VERSION ""

NS_ :

BS_:

BU_:

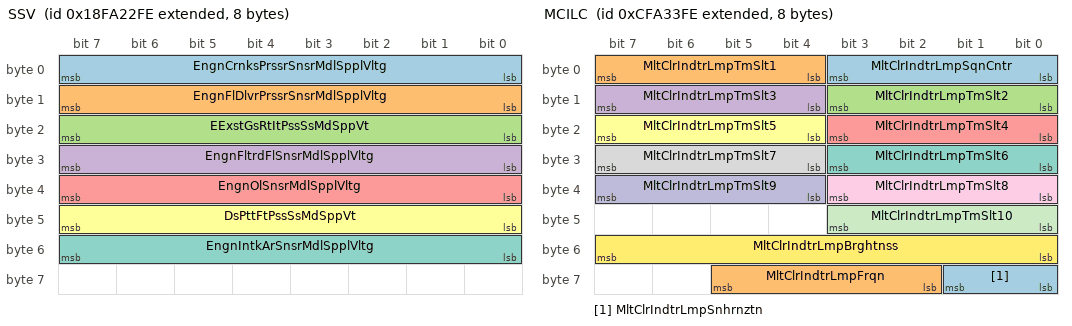
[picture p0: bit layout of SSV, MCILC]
BO_ 2566529790 SSV: 8 Vector__XXX
 SG_ EngnCrnksPrssrSnsrMdlSpplVltg : 0|8@1+ (0.05,0) [0|12.5] "V" Vector__XXX
 SG_ EngnFlDlvrPrssrSnsrMdlSpplVltg : 8|8@1+ (0.05,0) [0|12.5] "V" Vector__XXX
 SG_ EExstGsRtItPssSsMdSppVt : 16|8@1+ (0.05,0) [0|12.5] "V" Vector__XXX
 SG_ EngnFltrdFlSnsrMdlSpplVltg : 24|8@1+ (0.05,0) [0|12.5] "V" Vector__XXX
 SG_ EngnOlSnsrMdlSpplVltg : 32|8@1+ (0.05,0) [0|12.5] "V" Vector__XXX
 SG_ DsPttFtPssSsMdSppVt : 40|8@1+ (0.05,0) [0|12.5] "V" Vector__XXX
 SG_ EngnIntkArSnsrMdlSpplVltg : 48|8@1+ (0.05,0) [0|12.5] "V" Vector__XXX

BO_ 2365207550 MCILC: 8 Vector__XXX
 SG_ MltClrIndtrLmpSqnCntr : 0|4@1+ (1,0) [0|13] "count" Vector__XXX
 SG_ MltClrIndtrLmpTmSlt1 : 4|4@1+ (1,0) [0|15] "" Vector__XXX
 SG_ MltClrIndtrLmpTmSlt2 : 8|4@1+ (1,0) [0|15] "" Vector__XXX
 SG_ MltClrIndtrLmpTmSlt3 : 12|4@1+ (1,0) [0|15] "" Vector__XXX
 SG_ MltClrIndtrLmpTmSlt4 : 16|4@1+ (1,0) [0|15] "" Vector__XXX
 SG_ MltClrIndtrLmpTmSlt5 : 20|4@1+ (1,0) [0|15] "" Vector__XXX
 SG_ MltClrIndtrLmpTmSlt6 : 24|4@1+ (1,0) [0|15] "" Vector__XXX
 SG_ MltClrIndtrLmpTmSlt7 : 28|4@1+ (1,0) [0|15] "" Vector__XXX
 SG_ MltClrIndtrLmpTmSlt8 : 32|4@1+ (1,0) [0|15] "" Vector__XXX
 SG_ MltClrIndtrLmpTmSlt9 : 36|4@1+ (1,0) [0|15] "" Vector__XXX
 SG_ MltClrIndtrLmpTmSlt10 : 40|4@1+ (1,0) [0|15] "" Vector__XXX
 SG_ MltClrIndtrLmpBrghtnss : 48|8@1+ (1,0) [0|100] "%" Vector__XXX
 SG_ MltClrIndtrLmpSnhrnztn : 56|2@1+ (1,0) [0|3] "" Vector__XXX
 SG_ MltClrIndtrLmpFrqn : 58|4@1+ (1,0) [0|15] "" Vector__XXX

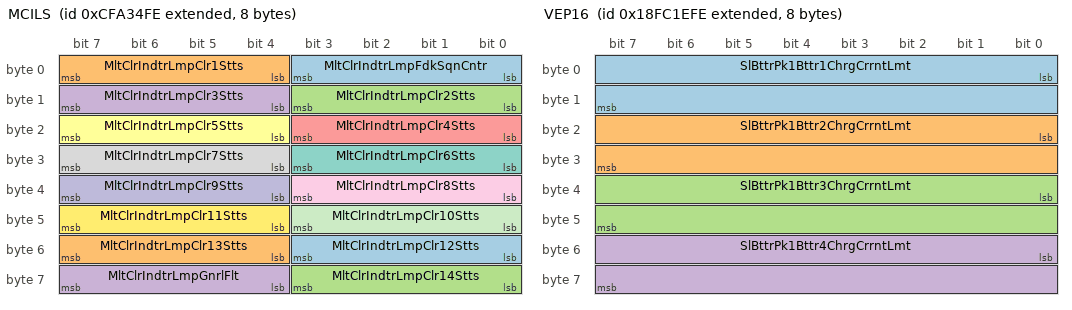
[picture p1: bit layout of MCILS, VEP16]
BO_ 2365207806 MCILS: 8 Vector__XXX
 SG_ MltClrIndtrLmpFdkSqnCntr : 0|4@1+ (1,0) [0|13] "count" Vector__XXX
 SG_ MltClrIndtrLmpClr1Stts : 4|4@1+ (1,0) [0|15] "" Vector__XXX
 SG_ MltClrIndtrLmpClr2Stts : 8|4@1+ (1,0) [0|15] "" Vector__XXX
 SG_ MltClrIndtrLmpClr3Stts : 12|4@1+ (1,0) [0|15] "" Vector__XXX
 SG_ MltClrIndtrLmpClr4Stts : 16|4@1+ (1,0) [0|15] "" Vector__XXX
 SG_ MltClrIndtrLmpClr5Stts : 20|4@1+ (1,0) [0|15] "" Vector__XXX
 SG_ MltClrIndtrLmpClr6Stts : 24|4@1+ (1,0) [0|15] "" Vector__XXX
 SG_ MltClrIndtrLmpClr7Stts : 28|4@1+ (1,0) [0|15] "" Vector__XXX
 SG_ MltClrIndtrLmpClr8Stts : 32|4@1+ (1,0) [0|15] "" Vector__XXX
 SG_ MltClrIndtrLmpClr9Stts : 36|4@1+ (1,0) [0|15] "" Vector__XXX
 SG_ MltClrIndtrLmpClr10Stts : 40|4@1+ (1,0) [0|15] "" Vector__XXX
 SG_ MltClrIndtrLmpClr11Stts : 44|4@1+ (1,0) [0|15] "" Vector__XXX
 SG_ MltClrIndtrLmpClr12Stts : 48|4@1+ (1,0) [0|15] "" Vector__XXX
 SG_ MltClrIndtrLmpClr13Stts : 52|4@1+ (1,0) [0|15] "" Vector__XXX
 SG_ MltClrIndtrLmpClr14Stts : 56|4@1+ (1,0) [0|15] "" Vector__XXX
 SG_ MltClrIndtrLmpGnrlFlt : 60|4@1+ (1,0) [0|15] "" Vector__XXX

BO_ 2566648574 EFS3: 8 Vector__XXX
 SG_ EngnFlFltrDffrntlPrssrHghRsltn : 0|16@1+ (0.01,0) [0|642.55] "kPa" Vector__XXX
 SG_ EFFtStSdDtPssHRst : 16|16@1+ (0.03125,-273) [-273|1734.96875] "degC" Vector__XXX

BO_ 2633761022 TWBW: 16 Vector__XXX
 SG_ BrkWrLfRmnngTrlrAxl1LftWhl : 0|8@1+ (0.4,0) [0|100] "%" Vector__XXX
 SG_ BrkWrLfRmnngTrlrAxl1RghtWhl : 8|8@1+ (0.4,0) [0|100] "%" Vector__XXX
 SG_ BrkWrLfRmnngTrlrAxl2LftWhl : 16|8@1+ (0.4,0) [0|100] "%" Vector__XXX
 SG_ BrkWrLfRmnngTrlrAxl2RghtWhl : 24|8@1+ (0.4,0) [0|100] "%" Vector__XXX
 SG_ BrkWrLfRmnngTrlrAxl3LftWhl : 32|8@1+ (0.4,0) [0|100] "%" Vector__XXX
 SG_ BrkWrLfRmnngTrlrAxl3RghtWhl : 40|8@1+ (0.4,0) [0|100] "%" Vector__XXX
 SG_ BrkWrLfRmnngTrlrAxl4LftWhl : 48|8@1+ (0.4,0) [0|100] "%" Vector__XXX
 SG_ BrkWrLfRmnngTrlrAxl4RghtWhl : 56|8@1+ (0.4,0) [0|100] "%" Vector__XXX
 SG_ BrkWrLfRmnngTrlrAxl5LftWhl : 64|8@1+ (0.4,0) [0|100] "%" Vector__XXX
 SG_ BrkWrLfRmnngTrlrAxl5RghtWhl : 72|8@1+ (0.4,0) [0|100] "%" Vector__XXX
 SG_ BrkWrLfRmnngTrlrAxl6LftWhl : 80|8@1+ (0.4,0) [0|100] "%" Vector__XXX
 SG_ BrkWrLfRmnngTrlrAxl6RghtWhl : 88|8@1+ (0.4,0) [0|100] "%" Vector__XXX
 SG_ BrkWrLfRmnngTrlrAxl7LftWhl : 96|8@1+ (0.4,0) [0|100] "%" Vector__XXX
 SG_ BrkWrLfRmnngTrlrAxl7RghtWhl : 104|8@1+ (0.4,0) [0|100] "%" Vector__XXX
 SG_ BrkWrLfRmnngTrlrAxl8LftWhl : 112|8@1+ (0.4,0) [0|100] "%" Vector__XXX
 SG_ BrkWrLfRmnngTrlrAxl8RghtWhl : 120|8@1+ (0.4,0) [0|100] "%" Vector__XXX

BO_ 2566659838 VEP16: 8 Vector__XXX
 SG_ SlBttrPk1Bttr1ChrgCrrntLmt : 0|16@1+ (0.05,-1600) [0|1600] "A" Vector__XXX
 SG_ SlBttrPk1Bttr2ChrgCrrntLmt : 16|16@1+ (0.05,-1600) [0|1600] "A" Vector__XXX
 SG_ SlBttrPk1Bttr3ChrgCrrntLmt : 32|16@1+ (0.05,-1600) [0|1600] "A" Vector__XXX
 SG_ SlBttrPk1Bttr4ChrgCrrntLmt : 48|16@1+ (0.05,-1600) [0|1600] "A" Vector__XXX

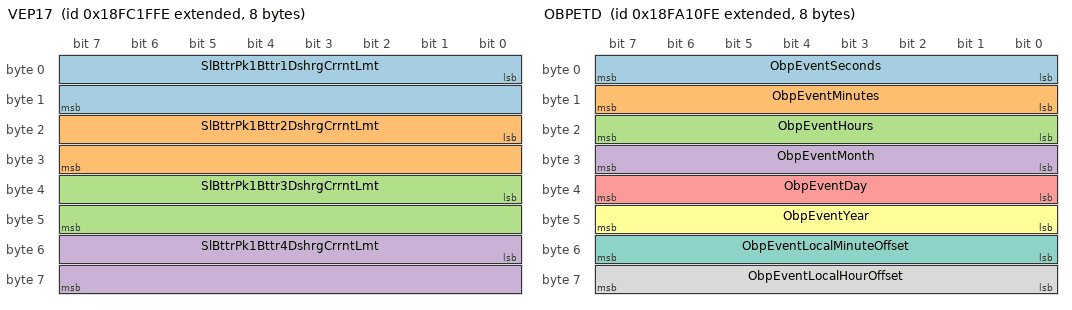
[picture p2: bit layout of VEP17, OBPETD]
BO_ 2566660094 VEP17: 8 Vector__XXX
 SG_ SlBttrPk1Bttr1DshrgCrrntLmt : 0|16@1+ (0.05,-1600) [-1600|0] "A" Vector__XXX
 SG_ SlBttrPk1Bttr2DshrgCrrntLmt : 16|16@1+ (0.05,-1600) [-1600|0] "A" Vector__XXX
 SG_ SlBttrPk1Bttr3DshrgCrrntLmt : 32|16@1+ (0.05,-1600) [-1600|0] "A" Vector__XXX
 SG_ SlBttrPk1Bttr4DshrgCrrntLmt : 48|16@1+ (0.05,-1600) [-1600|0] "A" Vector__XXX

BO_ 2565904382 MG1ITPS: 8 Vector__XXX
 SG_ MtrGnrtr1InvrtrThrmlCpltUsd : 0|8@1+ (0.4,0) [0|100] "%" Vector__XXX
 SG_ MtrGnrtr1InvrtrThrmlCpltLmt : 8|8@1+ (0.4,0) [0|100] "%" Vector__XXX

BO_ 2565904638 MG2ITPS: 8 Vector__XXX
 SG_ MtrGnrtr2InvrtrThrmlCpltUsd : 0|8@1+ (0.4,0) [0|100] "%" Vector__XXX
 SG_ MtrGnrtr2InvrtrThrmlCpltLmt : 8|8@1+ (0.4,0) [0|100] "%" Vector__XXX

BO_ 2565904894 MG3ITPS: 8 Vector__XXX
 SG_ MtrGnrtr3InvrtrThrmlCpltUsd : 0|8@1+ (0.4,0) [0|100] "%" Vector__XXX
 SG_ MtrGnrtr3InvrtrThrmlCpltLmt : 8|8@1+ (0.4,0) [0|100] "%" Vector__XXX

BO_ 2565905150 MG4ITPS: 8 Vector__XXX
 SG_ MtrGnrtr4InvrtrThrmlCpltUsd : 0|8@1+ (0.4,0) [0|100] "%" Vector__XXX
 SG_ MtrGnrtr4InvrtrThrmlCpltLmt : 8|8@1+ (0.4,0) [0|100] "%" Vector__XXX

BO_ 2565905406 MG5ITPS: 8 Vector__XXX
 SG_ MtrGnrtr5InvrtrThrmlCpltUsd : 0|8@1+ (0.4,0) [0|100] "%" Vector__XXX
 SG_ MtrGnrtr5InvrtrThrmlCpltLmt : 8|8@1+ (0.4,0) [0|100] "%" Vector__XXX

BO_ 2565905662 MG6ITPS: 8 Vector__XXX
 SG_ MtrGnrtr6InvrtrThrmlCpltUsd : 0|8@1+ (0.4,0) [0|100] "%" Vector__XXX
 SG_ MtrGnrtr6InvrtrThrmlCpltLmt : 8|8@1+ (0.4,0) [0|100] "%" Vector__XXX

BO_ 2565918462 ETCC4: 8 Vector__XXX
 SG_ EngnTrhrgrWstgtAttr3Cmmnd : 0|16@1+ (0.0025,0) [0|160.6375] "%" Vector__XXX
 SG_ EngnTrhrgrWstgtAttr4Cmmnd : 16|16@1+ (0.0025,0) [0|160.6375] "%" Vector__XXX

BO_ 2565918718 ETWAI2: 8 Vector__XXX
 SG_ EngnTrhrgrWstgtAttr3OprtnStts : 0|4@1+ (1,0) [0|15] "" Vector__XXX
 SG_ EngnTrhrgrWstgtAttr4OprtnStts : 4|4@1+ (1,0) [0|15] "" Vector__XXX

BO_ 2566523646 MG1TPS: 8 Vector__XXX
 SG_ MtrGnrtr1ThrmlCpltUsd : 0|8@1+ (0.4,0) [0|100] "%" Vector__XXX
 SG_ MtrGnrtr1ThrmlCpltLmt : 8|8@1+ (0.4,0) [0|100] "%" Vector__XXX

BO_ 2566523902 MG2TPS: 8 Vector__XXX
 SG_ MtrGnrtr2ThrmlCpltUsd : 0|8@1+ (0.4,0) [0|100] "%" Vector__XXX
 SG_ MtrGnrtr2ThrmlCpltLmt : 8|8@1+ (0.4,0) [0|100] "%" Vector__XXX

BO_ 2566524158 MG3TPS: 8 Vector__XXX
 SG_ MtrGnrtr3ThrmlCpltUsd : 0|8@1+ (0.4,0) [0|100] "%" Vector__XXX
 SG_ MtrGnrtr3ThrmlCpltLmt : 8|8@1+ (0.4,0) [0|100] "%" Vector__XXX

BO_ 2566524414 MG4TPS: 8 Vector__XXX
 SG_ MtrGnrtr4ThrmlCpltUsd : 0|8@1+ (0.4,0) [0|100] "%" Vector__XXX
 SG_ MtrGnrtr4ThrmlCpltLmt : 8|8@1+ (0.4,0) [0|100] "%" Vector__XXX

BO_ 2566524670 MG5TPS: 8 Vector__XXX
 SG_ MtrGnrtr5ThrmlCpltUsd : 0|8@1+ (0.4,0) [0|100] "%" Vector__XXX
 SG_ MtrGnrtr5ThrmlCpltLmt : 8|8@1+ (0.4,0) [0|100] "%" Vector__XXX

BO_ 2566524926 MG6TPS: 8 Vector__XXX
 SG_ MtrGnrtr6ThrmlCpltUsd : 0|8@1+ (0.4,0) [0|100] "%" Vector__XXX
 SG_ MtrGnrtr6ThrmlCpltLmt : 8|8@1+ (0.4,0) [0|100] "%" Vector__XXX

BO_ 2566525182 OBPETD: 8 Vector__XXX
 SG_ ObpEventSeconds : 0|8@1+ (0.25,0) [0|59.75] "s" Vector__XXX
 SG_ ObpEventMinutes : 8|8@1+ (1,0) [0|59] "min" Vector__XXX
 SG_ ObpEventHours : 16|8@1+ (1,0) [0|23] "h" Vector__XXX
 SG_ ObpEventMonth : 24|8@1+ (1,0) [1|12] "month" Vector__XXX
 SG_ ObpEventDay : 32|8@1+ (0.25,0) [0.25|31.75] "days" Vector__XXX
 SG_ ObpEventYear : 40|8@1+ (1,1985) [1985|2235] "year" Vector__XXX
 SG_ ObpEventLocalMinuteOffset : 48|8@1+ (1,-125) [-59|59] "min" Vector__XXX
 SG_ ObpEventLocalHourOffset : 56|8@1+ (1,-125) [-23|23] "h" Vector__XXX

BO_ 2566525438 A1LOSCRSI1: 8 Vector__XXX
 SG_ Atttt1TtLtOSDsExstFdUsd : 0|32@1+ (0.05,0) [0|210554060.75] "l" Vector__XXX
 SG_ Atttt1TpLtOSDsExstFd : 32|32@1+ (0.05,0) [0|210554060.75] "l" Vector__XXX

BO_ 2566525950 CSERSC: 20 Vector__XXX
 SG_ CtCCtstHtEUtFtpCdSttTT : 0|16@1+ (1,0) [0|64255] "kJ" Vector__XXX
 SG_ CtCCtstHtEUtFtpEOtptE : 16|16@1+ (1,0) [0|64255] "kJ" Vector__XXX
 SG_ CtCCtstHtEUtCtstCdSttTTptTsd : 32|16@1+ (1,0) [0|64255] "kJ" Vector__XXX
 SG_ CtCEOtptEUtFtpCdSttTT : 48|16@1+ (5,0) [0|321275] "kJ" Vector__XXX
 SG_ CtCEOtptEUtCtstCdSttTTptTsd : 64|16@1+ (5,0) [0|321275] "kJ" Vector__XXX
 SG_ CtCEMssUtFtpCdSttTT : 80|16@1+ (5,0) [0|321275] "g" Vector__XXX
 SG_ CtCEMssUtFtpEOtptE : 96|16@1+ (5,0) [0|321275] "g" Vector__XXX
 SG_ CtCEMssUtCdSttTCtstTptTsd : 112|16@1+ (5,0) [0|321275] "g" Vector__XXX
 SG_ CrrntClTmUntlFtpEngnOtptEnrg : 128|16@1+ (1,0) [0|64255] "s" Vector__XXX
 SG_ CtCTUtCtstCdSttTTptTsd : 144|16@1+ (1,0) [0|64255] "s" Vector__XXX

BO_ 2566526206 CSERSA: 20 Vector__XXX
 SG_ AvCtstHtEUtFtpCdSttTT : 0|16@1+ (1,0) [0|64255] "kJ" Vector__XXX
 SG_ AvCtstHtEUtFtpEOtptE : 16|16@1+ (1,0) [0|64255] "kJ" Vector__XXX
 SG_ AvCtstHtEUtCtstCdSttTTptTsd : 32|16@1+ (1,0) [0|64255] "kJ" Vector__XXX
 SG_ AvEOtptEUtFtpCdSttTT : 48|16@1+ (5,0) [0|321275] "kJ" Vector__XXX
 SG_ AvEOtptEUtCdSttTCtstTptTsd : 64|16@1+ (5,0) [0|321275] "kJ" Vector__XXX
 SG_ AvrgEgrMssAtFtpCldStrtTrkngTm : 80|16@1+ (5,0) [0|321275] "g" Vector__XXX
 SG_ AvrgEgrMssAtFtpEngnOtptEnrg : 96|16@1+ (5,0) [0|321275] "g" Vector__XXX
 SG_ AvEMssUtFtpCdSttTCtstTpt : 112|16@1+ (5,0) [0|321275] "g" Vector__XXX
 SG_ AvrgTmUntlFtpEngnOtptEnrg : 128|16@1+ (1,0) [0|64255] "s" Vector__XXX
 SG_ AvTUtCtstCdSttTTpt : 144|16@1+ (1,0) [0|64255] "s" Vector__XXX

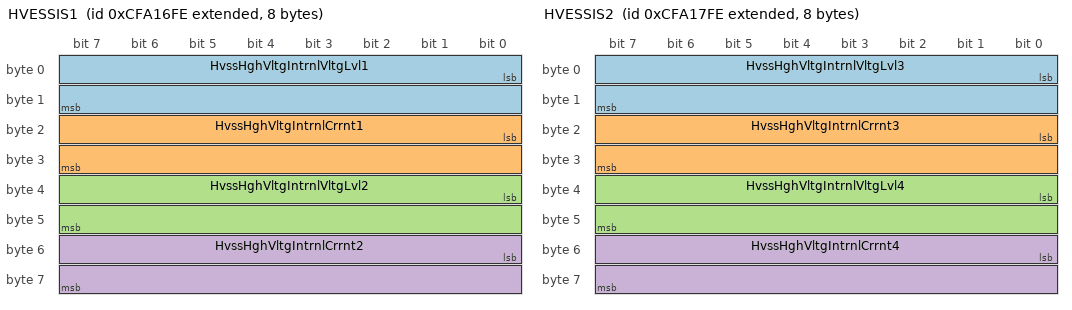
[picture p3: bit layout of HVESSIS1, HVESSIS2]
BO_ 2365200126 HVESSIS1: 8 Vector__XXX
 SG_ HvssHghVltgIntrnlVltgLvl1 : 0|16@1+ (0.125,0) [0|8031.875] "V" Vector__XXX
 SG_ HvssHghVltgIntrnlCrrnt1 : 16|16@1+ (0.125,-4000) [-4000|4031.875] "A" Vector__XXX
 SG_ HvssHghVltgIntrnlVltgLvl2 : 32|16@1+ (0.125,0) [0|8031.875] "V" Vector__XXX
 SG_ HvssHghVltgIntrnlCrrnt2 : 48|16@1+ (0.125,-4000) [-4000|4031.875] "A" Vector__XXX

BO_ 2365200382 HVESSIS2: 8 Vector__XXX
 SG_ HvssHghVltgIntrnlVltgLvl3 : 0|16@1+ (0.125,0) [0|8031.875] "V" Vector__XXX
 SG_ HvssHghVltgIntrnlCrrnt3 : 16|16@1+ (0.125,-4000) [-4000|4031.875] "A" Vector__XXX
 SG_ HvssHghVltgIntrnlVltgLvl4 : 32|16@1+ (0.125,0) [0|8031.875] "V" Vector__XXX
 SG_ HvssHghVltgIntrnlCrrnt4 : 48|16@1+ (0.125,-4000) [-4000|4031.875] "A" Vector__XXX

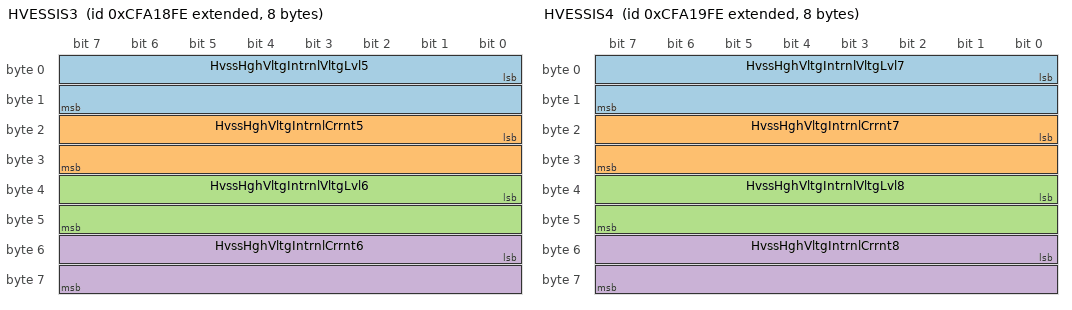
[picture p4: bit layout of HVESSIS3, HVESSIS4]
BO_ 2365200638 HVESSIS3: 8 Vector__XXX
 SG_ HvssHghVltgIntrnlVltgLvl5 : 0|16@1+ (0.125,0) [0|8031.875] "V" Vector__XXX
 SG_ HvssHghVltgIntrnlCrrnt5 : 16|16@1+ (0.125,-4000) [-4000|4031.875] "A" Vector__XXX
 SG_ HvssHghVltgIntrnlVltgLvl6 : 32|16@1+ (0.125,0) [0|8031.875] "V" Vector__XXX
 SG_ HvssHghVltgIntrnlCrrnt6 : 48|16@1+ (0.125,-4000) [-4000|4031.875] "A" Vector__XXX

BO_ 2365200894 HVESSIS4: 8 Vector__XXX
 SG_ HvssHghVltgIntrnlVltgLvl7 : 0|16@1+ (0.125,0) [0|8031.875] "V" Vector__XXX
 SG_ HvssHghVltgIntrnlCrrnt7 : 16|16@1+ (0.125,-4000) [-4000|4031.875] "A" Vector__XXX
 SG_ HvssHghVltgIntrnlVltgLvl8 : 32|16@1+ (0.125,0) [0|8031.875] "V" Vector__XXX
 SG_ HvssHghVltgIntrnlCrrnt8 : 48|16@1+ (0.125,-4000) [-4000|4031.875] "A" Vector__XXX

BO_ 2432310014 EEC23: 8 Vector__XXX
 SG_ EngnCrnksPrssrCntrlAttr1Cmmnd : 0|16@1+ (0.0025,0) [0|160.6375] "%" Vector__XXX
 SG_ EngnCrnksPrssrCntrlAttr2Cmmnd : 16|16@1+ (0.0025,0) [0|160.6375] "%" Vector__XXX

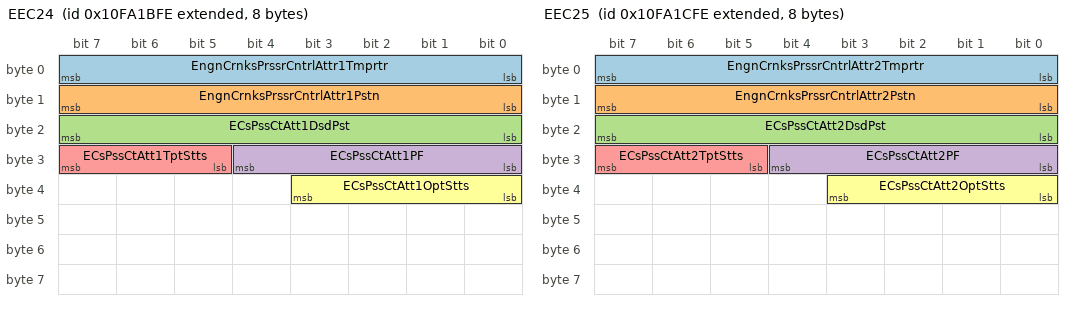
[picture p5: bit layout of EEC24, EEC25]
BO_ 2432310270 EEC24: 8 Vector__XXX
 SG_ EngnCrnksPrssrCntrlAttr1Tmprtr : 0|8@1+ (1,-40) [-40|210] "degC" Vector__XXX
 SG_ EngnCrnksPrssrCntrlAttr1Pstn : 8|8@1+ (0.4,0) [0|100] "%" Vector__XXX
 SG_ ECsPssCtAtt1DsdPst : 16|8@1+ (0.4,0) [0|100] "%" Vector__XXX
 SG_ ECsPssCtAtt1PF : 24|5@1+ (1,0) [0|31] "" Vector__XXX
 SG_ ECsPssCtAtt1TptStts : 29|3@1+ (1,0) [0|7] "" Vector__XXX
 SG_ ECsPssCtAtt1OptStts : 32|4@1+ (1,0) [0|15] "" Vector__XXX

BO_ 2432310526 EEC25: 8 Vector__XXX
 SG_ EngnCrnksPrssrCntrlAttr2Tmprtr : 0|8@1+ (1,-40) [-40|210] "degC" Vector__XXX
 SG_ EngnCrnksPrssrCntrlAttr2Pstn : 8|8@1+ (0.4,0) [0|100] "%" Vector__XXX
 SG_ ECsPssCtAtt2DsdPst : 16|8@1+ (0.4,0) [0|100] "%" Vector__XXX
 SG_ ECsPssCtAtt2PF : 24|5@1+ (1,0) [0|31] "" Vector__XXX
 SG_ ECsPssCtAtt2TptStts : 29|3@1+ (1,0) [0|7] "" Vector__XXX
 SG_ ECsPssCtAtt2OptStts : 32|4@1+ (1,0) [0|15] "" Vector__XXX

BO_ 2365201918 HVBCC1: 8 Vector__XXX
 SG_ HghVltgBsIntrf1CnntCmmnd : 0|2@1+ (1,0) [0|3] "" Vector__XXX
 SG_ HghVltgBsIntrf2CnntCmmnd : 2|2@1+ (1,0) [0|3] "" Vector__XXX
 SG_ HghVltgBsIntrf3CnntCmmnd : 4|2@1+ (1,0) [0|3] "" Vector__XXX
 SG_ HghVltgBsIntrf4CnntCmmnd : 6|2@1+ (1,0) [0|3] "" Vector__XXX
 SG_ HghVltgBsIntrf5CnntCmmnd : 8|2@1+ (1,0) [0|3] "" Vector__XXX
 SG_ HghVltgBsIntrf6CnntCmmnd : 10|2@1+ (1,0) [0|3] "" Vector__XXX
 SG_ HghVltgBsIntrf7CnntCmmnd : 12|2@1+ (1,0) [0|3] "" Vector__XXX
 SG_ HghVltgBsIntrf8CnntCmmnd : 14|2@1+ (1,0) [0|3] "" Vector__XXX
 SG_ HghVltgBsIntrf9CnntCmmnd : 16|2@1+ (1,0) [0|3] "" Vector__XXX
 SG_ HghVltgBsIntrf10CnntCmmnd : 18|2@1+ (1,0) [0|3] "" Vector__XXX
 SG_ HghVltgBsIntrf11CnntCmmnd : 20|2@1+ (1,0) [0|3] "" Vector__XXX
 SG_ HghVltgBsIntrf12CnntCmmnd : 22|2@1+ (1,0) [0|3] "" Vector__XXX
 SG_ HghVltgBsIntrf13CnntCmmnd : 24|2@1+ (1,0) [0|3] "" Vector__XXX
 SG_ HghVltgBsIntrf14CnntCmmnd : 26|2@1+ (1,0) [0|3] "" Vector__XXX
 SG_ HghVltgBsIntrf15CnntCmmnd : 28|2@1+ (1,0) [0|3] "" Vector__XXX
 SG_ HghVltgBsIntrf16CnntCmmnd : 30|2@1+ (1,0) [0|3] "" Vector__XXX
 SG_ HghVltgBsIntrf17CnntCmmnd : 32|2@1+ (1,0) [0|3] "" Vector__XXX
 SG_ HghVltgBsIntrf18CnntCmmnd : 34|2@1+ (1,0) [0|3] "" Vector__XXX
 SG_ HghVltgBsIntrf19CnntCmmnd : 36|2@1+ (1,0) [0|3] "" Vector__XXX
 SG_ HghVltgBsIntrf20CnntCmmnd : 38|2@1+ (1,0) [0|3] "" Vector__XXX
 SG_ HghVltgBsIntrf21CnntCmmnd : 40|2@1+ (1,0) [0|3] "" Vector__XXX
 SG_ HghVltgBsIntrf22CnntCmmnd : 42|2@1+ (1,0) [0|3] "" Vector__XXX
 SG_ HghVltgBsIntrf23CnntCmmnd : 44|2@1+ (1,0) [0|3] "" Vector__XXX
 SG_ HghVltgBsIntrf24CnntCmmnd : 46|2@1+ (1,0) [0|3] "" Vector__XXX
 SG_ Hvbcc1EmbeddedIntegritySupport : 50|2@1+ (1,0) [0|3] "" Vector__XXX
 SG_ Hvbcc1Counter : 52|4@1+ (1,0) [0|15] "" Vector__XXX
 SG_ Hvbcc1Crc : 56|8@1+ (1,0) [0|250] "count" Vector__XXX

BO_ 2365202174 HVBCS1: 8 Vector__XXX
 SG_ HghVltgBsIntrf1PstvCnttrStt : 0|2@1+ (1,0) [0|3] "" Vector__XXX
 SG_ HghVltgBsIntrf1NgtvCnttrStt : 2|2@1+ (1,0) [0|3] "" Vector__XXX
 SG_ HghVltgBsIntrf2PstvCnttrStt : 4|2@1+ (1,0) [0|3] "" Vector__XXX
 SG_ HghVltgBsIntrf2NgtvCnttrStt : 6|2@1+ (1,0) [0|3] "" Vector__XXX
 SG_ HghVltgBsIntrf3PstvCnttrStt : 8|2@1+ (1,0) [0|3] "" Vector__XXX
 SG_ HghVltgBsIntrf3NgtvCnttrStt : 10|2@1+ (1,0) [0|3] "" Vector__XXX
 SG_ HghVltgBsIntrf4PstvCnttrStt : 12|2@1+ (1,0) [0|3] "" Vector__XXX
 SG_ HghVltgBsIntrf4NgtvCnttrStt : 14|2@1+ (1,0) [0|3] "" Vector__XXX
 SG_ HghVltgBsIntrf5PstvCnttrStt : 16|2@1+ (1,0) [0|3] "" Vector__XXX
 SG_ HghVltgBsIntrf5NgtvCnttrStt : 18|2@1+ (1,0) [0|3] "" Vector__XXX
 SG_ HghVltgBsIntrf6PstvCnttrStt : 20|2@1+ (1,0) [0|3] "" Vector__XXX
 SG_ HghVltgBsIntrf6NgtvCnttrStt : 22|2@1+ (1,0) [0|3] "" Vector__XXX
 SG_ HghVltgBsIntrf7PstvCnttrStt : 24|2@1+ (1,0) [0|3] "" Vector__XXX
 SG_ HghVltgBsIntrf7NgtvCnttrStt : 26|2@1+ (1,0) [0|3] "" Vector__XXX
 SG_ HghVltgBsIntrf8PstvCnttrStt : 28|2@1+ (1,0) [0|3] "" Vector__XXX
 SG_ HghVltgBsIntrf8NgtvCnttrStt : 30|2@1+ (1,0) [0|3] "" Vector__XXX
 SG_ Hvbcs1EmbeddedIntegritySupport : 50|2@1+ (1,0) [0|3] "" Vector__XXX
 SG_ Hvbcs1Counter : 52|4@1+ (1,0) [0|15] "" Vector__XXX
 SG_ Hvbcs1Crc : 56|8@1+ (1,0) [0|250] "count" Vector__XXX

BO_ 2365333758 HVESSMS2: 8 Vector__XXX
 SG_ HvessModule33OperationalStatus : 0|2@1+ (1,0) [0|3] "" Vector__XXX
 SG_ HvessModule34OperationalStatus : 2|2@1+ (1,0) [0|3] "" Vector__XXX
 SG_ HvessModule35OperationalStatus : 4|2@1+ (1,0) [0|3] "" Vector__XXX
 SG_ HvessModule36OperationalStatus : 6|2@1+ (1,0) [0|3] "" Vector__XXX
 SG_ HvessModule37OperationalStatus : 8|2@1+ (1,0) [0|3] "" Vector__XXX
 SG_ HvessModule38OperationalStatus : 10|2@1+ (1,0) [0|3] "" Vector__XXX
 SG_ HvessModule39OperationalStatus : 12|2@1+ (1,0) [0|3] "" Vector__XXX
 SG_ HvessModule40OperationalStatus : 14|2@1+ (1,0) [0|3] "" Vector__XXX
 SG_ HvessModule41OperationalStatus : 16|2@1+ (1,0) [0|3] "" Vector__XXX
 SG_ HvessModule42OperationalStatus : 18|2@1+ (1,0) [0|3] "" Vector__XXX
 SG_ HvessModule43OperationalStatus : 20|2@1+ (1,0) [0|3] "" Vector__XXX
 SG_ HvessModule44OperationalStatus : 22|2@1+ (1,0) [0|3] "" Vector__XXX
 SG_ HvessModule45OperationalStatus : 24|2@1+ (1,0) [0|3] "" Vector__XXX
 SG_ HvessModule46OperationalStatus : 26|2@1+ (1,0) [0|3] "" Vector__XXX
 SG_ HvessModule47OperationalStatus : 28|2@1+ (1,0) [0|3] "" Vector__XXX
 SG_ HvessModule48OperationalStatus : 30|2@1+ (1,0) [0|3] "" Vector__XXX
 SG_ HvessModule49OperationalStatus : 32|2@1+ (1,0) [0|3] "" Vector__XXX
 SG_ HvessModule50OperationalStatus : 34|2@1+ (1,0) [0|3] "" Vector__XXX
 SG_ HvessModule51OperationalStatus : 36|2@1+ (1,0) [0|3] "" Vector__XXX
 SG_ HvessModule52OperationalStatus : 38|2@1+ (1,0) [0|3] "" Vector__XXX
 SG_ HvessModule53OperationalStatus : 40|2@1+ (1,0) [0|3] "" Vector__XXX
 SG_ HvessModule54OperationalStatus : 42|2@1+ (1,0) [0|3] "" Vector__XXX
 SG_ HvessModule55OperationalStatus : 44|2@1+ (1,0) [0|3] "" Vector__XXX
 SG_ HvessModule56OperationalStatus : 46|2@1+ (1,0) [0|3] "" Vector__XXX
 SG_ HvessModule57OperationalStatus : 48|2@1+ (1,0) [0|3] "" Vector__XXX
 SG_ HvessModule58OperationalStatus : 50|2@1+ (1,0) [0|3] "" Vector__XXX
 SG_ HvessModule59OperationalStatus : 52|2@1+ (1,0) [0|3] "" Vector__XXX
 SG_ HvessModule60OperationalStatus : 54|2@1+ (1,0) [0|3] "" Vector__XXX
 SG_ HvessModule61OperationalStatus : 56|2@1+ (1,0) [0|3] "" Vector__XXX
 SG_ HvessModule62OperationalStatus : 58|2@1+ (1,0) [0|3] "" Vector__XXX
 SG_ HvessModule63OperationalStatus : 60|2@1+ (1,0) [0|3] "" Vector__XXX
 SG_ HvessModule64OperationalStatus : 62|2@1+ (1,0) [0|3] "" Vector__XXX

BO_ 2365334014 HVESSMS3: 8 Vector__XXX
 SG_ HvessModule65OperationalStatus : 0|2@1+ (1,0) [0|3] "" Vector__XXX
 SG_ HvessModule66OperationalStatus : 2|2@1+ (1,0) [0|3] "" Vector__XXX
 SG_ HvessModule67OperationalStatus : 4|2@1+ (1,0) [0|3] "" Vector__XXX
 SG_ HvessModule68OperationalStatus : 6|2@1+ (1,0) [0|3] "" Vector__XXX
 SG_ HvessModule69OperationalStatus : 8|2@1+ (1,0) [0|3] "" Vector__XXX
 SG_ HvessModule70OperationalStatus : 10|2@1+ (1,0) [0|3] "" Vector__XXX
 SG_ HvessModule71OperationalStatus : 12|2@1+ (1,0) [0|3] "" Vector__XXX
 SG_ HvessModule72OperationalStatus : 14|2@1+ (1,0) [0|3] "" Vector__XXX
 SG_ HvessModule73OperationalStatus : 16|2@1+ (1,0) [0|3] "" Vector__XXX
 SG_ HvessModule74OperationalStatus : 18|2@1+ (1,0) [0|3] "" Vector__XXX
 SG_ HvessModule75OperationalStatus : 20|2@1+ (1,0) [0|3] "" Vector__XXX
 SG_ HvessModule76OperationalStatus : 22|2@1+ (1,0) [0|3] "" Vector__XXX
 SG_ HvessModule77OperationalStatus : 24|2@1+ (1,0) [0|3] "" Vector__XXX
 SG_ HvessModule78OperationalStatus : 26|2@1+ (1,0) [0|3] "" Vector__XXX
 SG_ HvessModule79OperationalStatus : 28|2@1+ (1,0) [0|3] "" Vector__XXX
 SG_ HvessModule80OperationalStatus : 30|2@1+ (1,0) [0|3] "" Vector__XXX
 SG_ HvessModule81OperationalStatus : 32|2@1+ (1,0) [0|3] "" Vector__XXX
 SG_ HvessModule82OperationalStatus : 34|2@1+ (1,0) [0|3] "" Vector__XXX
 SG_ HvessModule83OperationalStatus : 36|2@1+ (1,0) [0|3] "" Vector__XXX
 SG_ HvessModule84OperationalStatus : 38|2@1+ (1,0) [0|3] "" Vector__XXX
 SG_ HvessModule85OperationalStatus : 40|2@1+ (1,0) [0|3] "" Vector__XXX
 SG_ HvessModule86OperationalStatus : 42|2@1+ (1,0) [0|3] "" Vector__XXX
 SG_ HvessModule87OperationalStatus : 44|2@1+ (1,0) [0|3] "" Vector__XXX
 SG_ HvessModule88OperationalStatus : 46|2@1+ (1,0) [0|3] "" Vector__XXX
 SG_ HvessModule89OperationalStatus : 48|2@1+ (1,0) [0|3] "" Vector__XXX
 SG_ HvessModule90OperationalStatus : 50|2@1+ (1,0) [0|3] "" Vector__XXX
 SG_ HvessModule91OperationalStatus : 52|2@1+ (1,0) [0|3] "" Vector__XXX
 SG_ HvessModule92OperationalStatus : 54|2@1+ (1,0) [0|3] "" Vector__XXX
 SG_ HvessModule93OperationalStatus : 56|2@1+ (1,0) [0|3] "" Vector__XXX
 SG_ HvessModule94OperationalStatus : 58|2@1+ (1,0) [0|3] "" Vector__XXX
 SG_ HvessModule95OperationalStatus : 60|2@1+ (1,0) [0|3] "" Vector__XXX
 SG_ HvessModule96OperationalStatus : 62|2@1+ (1,0) [0|3] "" Vector__XXX

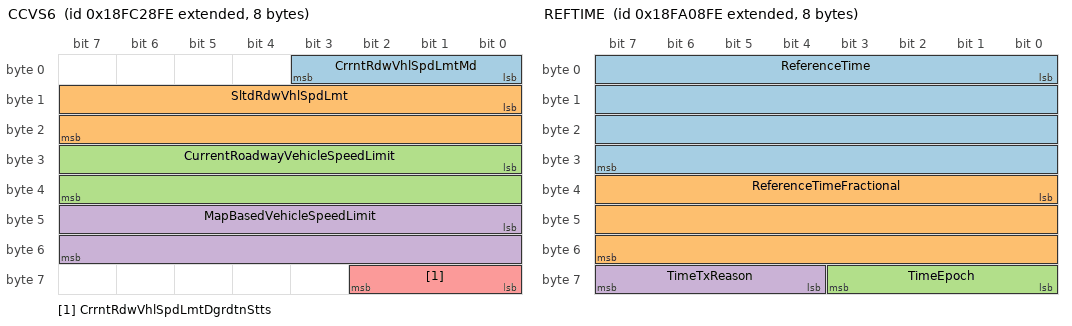
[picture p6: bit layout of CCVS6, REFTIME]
BO_ 2566662398 CCVS6: 8 Vector__XXX
 SG_ CrrntRdwVhlSpdLmtMd : 0|4@1+ (1,0) [0|15] "" Vector__XXX
 SG_ SltdRdwVhlSpdLmt : 8|16@1+ (0.00390625,0) [0|250.99609375] "km/h" Vector__XXX
 SG_ CurrentRoadwayVehicleSpeedLimit : 24|16@1+ (0.00390625,0) [0|250.99609375] "km/h" Vector__XXX
 SG_ MapBasedVehicleSpeedLimit : 40|16@1+ (0.00390625,0) [0|250.99609375] "km/h" Vector__XXX
 SG_ CrrntRdwVhlSpdLmtDgrdtnStts : 56|3@1+ (1,0) [0|7] "" Vector__XXX

BO_ 2365342974 HVESSD15: 8 Vector__XXX
 SG_ HvssNmnlDshrgCrrntLmt : 0|16@1+ (0.125,-4000) [-4000|0] "A" Vector__XXX
 SG_ HvessNominalChargeCurrentLimit : 16|16@1+ (0.125,-4000) [0|4031.875] "A" Vector__XXX

BO_ 2566522622 DD3: 8 Vector__XXX
 SG_ PrdtvVhlSpdAdjstmntIndtrStt : 0|3@1+ (1,0) [0|7] "" Vector__XXX
 SG_ PrdtvVhlSpdAdjstmntSpd : 8|16@1+ (0.00390625,0) [0|250.99609375] "km/h" Vector__XXX

BO_ 2566523134 REFTIME: 8 Vector__XXX
 SG_ ReferenceTime : 0|32@1+ (1,0) [0|4211081215] "s" Vector__XXX
 SG_ ReferenceTimeFractional : 32|24@1+ (1,0) [0|999999] "micro s" Vector__XXX
 SG_ TimeEpoch : 56|4@1+ (1,0) [0|15] "" Vector__XXX
 SG_ TimeTxReason : 60|4@1+ (1,0) [0|15] "" Vector__XXX

BO_ 2566523390 SH: 8 Vector__XXX
 SG_ TotalSoftwareDistance : 0|32@1+ (0.125,0) [0|526385151.875] "km" Vector__XXX

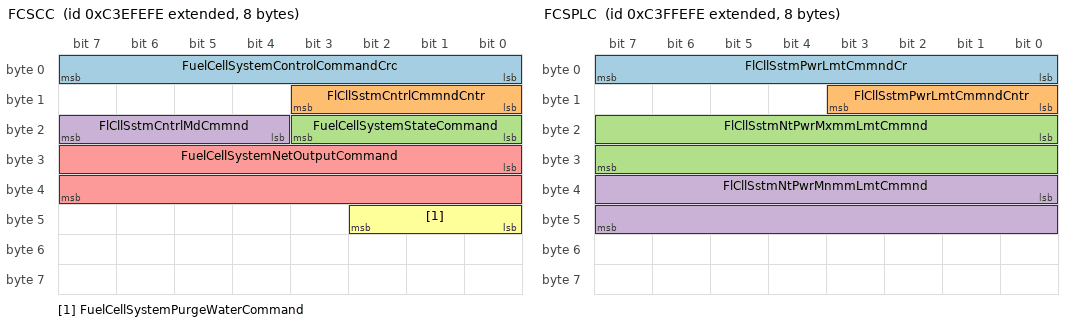
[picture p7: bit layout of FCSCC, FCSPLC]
BO_ 2352938750 FCSCC: 8 Vector__XXX
 SG_ FuelCellSystemControlCommandCrc : 0|8@1+ (1,0) [0|250] "count" Vector__XXX
 SG_ FlCllSstmCntrlCmmndCntr : 8|4@1+ (1,0) [0|15] "" Vector__XXX
 SG_ FuelCellSystemStateCommand : 16|4@1+ (1,0) [0|15] "" Vector__XXX
 SG_ FlCllSstmCntrlMdCmmnd : 20|4@1+ (1,0) [0|15] "" Vector__XXX
 SG_ FuelCellSystemNetOutputCommand : 24|16@1+ (0.00390625,-125) [0|125.99609375] "%" Vector__XXX
 SG_ FuelCellSystemPurgeWaterCommand : 40|3@1+ (1,0) [0|7] "" Vector__XXX

BO_ 2353004286 FCSPLC: 8 Vector__XXX
 SG_ FlCllSstmPwrLmtCmmndCr : 0|8@1+ (1,0) [0|250] "count" Vector__XXX
 SG_ FlCllSstmPwrLmtCmmndCntr : 8|4@1+ (1,0) [0|15] "" Vector__XXX
 SG_ FlCllSstmNtPwrMxmmLmtCmmnd : 16|16@1+ (0.00390625,-125) [0|125.99609375] "%" Vector__XXX
 SG_ FlCllSstmNtPwrMnmmLmtCmmnd : 32|16@1+ (0.00390625,-125) [0|125.99609375] "%" Vector__XXX

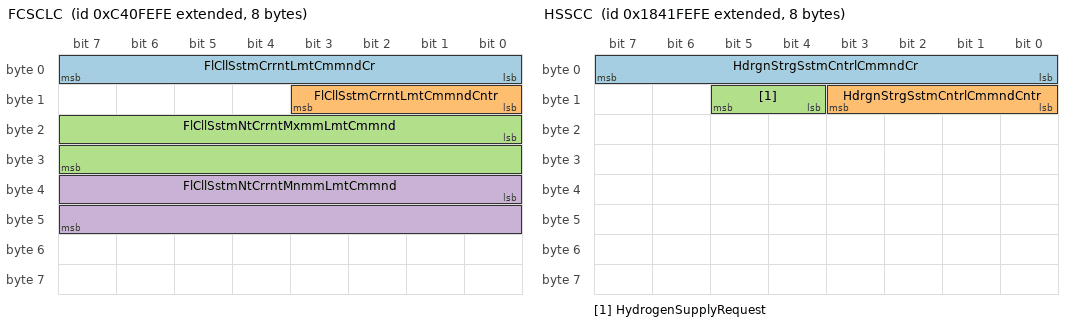
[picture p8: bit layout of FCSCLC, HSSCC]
BO_ 2353069822 FCSCLC: 8 Vector__XXX
 SG_ FlCllSstmCrrntLmtCmmndCr : 0|8@1+ (1,0) [0|250] "count" Vector__XXX
 SG_ FlCllSstmCrrntLmtCmmndCntr : 8|4@1+ (1,0) [0|15] "" Vector__XXX
 SG_ FlCllSstmNtCrrntMxmmLmtCmmnd : 16|16@1+ (0.00390625,-125) [0|125.99609375] "%" Vector__XXX
 SG_ FlCllSstmNtCrrntMnmmLmtCmmnd : 32|16@1+ (0.00390625,-125) [0|125.99609375] "%" Vector__XXX

BO_ 2554461950 HSSCC: 8 Vector__XXX
 SG_ HdrgnStrgSstmCntrlCmmndCr : 0|8@1+ (1,0) [0|250] "count" Vector__XXX
 SG_ HdrgnStrgSstmCntrlCmmndCntr : 8|4@1+ (1,0) [0|15] "" Vector__XXX
 SG_ HydrogenSupplyRequest : 12|2@1+ (1,0) [0|3] "" Vector__XXX

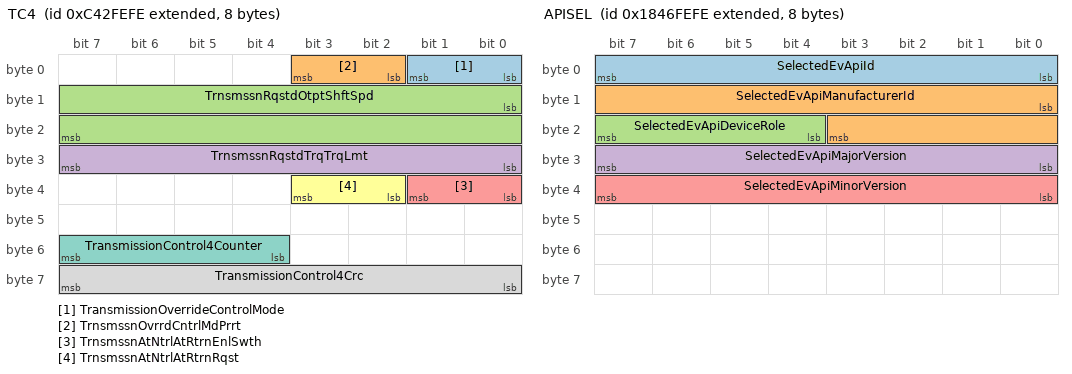
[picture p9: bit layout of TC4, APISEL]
BO_ 2353200894 TC4: 8 Vector__XXX
 SG_ TransmissionOverrideControlMode : 0|2@1+ (1,0) [0|3] "" Vector__XXX
 SG_ TrnsmssnOvrrdCntrlMdPrrt : 2|2@1+ (1,0) [0|3] "" Vector__XXX
 SG_ TrnsmssnRqstdOtptShftSpd : 8|16@1+ (0.25,-8031.75) [-8031.375|8031.75] "rpm" Vector__XXX
 SG_ TrnsmssnRqstdTrqTrqLmt : 24|8@1+ (1,-125) [-125|125] "%" Vector__XXX
 SG_ TrnsmssnAtNtrlAtRtrnEnlSwth : 32|2@1+ (1,0) [0|3] "" Vector__XXX
 SG_ TrnsmssnAtNtrlAtRtrnRqst : 34|2@1+ (1,0) [0|3] "" Vector__XXX
 SG_ TransmissionControl4Counter : 52|4@1+ (1,0) [0|15] "" Vector__XXX
 SG_ TransmissionControl4Crc : 56|8@1+ (1,0) [0|250] "count" Vector__XXX

BO_ 2554789630 APISEL: 8 Vector__XXX
 SG_ SelectedEvApiId : 0|8@1+ (1,0) [0|250] "count" Vector__XXX
 SG_ SelectedEvApiManufacturerId : 8|12@1+ (1,0) [0|4015] "count" Vector__XXX
 SG_ SelectedEvApiDeviceRole : 20|4@1+ (1,0) [0|15] "" Vector__XXX
 SG_ SelectedEvApiMajorVersion : 24|8@1+ (1,0) [0|250] "count" Vector__XXX
 SG_ SelectedEvApiMinorVersion : 32|8@1+ (1,0) [0|250] "count" Vector__XXX

BO_ 2364574206 MG1IS3: 8 Vector__XXX
 SG_ MtrGnrtr1InvrtrCntrlStts3Cr : 0|8@1+ (1,0) [0|250] "count" Vector__XXX
 SG_ MtrGnrtr1InvrtrCntrlStts3Cntr : 8|4@1+ (1,0) [0|15] "" Vector__XXX
 SG_ MotorGenerator1MotorAngle : 16|16@1+ (0.0078125,0) [0|359.9921875] "deg" Vector__XXX

BO_ 2364574462 MG2IS3: 8 Vector__XXX
 SG_ MtrGnrtr2InvrtrCntrlStts3Cr : 0|8@1+ (1,0) [0|250] "count" Vector__XXX
 SG_ MtrGnrtr2InvrtrCntrlStts3Cntr : 8|4@1+ (1,0) [0|15] "" Vector__XXX
 SG_ MotorGenerator2MotorAngle : 16|16@1+ (0.0078125,0) [0|359.9921875] "deg" Vector__XXX

BO_ 2364574718 MG3IS3: 8 Vector__XXX
 SG_ MtrGnrtr3InvrtrCntrlStts3Cr : 0|8@1+ (1,0) [0|250] "count" Vector__XXX
 SG_ MtrGnrtr3InvrtrCntrlStts3Cntr : 8|4@1+ (1,0) [0|15] "" Vector__XXX
 SG_ MotorGenerator3MotorAngle : 16|16@1+ (0.0078125,0) [0|359.9921875] "deg" Vector__XXX

BO_ 2364574974 MG4IS3: 8 Vector__XXX
 SG_ MtrGnrtr4InvrtrCntrlStts3Cr : 0|8@1+ (1,0) [0|250] "count" Vector__XXX
 SG_ MtrGnrtr4InvrtrCntrlStts3Cntr : 8|4@1+ (1,0) [0|15] "" Vector__XXX
 SG_ MotorGenerator4MotorAngle : 16|16@1+ (0.0078125,0) [0|359.9921875] "deg" Vector__XXX

BO_ 2364575230 MG5IS3: 8 Vector__XXX
 SG_ MtrGnrtr5InvrtrCntrlStts3Cr : 0|8@1+ (1,0) [0|250] "count" Vector__XXX
 SG_ MtrGnrtr5InvrtrCntrlStts3Cntr : 8|4@1+ (1,0) [0|15] "" Vector__XXX
 SG_ MotorGenerator5MotorAngle : 16|16@1+ (0.0078125,0) [0|359.9921875] "deg" Vector__XXX

BO_ 2364575486 MG6IS3: 8 Vector__XXX
 SG_ MtrGnrtr6InvrtrCntrlStts3Cr : 0|8@1+ (1,0) [0|250] "count" Vector__XXX
 SG_ MtrGnrtr6InvrtrCntrlStts3Cntr : 8|4@1+ (1,0) [0|15] "" Vector__XXX
 SG_ MotorGenerator6MotorAngle : 16|16@1+ (0.0078125,0) [0|359.9921875] "deg" Vector__XXX

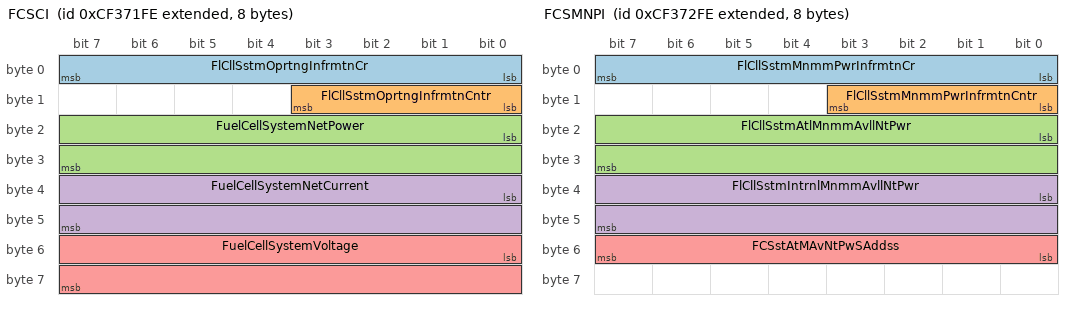
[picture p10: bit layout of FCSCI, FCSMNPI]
BO_ 2364764670 FCSCI: 8 Vector__XXX
 SG_ FlCllSstmOprtngInfrmtnCr : 0|8@1+ (1,0) [0|250] "count" Vector__XXX
 SG_ FlCllSstmOprtngInfrmtnCntr : 8|4@1+ (1,0) [0|15] "" Vector__XXX
 SG_ FuelCellSystemNetPower : 16|16@1+ (0.00390625,-125) [-125|125.99609375] "%" Vector__XXX
 SG_ FuelCellSystemNetCurrent : 32|16@1+ (0.00390625,-125) [-125|125.99609375] "%" Vector__XXX
 SG_ FuelCellSystemVoltage : 48|16@1+ (0.00390625,-125) [-125|125.99609375] "%" Vector__XXX

BO_ 2364764926 FCSMNPI: 8 Vector__XXX
 SG_ FlCllSstmMnmmPwrInfrmtnCr : 0|8@1+ (1,0) [0|250] "count" Vector__XXX
 SG_ FlCllSstmMnmmPwrInfrmtnCntr : 8|4@1+ (1,0) [0|15] "" Vector__XXX
 SG_ FlCllSstmAtlMnmmAvllNtPwr : 16|16@1+ (0.00390625,-125) [-125|125.99609375] "%" Vector__XXX
 SG_ FlCllSstmIntrnlMnmmAvllNtPwr : 32|16@1+ (0.00390625,-125) [-125|125.99609375] "%" Vector__XXX
 SG_ FCSstAtMAvNtPwSAddss : 48|8@1+ (1,0) [0|250] "sourceadr" Vector__XXX

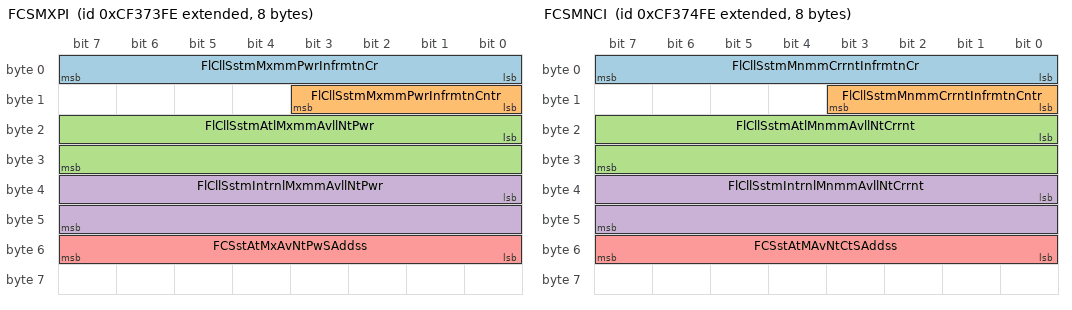
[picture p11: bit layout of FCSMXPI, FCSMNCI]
BO_ 2364765182 FCSMXPI: 8 Vector__XXX
 SG_ FlCllSstmMxmmPwrInfrmtnCr : 0|8@1+ (1,0) [0|250] "count" Vector__XXX
 SG_ FlCllSstmMxmmPwrInfrmtnCntr : 8|4@1+ (1,0) [0|15] "" Vector__XXX
 SG_ FlCllSstmAtlMxmmAvllNtPwr : 16|16@1+ (0.00390625,-125) [-125|125.99609375] "%" Vector__XXX
 SG_ FlCllSstmIntrnlMxmmAvllNtPwr : 32|16@1+ (0.00390625,-125) [-125|125.99609375] "%" Vector__XXX
 SG_ FCSstAtMxAvNtPwSAddss : 48|8@1+ (1,0) [0|250] "sourceadr" Vector__XXX

BO_ 2364765438 FCSMNCI: 8 Vector__XXX
 SG_ FlCllSstmMnmmCrrntInfrmtnCr : 0|8@1+ (1,0) [0|250] "count" Vector__XXX
 SG_ FlCllSstmMnmmCrrntInfrmtnCntr : 8|4@1+ (1,0) [0|15] "" Vector__XXX
 SG_ FlCllSstmAtlMnmmAvllNtCrrnt : 16|16@1+ (0.00390625,-125) [-125|125.99609375] "%" Vector__XXX
 SG_ FlCllSstmIntrnlMnmmAvllNtCrrnt : 32|16@1+ (0.00390625,-125) [-125|125.99609375] "%" Vector__XXX
 SG_ FCSstAtMAvNtCtSAddss : 48|8@1+ (1,0) [0|250] "sourceadr" Vector__XXX

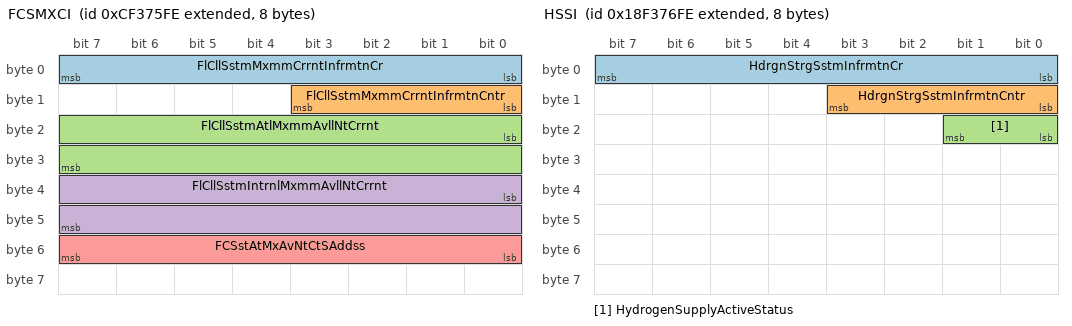
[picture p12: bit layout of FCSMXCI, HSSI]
BO_ 2364765694 FCSMXCI: 8 Vector__XXX
 SG_ FlCllSstmMxmmCrrntInfrmtnCr : 0|8@1+ (1,0) [0|250] "count" Vector__XXX
 SG_ FlCllSstmMxmmCrrntInfrmtnCntr : 8|4@1+ (1,0) [0|15] "" Vector__XXX
 SG_ FlCllSstmAtlMxmmAvllNtCrrnt : 16|16@1+ (0.00390625,-125) [-125|125.99609375] "%" Vector__XXX
 SG_ FlCllSstmIntrnlMxmmAvllNtCrrnt : 32|16@1+ (0.00390625,-125) [-125|125.99609375] "%" Vector__XXX
 SG_ FCSstAtMxAvNtCtSAddss : 48|8@1+ (1,0) [0|250] "sourceadr" Vector__XXX

BO_ 2566092542 HSSI: 8 Vector__XXX
 SG_ HdrgnStrgSstmInfrmtnCr : 0|8@1+ (1,0) [0|250] "count" Vector__XXX
 SG_ HdrgnStrgSstmInfrmtnCntr : 8|4@1+ (1,0) [0|15] "" Vector__XXX
 SG_ HydrogenSupplyActiveStatus : 16|2@1+ (1,0) [0|3] "" Vector__XXX

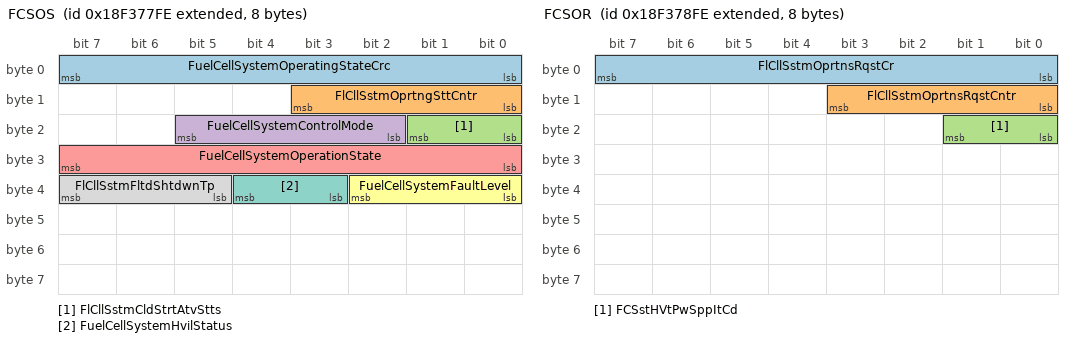
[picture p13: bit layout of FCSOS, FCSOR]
BO_ 2566092798 FCSOS: 8 Vector__XXX
 SG_ FuelCellSystemOperatingStateCrc : 0|8@1+ (1,0) [0|250] "count" Vector__XXX
 SG_ FlCllSstmOprtngSttCntr : 8|4@1+ (1,0) [0|15] "" Vector__XXX
 SG_ FlCllSstmCldStrtAtvStts : 16|2@1+ (1,0) [0|3] "" Vector__XXX
 SG_ FuelCellSystemControlMode : 18|4@1+ (1,0) [0|15] "" Vector__XXX
 SG_ FuelCellSystemOperationState : 24|8@1+ (1,0) [0|250] "" Vector__XXX
 SG_ FuelCellSystemFaultLevel : 32|3@1+ (1,0) [0|7] "" Vector__XXX
 SG_ FuelCellSystemHvilStatus : 35|2@1+ (1,0) [0|3] "" Vector__XXX
 SG_ FlCllSstmFltdShtdwnTp : 37|3@1+ (1,0) [0|7] "" Vector__XXX

BO_ 2566093054 FCSOR: 8 Vector__XXX
 SG_ FlCllSstmOprtnsRqstCr : 0|8@1+ (1,0) [0|250] "count" Vector__XXX
 SG_ FlCllSstmOprtnsRqstCntr : 8|4@1+ (1,0) [0|15] "" Vector__XXX
 SG_ FCSstHVtPwSppItCd : 16|2@1+ (1,0) [0|3] "" Vector__XXX

BO_ 2566093310 FCSI: 8 Vector__XXX
 SG_ FuelCellStackCurrent : 0|8@1+ (0.4,0) [0|100] "%" Vector__XXX
 SG_ FuelCellStackVoltage : 8|8@1+ (0.4,0) [0|100] "%" Vector__XXX

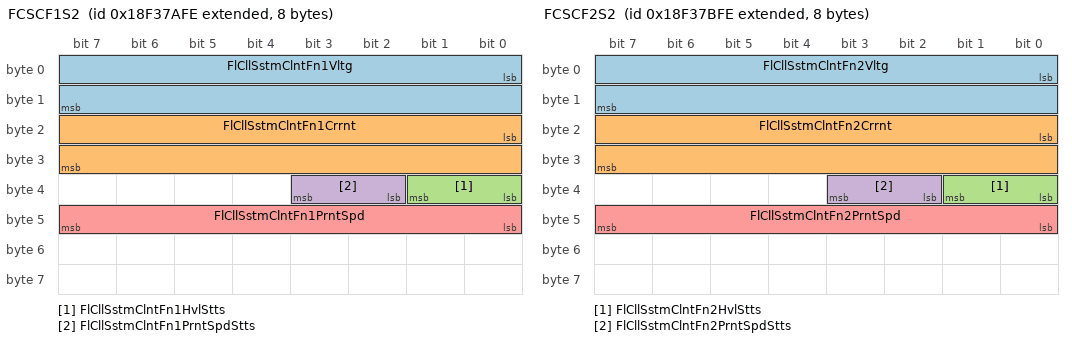
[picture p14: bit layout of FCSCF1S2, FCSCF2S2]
BO_ 2566093566 FCSCF1S2: 8 Vector__XXX
 SG_ FlCllSstmClntFn1Vltg : 0|16@1+ (0.05,0) [0|3212.75] "V" Vector__XXX
 SG_ FlCllSstmClntFn1Crrnt : 16|16@1+ (0.05,-1600) [-1600|1612.75] "A" Vector__XXX
 SG_ FlCllSstmClntFn1HvlStts : 32|2@1+ (1,0) [0|3] "" Vector__XXX
 SG_ FlCllSstmClntFn1PrntSpdStts : 34|2@1+ (1,0) [0|3] "" Vector__XXX
 SG_ FlCllSstmClntFn1PrntSpd : 40|8@1+ (0.5,0) [0|100] "%" Vector__XXX

BO_ 2566093822 FCSCF2S2: 8 Vector__XXX
 SG_ FlCllSstmClntFn2Vltg : 0|16@1+ (0.05,0) [0|3212.75] "V" Vector__XXX
 SG_ FlCllSstmClntFn2Crrnt : 16|16@1+ (0.05,-1600) [-1600|1612.75] "A" Vector__XXX
 SG_ FlCllSstmClntFn2HvlStts : 32|2@1+ (1,0) [0|3] "" Vector__XXX
 SG_ FlCllSstmClntFn2PrntSpdStts : 34|2@1+ (1,0) [0|3] "" Vector__XXX
 SG_ FlCllSstmClntFn2PrntSpd : 40|8@1+ (0.5,0) [0|100] "%" Vector__XXX

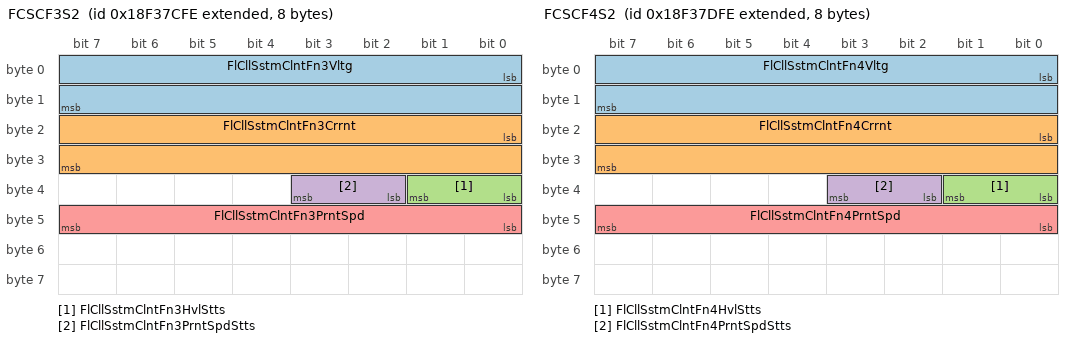
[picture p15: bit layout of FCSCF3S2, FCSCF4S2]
BO_ 2566094078 FCSCF3S2: 8 Vector__XXX
 SG_ FlCllSstmClntFn3Vltg : 0|16@1+ (0.05,0) [0|3212.75] "V" Vector__XXX
 SG_ FlCllSstmClntFn3Crrnt : 16|16@1+ (0.05,-1600) [-1600|1612.75] "A" Vector__XXX
 SG_ FlCllSstmClntFn3HvlStts : 32|2@1+ (1,0) [0|3] "" Vector__XXX
 SG_ FlCllSstmClntFn3PrntSpdStts : 34|2@1+ (1,0) [0|3] "" Vector__XXX
 SG_ FlCllSstmClntFn3PrntSpd : 40|8@1+ (0.5,0) [0|100] "%" Vector__XXX

BO_ 2566094334 FCSCF4S2: 8 Vector__XXX
 SG_ FlCllSstmClntFn4Vltg : 0|16@1+ (0.05,0) [0|3212.75] "V" Vector__XXX
 SG_ FlCllSstmClntFn4Crrnt : 16|16@1+ (0.05,-1600) [-1600|1612.75] "A" Vector__XXX
 SG_ FlCllSstmClntFn4HvlStts : 32|2@1+ (1,0) [0|3] "" Vector__XXX
 SG_ FlCllSstmClntFn4PrntSpdStts : 34|2@1+ (1,0) [0|3] "" Vector__XXX
 SG_ FlCllSstmClntFn4PrntSpd : 40|8@1+ (0.5,0) [0|100] "%" Vector__XXX

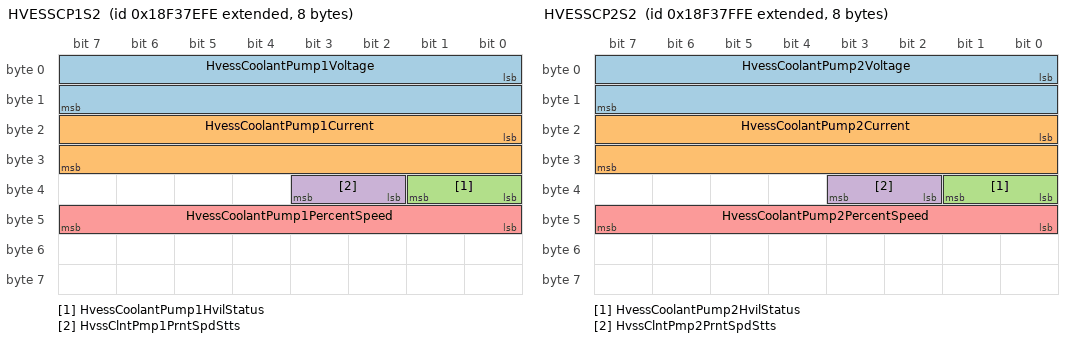
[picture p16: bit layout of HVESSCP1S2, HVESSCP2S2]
BO_ 2566094590 HVESSCP1S2: 8 Vector__XXX
 SG_ HvessCoolantPump1Voltage : 0|16@1+ (0.05,0) [0|3212.75] "V" Vector__XXX
 SG_ HvessCoolantPump1Current : 16|16@1+ (0.05,-1600) [-1600|1612.75] "A" Vector__XXX
 SG_ HvessCoolantPump1HvilStatus : 32|2@1+ (1,0) [0|3] "" Vector__XXX
 SG_ HvssClntPmp1PrntSpdStts : 34|2@1+ (1,0) [0|3] "" Vector__XXX
 SG_ HvessCoolantPump1PercentSpeed : 40|8@1+ (0.5,0) [0|100] "%" Vector__XXX

BO_ 2566094846 HVESSCP2S2: 8 Vector__XXX
 SG_ HvessCoolantPump2Voltage : 0|16@1+ (0.05,0) [0|3212.75] "V" Vector__XXX
 SG_ HvessCoolantPump2Current : 16|16@1+ (0.05,-1600) [-1600|1612.75] "A" Vector__XXX
 SG_ HvessCoolantPump2HvilStatus : 32|2@1+ (1,0) [0|3] "" Vector__XXX
 SG_ HvssClntPmp2PrntSpdStts : 34|2@1+ (1,0) [0|3] "" Vector__XXX
 SG_ HvessCoolantPump2PercentSpeed : 40|8@1+ (0.5,0) [0|100] "%" Vector__XXX

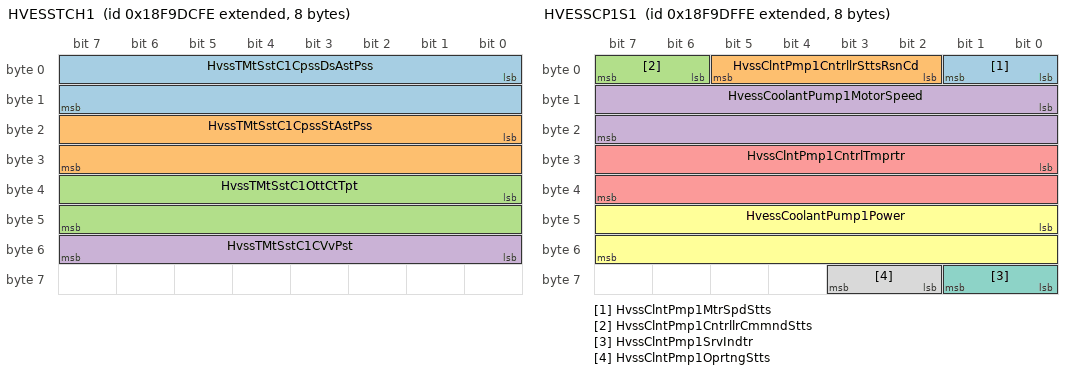
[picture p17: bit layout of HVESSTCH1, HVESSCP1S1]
BO_ 2566511870 HVESSTCH1: 8 Vector__XXX
 SG_ HvssTMtSstC1CpssDsAstPss : 0|16@1+ (1,0) [0|64255] "kPa" Vector__XXX
 SG_ HvssTMtSstC1CpssStAstPss : 16|16@1+ (1,0) [0|64255] "kPa" Vector__XXX
 SG_ HvssTMtSstC1OttCtTpt : 32|16@1+ (0.03125,-273) [-273|1734.96875] "degC" Vector__XXX
 SG_ HvssTMtSstC1CVvPst : 48|8@1+ (0.5,0) [0|125] "%" Vector__XXX

BO_ 2566512126 HVESSTCH2: 8 Vector__XXX
 SG_ HvssTMtSstC2CpssDsAstPss : 0|16@1+ (1,0) [0|64255] "kPa" Vector__XXX
 SG_ HvssTMtSstC2CpssStAstPss : 16|16@1+ (1,0) [0|64255] "kPa" Vector__XXX
 SG_ HvssTMtSstC2OttCtTpt : 32|16@1+ (0.03125,-273) [-273|1734.96875] "degC" Vector__XXX
 SG_ HvssTMtSstC2CVvPst : 48|8@1+ (0.5,0) [0|125] "%" Vector__XXX

BO_ 2566512382 HVESSTCH3: 8 Vector__XXX
 SG_ HvssTMtSstC3CpssDsAstPss : 0|16@1+ (1,0) [0|64255] "kPa" Vector__XXX
 SG_ HvssTMtSstC3CpssStAstPss : 16|16@1+ (1,0) [0|64255] "kPa" Vector__XXX
 SG_ HvssTMtSstC3OttCtTpt : 32|16@1+ (0.03125,-273) [-273|1734.96875] "degC" Vector__XXX
 SG_ HvssTMtSstC3CVvPst : 48|8@1+ (0.5,0) [0|125] "%" Vector__XXX

BO_ 2566512638 HVESSCP1S1: 8 Vector__XXX
 SG_ HvssClntPmp1MtrSpdStts : 0|2@1+ (1,0) [0|3] "" Vector__XXX
 SG_ HvssClntPmp1CntrllrSttsRsnCd : 2|4@1+ (1,0) [0|15] "" Vector__XXX
 SG_ HvssClntPmp1CntrllrCmmndStts : 6|2@1+ (1,0) [0|3] "" Vector__XXX
 SG_ HvessCoolantPump1MotorSpeed : 8|16@1+ (0.5,0) [0|32127.5] "rpm" Vector__XXX
 SG_ HvssClntPmp1CntrlTmprtr : 24|16@1+ (0.03125,-273) [-273|1734.96875] "degC" Vector__XXX
 SG_ HvessCoolantPump1Power : 40|16@1+ (0.5,0) [0|32127.5] "W" Vector__XXX
 SG_ HvssClntPmp1SrvIndtr : 56|2@1+ (1,0) [0|3] "" Vector__XXX
 SG_ HvssClntPmp1OprtngStts : 58|2@1+ (1,0) [0|3] "" Vector__XXX

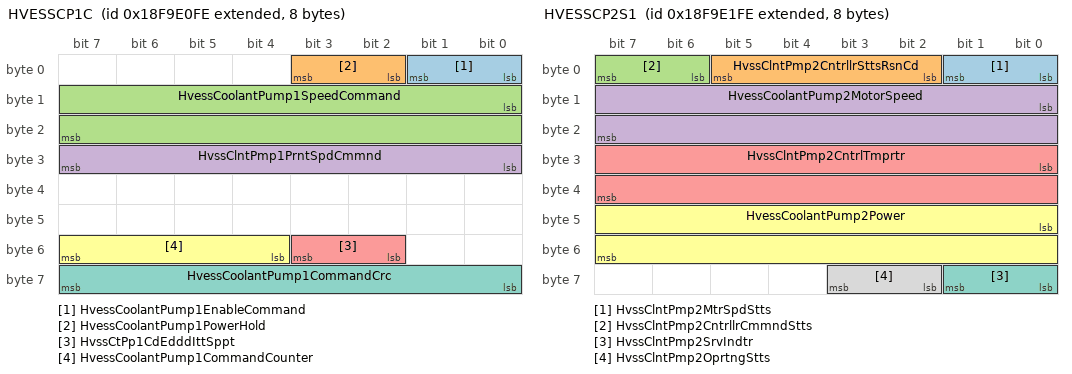
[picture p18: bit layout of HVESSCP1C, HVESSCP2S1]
BO_ 2566512894 HVESSCP1C: 8 Vector__XXX
 SG_ HvessCoolantPump1EnableCommand : 0|2@1+ (1,0) [0|3] "" Vector__XXX
 SG_ HvessCoolantPump1PowerHold : 2|2@1+ (1,0) [0|3] "" Vector__XXX
 SG_ HvessCoolantPump1SpeedCommand : 8|16@1+ (0.5,0) [0|32127.5] "rpm" Vector__XXX
 SG_ HvssClntPmp1PrntSpdCmmnd : 24|8@1+ (0.5,0) [0|100] "%" Vector__XXX
 SG_ HvssCtPp1CdEdddIttSppt : 50|2@1+ (1,0) [0|3] "" Vector__XXX
 SG_ HvessCoolantPump1CommandCounter : 52|4@1+ (1,0) [0|15] "count" Vector__XXX
 SG_ HvessCoolantPump1CommandCrc : 56|8@1+ (1,0) [0|250] "count" Vector__XXX

BO_ 2566513150 HVESSCP2S1: 8 Vector__XXX
 SG_ HvssClntPmp2MtrSpdStts : 0|2@1+ (1,0) [0|3] "" Vector__XXX
 SG_ HvssClntPmp2CntrllrSttsRsnCd : 2|4@1+ (1,0) [0|15] "" Vector__XXX
 SG_ HvssClntPmp2CntrllrCmmndStts : 6|2@1+ (1,0) [0|3] "" Vector__XXX
 SG_ HvessCoolantPump2MotorSpeed : 8|16@1+ (0.5,0) [0|32127.5] "rpm" Vector__XXX
 SG_ HvssClntPmp2CntrlTmprtr : 24|16@1+ (0.03125,-273) [-273|1734.96875] "degC" Vector__XXX
 SG_ HvessCoolantPump2Power : 40|16@1+ (0.5,0) [0|32127.5] "W" Vector__XXX
 SG_ HvssClntPmp2SrvIndtr : 56|2@1+ (1,0) [0|3] "" Vector__XXX
 SG_ HvssClntPmp2OprtngStts : 58|2@1+ (1,0) [0|3] "" Vector__XXX

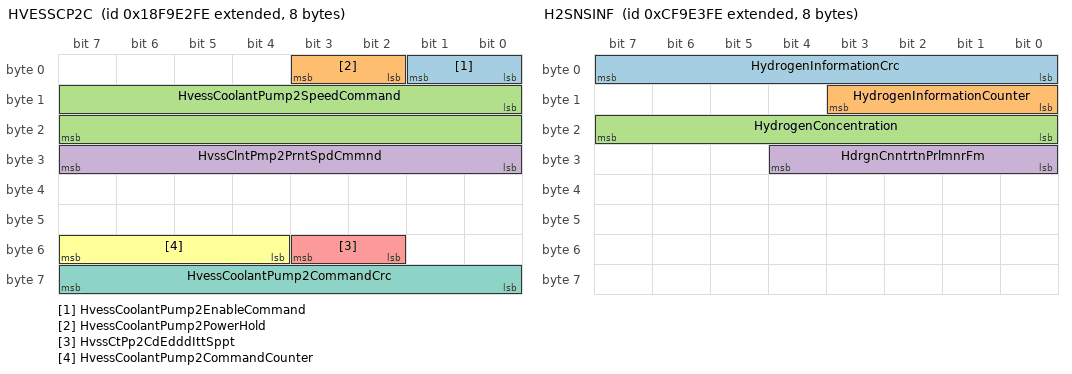
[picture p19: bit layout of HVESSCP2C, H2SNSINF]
BO_ 2566513406 HVESSCP2C: 8 Vector__XXX
 SG_ HvessCoolantPump2EnableCommand : 0|2@1+ (1,0) [0|3] "" Vector__XXX
 SG_ HvessCoolantPump2PowerHold : 2|2@1+ (1,0) [0|3] "" Vector__XXX
 SG_ HvessCoolantPump2SpeedCommand : 8|16@1+ (0.5,0) [0|32127.5] "rpm" Vector__XXX
 SG_ HvssClntPmp2PrntSpdCmmnd : 24|8@1+ (0.5,0) [0|100] "%" Vector__XXX
 SG_ HvssCtPp2CdEdddIttSppt : 50|2@1+ (1,0) [0|3] "" Vector__XXX
 SG_ HvessCoolantPump2CommandCounter : 52|4@1+ (1,0) [0|15] "count" Vector__XXX
 SG_ HvessCoolantPump2CommandCrc : 56|8@1+ (1,0) [0|250] "count" Vector__XXX

BO_ 2365187070 H2SNSINF: 8 Vector__XXX
 SG_ HydrogenInformationCrc : 0|8@1+ (1,0) [0|250] "count" Vector__XXX
 SG_ HydrogenInformationCounter : 8|4@1+ (1,0) [0|15] "" Vector__XXX
 SG_ HydrogenConcentration : 16|8@1+ (500,0) [0|125000] "ppm" Vector__XXX
 SG_ HdrgnCnntrtnPrlmnrFm : 24|5@1+ (1,0) [0|31] "" Vector__XXX

BO_ 2566514174 OIVSI1: 8 Vector__XXX
 SG_ OprtrIndmntVhlSpdDrt : 0|16@1+ (0.00390625,0) [0|250.99609375] "km/h" Vector__XXX
 SG_ OprtrIndmntNxtVhlSpdDrt : 16|16@1+ (0.00390625,0) [0|250.99609375] "km/h" Vector__XXX
 SG_ OprtrIndmntTmTNxtVhlSpdDrt : 32|16@1+ (10,0) [0|642550] "s" Vector__XXX

BO_ 2566514942 EPTDI: 8 Vector__XXX
 SG_ EngineProtectionTorqueReduction : 40|8@1+ (1,-125) [0|100] "%" Vector__XXX

BO_ 2566515198 ASI7: 8 Vector__XXX
 SG_ AttttDsExstFdCtCsptRt : 0|16@1+ (0.05,0) [0|3212.75] "l/h" Vector__XXX
 SG_ AttttDsExstFdPvsCsptRt : 16|16@1+ (0.05,0) [0|3212.75] "l/h" Vector__XXX

BO_ 2633624318 J20123B: 10 Vector__XXX
 SG_ NumberOfJ20123ByteDtcs : 0|8@1+ (1,0) [0|250] "count" Vector__XXX
 SG_ J20123ByteDtcOccurrenceCount : 72|7@1+ (1,0) [0|126] "count" Vector__XXX
 SG_ J20123ByteDtcStatus : 79|1@1+ (1,0) [0|1] "" Vector__XXX
 SG_ J20123ByteDtcBaseCode : 8|40@1+ (1,0) [0|255] "" Vector__XXX
 SG_ J20123ByteDtcDelimiter : 48|8@1+ (1,0) [0|250] "" Vector__XXX
 SG_ J20123ByteDtcFailureType : 56|16@1+ (1,0) [0|255] "" Vector__XXX

CM_ BO_ 2566529790 "Sensor Supply Voltage";
CM_ SG_ 2566529790 EngnCrnksPrssrSnsrMdlSpplVltg "Engine Crankcase Pressure Sensor Module Supply Voltage: Indicates the voltage being supplied to the crankcase pressure sensor module on the engine.";
CM_ SG_ 2566529790 EngnFlDlvrPrssrSnsrMdlSpplVltg "Engine Fuel Delivery Pressure Sensor Module Supply Voltage: Indicates the voltage being supplied to fuel delivery pressure sensor module on the engine";
CM_ SG_ 2566529790 EExstGsRtItPssSsMdSppVt "Engine Exhaust Gas Recirculation Intake Pressure Sensor Module Supply Voltage: Indicates the voltage being supplied to exhaust gas recirculation intake pressure sensor module on the engine.";
CM_ SG_ 2566529790 EngnFltrdFlSnsrMdlSpplVltg "Engine Filtered Fuel Sensor Module Supply Voltage: Indicates the voltage being supplied to fuel sensor module on the engine after the pressure side fuel filter.";
CM_ SG_ 2566529790 EngnOlSnsrMdlSpplVltg "Engine Oil Sensor Module Supply Voltage: Indicates the voltage being supplied to the oil sensor module on the engine.";
CM_ SG_ 2566529790 DsPttFtPssSsMdSppVt "Diesel Particulate Filter Pressure Sensor Module Supply Voltage: Indicates the voltage being supplied to the diesel particulate filter pressure sensor module.";
CM_ SG_ 2566529790 EngnIntkArSnsrMdlSpplVltg "Engine Intake Air Sensor Module Supply Voltage: Indicates the voltage being supplied to the intake air sensor module on the engine.";
CM_ BO_ 2365207550 "Multi-Color Indicator Lamp Command";
CM_ SG_ 2365207550 MltClrIndtrLmpSqnCntr "Multi-Color Indicator Lamp Sequence Counter: A counter value which increments per each transmission of data.Note: The counter for the first message is arbitrary.  In each following message or group of messages (if multiple instances) the value is inc...";
CM_ SG_ 2365207550 MltClrIndtrLmpTmSlt1 "Multi-Color Indicator Lamp Time Slot 1: First time slot for the multi-color indicator lamp.Command to turn selected color on or off in multi-color indicator lamp for (period/frequency) ms.0000b = Off0001b = Color 10010b = Color 20011b = Color 30100b ...";
CM_ SG_ 2365207550 MltClrIndtrLmpTmSlt2 "Multi-Color Indicator Lamp Time Slot 2: Second time slot for the multi-color indicator lamp.Command to turn selected color on or off in multi-color indicator lamp for (period/frequency) ms.0000b = Off0001b = Color 10010b = Color 20011b = Color 30100b...";
CM_ SG_ 2365207550 MltClrIndtrLmpTmSlt3 "Multi-Color Indicator Lamp Time Slot 3: Third time slot for the multi-color indicator lamp.Command to turn selected color on or off in multi-color indicator lamp for (period/frequency) ms.0000b = Off0001b = Color 10010b = Color 20011b = Color 30100b ...";
CM_ SG_ 2365207550 MltClrIndtrLmpTmSlt4 "Multi-Color Indicator Lamp Time Slot 4: Fourth time slot for the multi-color indicator lamp.Command to turn selected color on or off in multi-color indicator lamp for (period/frequency) ms.0000b = Off0001b = Color 10010b = Color 20011b = Color 30100b...";
CM_ SG_ 2365207550 MltClrIndtrLmpTmSlt5 "Multi-Color Indicator Lamp Time Slot 5: Fifth time slot for the multi-color indicator lamp.Command to turn selected color on or off in multi-color indicator lamp for (period/frequency) ms.0000b = Off0001b = Color 10010b = Color 20011b = Color 30100b ...";
CM_ SG_ 2365207550 MltClrIndtrLmpTmSlt6 "Multi-Color Indicator Lamp Time Slot 6: Sixth time slot for the multi-color indicator lamp.Command to turn selected color on or off in multi-color indicator lamp for (period/frequency) ms.0000b = Off0001b = Color 10010b = Color 20011b = Color 30100b ...";
CM_ SG_ 2365207550 MltClrIndtrLmpTmSlt7 "Multi-Color Indicator Lamp Time Slot 7: Seventh time slot for the multi-color indicator lamp.Command to turn selected color on or off in multi-color indicator lamp for (period/frequency) ms.0000b = Off0001b = Color 10010b = Color 20011b = Color 30100...";
CM_ SG_ 2365207550 MltClrIndtrLmpTmSlt8 "Multi-Color Indicator Lamp Time Slot 8: Eighth time slot for the multi-color indicator lamp.Command to turn selected color on or off in multi-color indicator lamp for (period/frequency) ms.0000b = Off0001b = Color 10010b = Color 20011b = Color 30100b...";
CM_ SG_ 2365207550 MltClrIndtrLmpTmSlt9 "Multi-Color Indicator Lamp Time Slot 9: Ninth time slot for the multi-color indicator lamp.Command to turn selected color on or off in multi-color indicator lamp for (period/frequency) ms.0000b = Off0001b = Color 10010b = Color 20011b = Color 30100b ...";
CM_ SG_ 2365207550 MltClrIndtrLmpTmSlt10 "Multi-Color Indicator Lamp Time Slot 10: Tenth time slot for the multi-color indicator lamp.Command to turn selected color on or off in multi-color indicator lamp for (period/frequency) ms.0000b = Off0001b = Color 10010b = Color 20011b = Color 30100b...";
CM_ SG_ 2365207550 MltClrIndtrLmpBrghtnss "Multi-Color Indicator Lamp Brightness: Commanded brightness level for the multi-color indicator lamp.0% means low brightness level and 100% means full brightness level.";
CM_ SG_ 2365207550 MltClrIndtrLmpSnhrnztn "Multi-Color Indicator Lamp Synchronization: Command for an indicator lamp to synchronize with other indicator lamps on the network and flash the same pattern.00b = Not Requested01b = Requested10b = Reserved11b = Not Available";
CM_ SG_ 2365207550 MltClrIndtrLmpFrqn "Multi-Color Indicator Lamp Frequency: Command from the source for the multi-color indicator lamp to target operations for 0.5 Hz, 1 Hz, or 2 Hz.0000b = 0.5 Hz0001b = 1 Hz0010b = 2 Hz0011b = Reserved0100b = Reserved0101b = Reserved0110b = Reserved0111...";
CM_ BO_ 2365207806 "Multi-Color Indicator Lamp Status";
CM_ SG_ 2365207806 MltClrIndtrLmpFdkSqnCntr "Multi-Color Indicator Lamp Feedback Sequence Counter: A feedback counter value which increments per each transmission of data of the multi-color indicator lamp.Note: The counter for the first message is arbitary. In each following message or group of...";
CM_ SG_ 2365207806 MltClrIndtrLmpClr1Stts "Multi-Color Indicator Lamp Color 1 Status: Used to indicate status of Color 1 in the multi-color indicator lamp.0000b = No Fault0001b = Color On Fault (Commanded off)0010b = Color Off fault (Commanded on)0011b = Low Brightness0100b = High Brightness0...";
CM_ SG_ 2365207806 MltClrIndtrLmpClr2Stts "Multi-Color Indicator Lamp Color 2 Status: Used to indicate status of Color 2 in the multi-color indicator lamp.0000b = No Fault0001b = Color On Fault (Commanded off)0010b = Color Off fault (Commanded on)0011b = Low Brightness0100b = High Brightness0...";
CM_ SG_ 2365207806 MltClrIndtrLmpClr3Stts "Multi-Color Indicator Lamp Color 3 Status: Used to indicate status of Color 3 in the multi-color indicator lamp.0000b = No Fault0001b = Color On Fault (Commanded off)0010b = Color Off fault (Commanded on)0011b = Low Brightness0100b = High Brightness0...";
CM_ SG_ 2365207806 MltClrIndtrLmpClr4Stts "Multi-Color Indicator Lamp Color 4 Status: Used to indicate status of Color 4 in the multi-color indicator lamp.0000b = No Fault0001b = Color On Fault (Commanded off)0010b = Color Off fault (Commanded on)0011b = Low Brightness0100b = High Brightness0...";
CM_ SG_ 2365207806 MltClrIndtrLmpClr5Stts "Multi-Color Indicator Lamp Color 5 Status: Used to indicate status of Color 5 in the multi-color indicator lamp.0000b = No Fault0001b = Color On Fault (Commanded off)0010b = Color Off fault (Commanded on)0011b = Low Brightness0100b = High Brightness0...";
CM_ SG_ 2365207806 MltClrIndtrLmpClr6Stts "Multi-Color Indicator Lamp Color 6 Status: Used to indicate status of Color 6 in the multi-color indicator lamp.0000b = No Fault0001b = Color On Fault (Commanded off)0010b = Color Off fault (Commanded on)0011b = Low Brightness0100b = High Brightness0...";
CM_ SG_ 2365207806 MltClrIndtrLmpClr7Stts "Multi-Color Indicator Lamp Color 7 Status: Used to indicate status of Color 7 in the multi-color indicator lamp.0000b = No Fault0001b = Color On Fault (Commanded off)0010b = Color Off fault (Commanded on)0011b = Low Brightness0100b = High Brightness0...";
CM_ SG_ 2365207806 MltClrIndtrLmpClr8Stts "Multi-Color Indicator Lamp Color 8 Status: Used to indicate status of Color 8 in the multi-color indicator lamp.0000b = No Fault0001b = Color On Fault (Commanded off)0010b = Color Off fault (Commanded on)0011b = Low Brightness0100b = High Brightness0...";
CM_ SG_ 2365207806 MltClrIndtrLmpClr9Stts "Multi-Color Indicator Lamp Color 9 Status: Used to indicate status of Color 9 in the multi-color indicator lamp.0000b = No Fault0001b = Color On Fault (Commanded off)0010b = Color Off fault (Commanded on)0011b = Low Brightness0100b = High Brightness0...";
CM_ SG_ 2365207806 MltClrIndtrLmpClr10Stts "Multi-Color Indicator Lamp Color 10 Status: Used to indicate status of Color 10 in the multi-color indicator lamp.0000b = No Fault0001b = Color On Fault (Commanded off)0010b = Color Off fault (Commanded on)0011b = Low Brightness0100b = High Brightnes...";
CM_ SG_ 2365207806 MltClrIndtrLmpClr11Stts "Multi-Color Indicator Lamp Color 11 Status: Used to indicate status of Color 11 in the multi-color indicator lamp.0000b = No Fault0001b = Color On Fault (Commanded off)0010b = Color Off fault (Commanded on)0011b = Low Brightness0100b = High Brightnes...";
CM_ SG_ 2365207806 MltClrIndtrLmpClr12Stts "Multi-Color Indicator Lamp Color 12 Status: Used to indicate status of Color 12 in the multi-color indicator lamp.0000b = No Fault0001b = Color On Fault (Commanded off)0010b = Color Off fault (Commanded on)0011b = Low Brightness0100b = High Brightnes...";
CM_ SG_ 2365207806 MltClrIndtrLmpClr13Stts "Multi-Color Indicator Lamp Color 13 Status: Used to indicate status of Color 13 in the multi-color indicator lamp.0000b = No Fault0001b = Color On Fault (Commanded off)0010b = Color Off fault (Commanded on)0011b = Low Brightness0100b = High Brightnes...";
CM_ SG_ 2365207806 MltClrIndtrLmpClr14Stts "Multi-Color Indicator Lamp Color 14 Status: Used to indicate status of Color 14 in the multi-color indicator lamp.0000b = No Fault0001b = Color On Fault (Commanded off)0010b = Color Off fault (Commanded on)0011b = Low Brightness0100b = High Brightnes...";
CM_ SG_ 2365207806 MltClrIndtrLmpGnrlFlt "Multi-Color Indicator Lamp General Fault: Used to communicate general faults on multi-color indicator lamp.0000b = No Fault0001b = Out of Sync with other lamps0010b = Command message not received0011b = Reserved0100b = Reserved0101b = Reserved0110b =...";
CM_ BO_ 2566648574 "Engine Fuel/Lube Systems 3";
CM_ SG_ 2566648574 EngnFlFltrDffrntlPrssrHghRsltn "Engine Fuel Filter Differential Pressure (High Resolution): Change in fuel delivery pressure, measured across the filter, due to accumulation of solid or semisolid matter on the filter element.See SPN 95 (Engine Fuel Filter Differential Pressure) for...";
CM_ SG_ 2566648574 EFFtStSdDtPssHRst "Engine Fuel Filter (Suction Side) Differential Pressure (High Resolution): Change in fuel delivery pressure, measured across the filter, due to accumulation of solid or semisolid matter on the filter element.See SPN 1382 (Engine Fuel Filter (Suction ...";
CM_ BO_ 2633761022 "Trailer Wheel Brake Wear Life Remaining Information";
CM_ SG_ 2633761022 BrkWrLfRmnngTrlrAxl1LftWhl "Brake Wear Life Remaining, Trailer Axle #1, Left Wheel: The percentage of brake wear life remaining which can still be measured for the left wheel on trailer axle 1.";
CM_ SG_ 2633761022 BrkWrLfRmnngTrlrAxl1RghtWhl "Brake Wear Life Remaining, Trailer Axle #1, Right Wheel: The percentage of brake wear life remaining which can still be measured for the right wheel on trailer axle 1.";
CM_ SG_ 2633761022 BrkWrLfRmnngTrlrAxl2LftWhl "Brake Wear Life Remaining, Trailer Axle #2, Left Wheel: The percentage of brake wear life remaining which can still be measured for the left wheel on trailer axle 2.";
CM_ SG_ 2633761022 BrkWrLfRmnngTrlrAxl2RghtWhl "Brake Wear Life Remaining, Trailer Axle #2, Right Wheel: The percentage of brake wear life remaining which can still be measured for the right wheel on trailer axle 2.";
CM_ SG_ 2633761022 BrkWrLfRmnngTrlrAxl3LftWhl "Brake Wear Life Remaining, Trailer Axle #3, Left Wheel: The percentage of brake wear life remaining which can still be measured for the left wheel on trailer axle 3.";
CM_ SG_ 2633761022 BrkWrLfRmnngTrlrAxl3RghtWhl "Brake Wear Life Remaining, Trailer Axle #3, Right Wheel: The percentage of brake wear life remaining which can still be measured for the right wheel on trailer axle 3.";
CM_ SG_ 2633761022 BrkWrLfRmnngTrlrAxl4LftWhl "Brake Wear Life Remaining, Trailer Axle #4, Left Wheel: The percentage of brake wear life remaining which can still be measured for the left wheel on trailer axle 4.";
CM_ SG_ 2633761022 BrkWrLfRmnngTrlrAxl4RghtWhl "Brake Wear Life Remaining, Trailer Axle #4, Right Wheel: The percentage of brake wear life remaining which can still be measured for the right wheel on trailer axle 4.";
CM_ SG_ 2633761022 BrkWrLfRmnngTrlrAxl5LftWhl "Brake Wear Life Remaining, Trailer Axle #5, Left Wheel: The percentage of brake wear life remaining which can still be measured for the left wheel on trailer axle 5.";
CM_ SG_ 2633761022 BrkWrLfRmnngTrlrAxl5RghtWhl "Brake Wear Life Remaining, Trailer Axle #5, Right Wheel: The percentage of brake wear life remaining which can still be measured for the right wheel on trailer axle 5.";
CM_ SG_ 2633761022 BrkWrLfRmnngTrlrAxl6LftWhl "Brake Wear Life Remaining, Trailer Axle #6, Left Wheel: The percentage of brake wear life remaining which can still be measured for the left wheel on trailer axle 6. ";
CM_ SG_ 2633761022 BrkWrLfRmnngTrlrAxl6RghtWhl "Brake Wear Life Remaining, Trailer Axle #6, Right Wheel: The percentage of brake wear life remaining which can still be measured for the right wheel on trailer axle 6.";
CM_ SG_ 2633761022 BrkWrLfRmnngTrlrAxl7LftWhl "Brake Wear Life Remaining, Trailer Axle #7, Left Wheel: The percentage of brake wear life remaining which can still be measured for the left wheel on trailer axle 7.";
CM_ SG_ 2633761022 BrkWrLfRmnngTrlrAxl7RghtWhl "Brake Wear Life Remaining, Trailer Axle #7, Right Wheel: The percentage of brake wear life remaining which can still be measured for the right wheel on trailer axle 7.";
CM_ SG_ 2633761022 BrkWrLfRmnngTrlrAxl8LftWhl "Brake Wear Life Remaining, Trailer Axle #8, Left Wheel: The percentage of brake wear life remaining which can still be measured for the left wheel on trailer axle 8.";
CM_ SG_ 2633761022 BrkWrLfRmnngTrlrAxl8RghtWhl "Brake Wear Life Remaining, Trailer Axle #8, Right Wheel: The percentage of brake wear life remaining which can still be measured for the right wheel on trailer axle 8.";
CM_ BO_ 2566659838 "Vehicle Electrical Power 16";
CM_ SG_ 2566659838 SlBttrPk1Bttr1ChrgCrrntLmt "SLI Battery Pack 1 Battery 1 charge current limit : The maximum permissible current flow into first battery in the first battery pack used for starting, lighting and ignition (SLI).";
CM_ SG_ 2566659838 SlBttrPk1Bttr2ChrgCrrntLmt "SLI Battery Pack 1 Battery 2 charge current limit : The maximum permissible current flow into second battery in the first battery pack used for starting, lighting and ignition (SLI).";
CM_ SG_ 2566659838 SlBttrPk1Bttr3ChrgCrrntLmt "SLI Battery Pack 1 Battery 3 charge current limit : The maximum permissible current flow into third battery in the first battery pack used for starting, lighting and ignition (SLI).";
CM_ SG_ 2566659838 SlBttrPk1Bttr4ChrgCrrntLmt "SLI Battery Pack 1 Battery 4 charge current limit : The maximum permissible current flow into fourth battery in the first battery pack used for starting, lighting and ignition (SLI).";
CM_ BO_ 2566660094 "Vehicle Electrical Power 17";
CM_ SG_ 2566660094 SlBttrPk1Bttr1DshrgCrrntLmt "SLI Battery Pack 1 Battery 1 discharge current limit : The maximum permissible current flow out of the first battery in the first battery pack used for starting, lighting and ignition (SLI).";
CM_ SG_ 2566660094 SlBttrPk1Bttr2DshrgCrrntLmt "SLI Battery Pack 1 Battery 2 discharge current limit : The maximum permissible current flow out of the second battery in the first battery pack used for starting, lighting and ignition (SLI).";
CM_ SG_ 2566660094 SlBttrPk1Bttr3DshrgCrrntLmt "SLI Battery Pack 1 Battery 3 discharge current limit : The maximum permissible current flow out of the third battery in the first battery pack used for starting, lighting and ignition (SLI).";
CM_ SG_ 2566660094 SlBttrPk1Bttr4DshrgCrrntLmt "SLI Battery Pack 1 Battery 4 discharge current limit : The maximum permissible current flow out of the fourth battery in the first battery pack used for starting, lighting and ignition (SLI).";
CM_ BO_ 2565904382 "Motor/Generator 1 Inverter Thermal Performance Status  ";
CM_ SG_ 2565904382 MtrGnrtr1InvrtrThrmlCpltUsd "Motor/Generator 1 Inverter Thermal Capability Used: Thermal Capability Used of this Motor/Generator Inverter instance. The calculation method must be defined by the manufacturer. Thermal Capability is an indicator of available inverter power capabili...";
CM_ SG_ 2565904382 MtrGnrtr1InvrtrThrmlCpltLmt "Motor/Generator 1 Inverter Thermal Capability Limit: A manufacturer defined thermal threshold beyond which product life may be reduced. According to SPN 22945 (Motor/Generator 1 Inverter Thermal Capability Used).";
CM_ BO_ 2565904638 "Motor/Generator 2 Inverter Thermal Performance Status  ";
CM_ SG_ 2565904638 MtrGnrtr2InvrtrThrmlCpltUsd "Motor/Generator 2 Inverter Thermal Capability Used: Thermal Capability Used of this Motor/Generator Inverter instance. The calculation method must be defined by the manufacturer. Thermal Capability is an indicator of available inverter power capabili...";
CM_ SG_ 2565904638 MtrGnrtr2InvrtrThrmlCpltLmt "Motor/Generator 2 Inverter Thermal Capability Limit: A manufacturer defined thermal threshold beyond which product life may be reduced. According to SPN 22949 (Motor/Generator 2 Inverter Thermal Capability Used).";
CM_ BO_ 2565904894 "Motor/Generator 3 Inverter Thermal Performance Status  ";
CM_ SG_ 2565904894 MtrGnrtr3InvrtrThrmlCpltUsd "Motor/Generator 3 Inverter Thermal Capability Used: Thermal Capability Used of this Motor/Generator Inverter instance. The calculation method must be defined by the manufacturer. Thermal Capability is an indicator of available inverter power capabili...";
CM_ SG_ 2565904894 MtrGnrtr3InvrtrThrmlCpltLmt "Motor/Generator 3 Inverter Thermal Capability Limit: A manufacturer defined thermal threshold beyond which product life may be reduced. According to SPN 22953 (Motor/Generator 3 Inverter Thermal Capability Used).";
CM_ BO_ 2565905150 "Motor/Generator 4 Inverter Thermal Performance Status  ";
CM_ SG_ 2565905150 MtrGnrtr4InvrtrThrmlCpltUsd "Motor/Generator 4 Inverter Thermal Capability Used: Thermal Capability Used of this Motor/Generator Inverter instance. The calculation method must be defined by the manufacturer.  Thermal Capability is an indicator of available inverter power capabil...";
CM_ SG_ 2565905150 MtrGnrtr4InvrtrThrmlCpltLmt "Motor/Generator 4 Inverter Thermal Capability Limit: A manufacturer defined thermal threshold beyond which product life may be reduced. According to SPN 22957 (Motor/Generator 4 Inverter Thermal Capability Used).";
CM_ BO_ 2565905406 "Motor/Generator 5 Inverter Thermal Performance Status  ";
CM_ SG_ 2565905406 MtrGnrtr5InvrtrThrmlCpltUsd "Motor/Generator 5 Inverter Thermal Capability Used: Thermal Capability Used of this Motor/Generator Inverter instance. The calculation method must be defined by the manufacturer.  Thermal Capability is an indicator of available inverter power capabil...";
CM_ SG_ 2565905406 MtrGnrtr5InvrtrThrmlCpltLmt "Motor/Generator 5 Inverter Thermal Capability Limit: A manufacturer defined thermal threshold beyond which product life may be reduced. According to SPN 22961 (Motor/Generator 5 Inverter Thermal Capability Used).";
CM_ BO_ 2565905662 "Motor/Generator 6 Inverter Thermal Performance Status  ";
CM_ SG_ 2565905662 MtrGnrtr6InvrtrThrmlCpltUsd "Motor/Generator 6 Inverter Thermal Capability Used: Thermal Capability Used of this Motor/Generator Inverter instance. The calculation method must be defined by the manufacturer. Thermal Capability is an indicator of available inverter power capabili...";
CM_ SG_ 2565905662 MtrGnrtr6InvrtrThrmlCpltLmt "Motor/Generator 6 Inverter Thermal Capability Limit: A manufacturer defined thermal threshold beyond which product life may be reduced. According to SPN 22965 (Motor/Generator 6 Inverter Thermal Capability Used).";
CM_ BO_ 2565918462 "Engine Turbocharger Control 4";
CM_ SG_ 2565918462 EngnTrhrgrWstgtAttr3Cmmnd "Engine Turbocharger Wastegate Actuator 3 Command: The command to a Turbocharger Wastegate actuator 3, normalized to percent, where 0% nominally represents fully closed (No Flow) and 100% represents fully open (Max Flow).";
CM_ SG_ 2565918462 EngnTrhrgrWstgtAttr4Cmmnd "Engine Turbocharger Wastegate Actuator 4 Command: The command to a Turbocharger Wastegate actuator 4, normalized to percent, where 0% nominally represents fully closed (No Flow) and 100% represents fully open (Max Flow).";
CM_ BO_ 2565918718 "Engine Turbocharger Wastegate Actuator and Exhaust Back Pressure Regulator Information 2";
CM_ SG_ 2565918718 EngnTrhrgrWstgtAttr3OprtnStts "Engine Turbocharger Wastegate Actuator 3 Operation Status: Used to identify the status of Engine Turbocharger Wastegate Actuator 3.0000b = Normal0001b = Alarm (fully operational but needs service)0010b = Alarm High Severity (functional but transient ...";
CM_ SG_ 2565918718 EngnTrhrgrWstgtAttr4OprtnStts "Engine Turbocharger Wastegate Actuator 4 Operation Status: Used to identify the status of Engine Turbocharger Wastegate Actuator 4.0000b = Normal0001b = Alarm (fully operational but needs service)0010b = Alarm High Severity (functional but transient ...";
CM_ BO_ 2566523646 "Motor/Generator 1 Thermal Performance Status  ";
CM_ SG_ 2566523646 MtrGnrtr1ThrmlCpltUsd "Motor/Generator 1 Thermal Capability Used: Thermal Capability Used of this Motor/Generator instance. The calculation method must be defined by the manufacturer. Thermal Capability is an indicator of the available motor power capability in relation to...";
CM_ SG_ 2566523646 MtrGnrtr1ThrmlCpltLmt "Motor/Generator 1 Thermal Capability Limit: A manufacturer defined thermal threshold beyond which product life may be reduced. See also SPN 22943 (Motor/Generator 1 Thermal Capability Used).";
CM_ BO_ 2566523902 "Motor/Generator 2 Thermal Performance Status  ";
CM_ SG_ 2566523902 MtrGnrtr2ThrmlCpltUsd "Motor/Generator 2 Thermal Capability Used: Thermal Capability Used of this Motor/Generator instance. The calculation method must be defined by the manufacturer.  Thermal Capability is an indicator of available motor power capability in relation to th...";
CM_ SG_ 2566523902 MtrGnrtr2ThrmlCpltLmt "Motor/Generator 2 Thermal Capability Limit: A manufacturer defined thermal threshold beyond which product life may be reduced. See also SPN 22947 (Motor/Generator 2 Thermal Capability Used).";
CM_ BO_ 2566524158 "Motor/Generator 3 Thermal Performance Status  ";
CM_ SG_ 2566524158 MtrGnrtr3ThrmlCpltUsd "Motor/Generator 3 Thermal Capability Used: Thermal Capability Used of this Motor/Generator instance. The calculation method must be defined by the manufacturer.  Thermal Capability is an indicator of available motor power capability in relation to th...";
CM_ SG_ 2566524158 MtrGnrtr3ThrmlCpltLmt "Motor/Generator 3 Thermal Capability Limit: A manufacturer defined thermal threshold beyond which product life may be reduced. See also SPN 22951 (Motor/Generator 3 Thermal Capability Used).";
CM_ BO_ 2566524414 "Motor/Generator 4 Thermal Performance Status  ";
CM_ SG_ 2566524414 MtrGnrtr4ThrmlCpltUsd "Motor/Generator 4 Thermal Capability Used: Thermal Capability Used of this Motor/Generator instance. The calculation method must be defined by the manufacturer.  Thermal Capability is an indicator of available motor power capability in relation to th...";
CM_ SG_ 2566524414 MtrGnrtr4ThrmlCpltLmt "Motor/Generator 4 Thermal Capability Limit: A manufacturer defined thermal threshold beyond which product life may be reduced. See also SPN 22955 (Motor/Generator 4 Thermal Capability Used).";
CM_ BO_ 2566524670 "Motor/Generator 5 Thermal Performance Status  ";
CM_ SG_ 2566524670 MtrGnrtr5ThrmlCpltUsd "Motor/Generator 5 Thermal Capability Used: Thermal Capability Used of this Motor/Generator instance. The calculation method must be defined by the manufacturer.Thermal Capability is an indicator of available motor power capability in relation to ther...";
CM_ SG_ 2566524670 MtrGnrtr5ThrmlCpltLmt "Motor/Generator 5 Thermal Capability Limit: A manufacturer defined thermal threshold beyond which product life may be reduced. See also SPN 22959 (Motor/Generator 5 Thermal Capability Used).";
CM_ BO_ 2566524926 "Motor/Generator 6 Thermal Performance Status  ";
CM_ SG_ 2566524926 MtrGnrtr6ThrmlCpltUsd "Motor/Generator 6 Thermal Capability Used: Thermal Capability Used of this Motor/Generator instance. The calculation method must be defined by the manufacturer.Thermal Capability is an indicator of available motor power capability in relation to ther...";
CM_ SG_ 2566524926 MtrGnrtr6ThrmlCpltLmt "Motor/Generator 6 Thermal Capability Limit: A manufacturer defined thermal threshold beyond which product life may be reduced. See also SPN 22963 (Motor/Generator 6 Thermal Capability Used).";
CM_ BO_ 2566525182 "On Board Programming Event Time/Date ";
CM_ SG_ 2566525182 ObpEventSeconds "OBP Event Seconds: The seconds component of the On Board Programming event time. This should be reported as the seconds component of the On Board Programming event time at UTC (Universal Time Coordinate), a.k.a. GMT; however, it may be reported as th...";
CM_ SG_ 2566525182 ObpEventMinutes "OBP Event Minutes: The minutes component of the On Board Programming event time. This should be reported as the minutes component of the On Board Programming event time at UTC (Universal Time Coordinate), a.k.a. GMT; however, it may be reported as th...";
CM_ SG_ 2566525182 ObpEventHours "OBP Event Hours: The hour component of the On Board Programming event time. This should be reported as the hour component of the On Board Programming event time at UTC (Universal Time Coordinate), a.k.a. GMT; however, it may be reported as the hour c...";
CM_ SG_ 2566525182 ObpEventMonth "OBP Event Month: The month component of the On Board Programming event calendar date. This should be reported as the month component of the On Board Programming event date at UTC (Universal Time Coordinate), a.k.a. GMT; however, it may be reported as...";
CM_ SG_ 2566525182 ObpEventDay "OBP Event Day: The day component of the On Board Programming event calendar date.  This should be reported as the day component of the On Board Programming event date at UTC (Universal Time Coordinate), a.k.a. GMT; however, it may be reported as the ...";
CM_ SG_ 2566525182 ObpEventYear "OBP Event Year: The year component of the On Board Programming event date.  This should be reported as the year component of the On Board Programming event date at UTC (Universal Time Coordinate), a.k.a. GMT; however, it may be reported as the year c...";
CM_ SG_ 2566525182 ObpEventLocalMinuteOffset "OBP Event Local minute offset: The minute component of the offset between the UTC time and date and a local time zone time and date.  This is the number of minutes to add to UTC (Universal Time Coordinate) time and date to convert to the time and dat...";
CM_ SG_ 2566525182 ObpEventLocalHourOffset "OBP Event Local hour offset: The hour component of the offset between the UTC (Universal Time Coordinate) time and date and a local time zone time and date.  This is the number of hours to add to UTC, a.k.a. GMT, time and date to convert to the time ...";
CM_ BO_ 2566525438 "Aftertreatment 1 Light Off SCR Service Information 1";
CM_ SG_ 2566525438 Atttt1TtLtOSDsExstFdUsd "Aftertreatment 1 Total Light Off SCR Diesel Exhaust Fluid Used: Total amount of DEF used by the light off SCR device over the lifetime of the device.See SPN 5963 (Aftertreatment 1 Total Diesel Exhaust Fluid Used) for the accumulation of all DEF used....";
CM_ SG_ 2566525438 Atttt1TpLtOSDsExstFd "Aftertreatment 1 Trip Light Off SCR Diesel Exhaust Fluid: DEF consumed by the light-off SCR device during all or part of a journey.See SPN 6563 (Aftertreatment Trip Diesel Exhaust Fluid) for the accumulation of all DEF used.";
CM_ BO_ 2566525950 "Cold Start Emissions Reduction Strategy Current Operating Cycle Data";
CM_ SG_ 2566525950 CtCCtstHtEUtFtpCdSttTT "Current Cycle Catalyst Heat Energy Until FTP Cold Start Tracking Time: Pre-SCR heat energy (in units of kJ) until the FTP catalyst cold start tracking time, as defined in 13 CCR 1971.1 (h)(5.9.1)(B), is achieved for the current operating cycle. See 1...";
CM_ SG_ 2566525950 CtCCtstHtEUtFtpEOtptE "Current Cycle Catalyst Heat Energy Until FTP Engine Output Energy: Pre-SCR heat energy until the specified FTP engine output energy, as defined in 13 CCR 1971.1 (h)(5.9.1)(D), is achieved for the current operating cycle. See 13 CCR 1971.1 (h)(5.9.2)(...";
CM_ SG_ 2566525950 CtCCtstHtEUtCtstCdSttTTptTsd "Current Cycle Catalyst Heat Energy Until Catalyst Cold Start Tracking Temperature Threshold: Pre-SCR heat energy until the catalyst cold start tracking temperature threshold, as defined in 13 CCR 1971.1 (h)(5.9.1)(A), is achieved. See 13 CCR 1971.1 (...";
CM_ SG_ 2566525950 CtCEOtptEUtFtpCdSttTT "Current Cycle Engine Output Energy Until FTP Cold Start Tracking Time: Engine output energy until the FTP catalyst cold start tracking time, as defined in 13 CCR 1971.1 (h)(5.9.1)(B), is achieved for the current operating cycle. See 13 CCR 1971.1 (h)...";
CM_ SG_ 2566525950 CtCEOtptEUtCtstCdSttTTptTsd "Current Cycle Engine Output Energy Until Catalyst Cold Start Tracking Temperature Threshold: Engine output energy until the catalyst cold start tracking light off temperature threshold, as defined in 13 CCR 1971.1 (h)(5.9.1)(A), is achieved for the c...";
CM_ SG_ 2566525950 CtCEMssUtFtpCdSttTT "Current Cycle EGR Mass Until FTP Cold Start Tracking Time: EGR mass until the FTP catalyst cold start tracking time, as defined in 13 CCR 1971.1 (h)(5.9.1)(B), is achieved for the current operating cycle. See 13 CCR 1971.1 (h)(5.9.2)(F) EGR mass flow...";
CM_ SG_ 2566525950 CtCEMssUtFtpEOtptE "Current Cycle EGR Mass Until FTP Engine Output Energy: EGR mass until the specified FTP engine output energy, as defined in 13 CCR 1971.1 (h)(5.9.1)(D), is achieved for the current operating cycle.  See 13 CCR 1971.1 (h)(5.9.2)(G) EGR mass flow track...";
CM_ SG_ 2566525950 CtCEMssUtCdSttTCtstTptTsd "Current Cycle EGR Mass Until Cold Start Tracking Catalyst Temperature Threshold: EGR mass until the catalyst cold start tracking temperature threshold, as defined in 13 CCR 1971.1 (h)(5.9.1)(A), is achieved for the current operating cycle. See 13 CCR...";
CM_ SG_ 2566525950 CrrntClTmUntlFtpEngnOtptEnrg "Current Cycle Time Until FTP Engine Output Energy: Time until the specified FTP engine output energy, as defined in 13 CCR 1971.1 (h)(5.9.1)(D), is achieved for the current operating cycle. See 13 CCR 1971.1 (h)(5.9.2)(I) Timer #1 engine energy outpu...";
CM_ SG_ 2566525950 CtCTUtCtstCdSttTTptTsd "Current Cycle Time Until Catalyst Cold Start Tracking Temperature Threshold: Time until the catalyst cold start tracking temperature threshold, as defined in 13 CCR 1971.1 (h)(5.9.1)(A), is achieved for the current operating cycle. See 13 CCR 1971.1 ...";
CM_ BO_ 2566526206 "Cold Start Emissions Reduction Strategy Average Data";
CM_ SG_ 2566526206 AvCtstHtEUtFtpCdSttTT "Average Catalyst Heat Energy Until FTP Cold Start Tracking Time: Moving weighted average of (SPN 22227) Pre-SCR heat energy (in units of kJ) until the FTP catalyst cold start tracking time, as defined in 13 CCR 1971.1 (h)(5.9.1)(B), is achieved. See ...";
CM_ SG_ 2566526206 AvCtstHtEUtFtpEOtptE "Average Catalyst Heat Energy Until FTP Engine Output Energy: Moving weighted average of (SPN 22228) Pre-SCR heat energy until the specified FTP engine output energy, as defined in 13 CCR 1971.1 (h)(5.9.1)(D) is achieved. See 13 CCR 1971.1 (h)(5.9.3)(...";
CM_ SG_ 2566526206 AvCtstHtEUtCtstCdSttTTptTsd "Average Catalyst Heat Energy Until Catalyst Cold Start Tracking Temperature Threshold: Moving weighted average of (SPN 22229) Pre-SCR heat energy until the catalyst cold start tracking temperature threshold, as defined in 13 CCR 1971.1 (h)(5.9.1)(A),...";
CM_ SG_ 2566526206 AvEOtptEUtFtpCdSttTT "Average Engine Output Energy Until FTP Cold Start Tracking Time: Moving weighted average of (SPN 22230) Engine output energy until the FTP catalyst cold start tracking time, as defined in 13 CCR 1971.1 (h)(5.9.1)(B), is achieved. See 13 CCR 1971.1 (h...";
CM_ SG_ 2566526206 AvEOtptEUtCdSttTCtstTptTsd "Average Engine Output Energy Until Cold Start Tracking Catalyst Temperature Threshold: Moving weighted average of (SPN 22231) Engine output energy until the catalyst cold start tracking temperature threshold, as defined in 13 CCR 1971.1 (h)(5.9.1)(A)...";
CM_ SG_ 2566526206 AvrgEgrMssAtFtpCldStrtTrkngTm "Average EGR Mass at FTP Cold Start Tracking Time: Moving weighted average of (SPN 22232) EGR mass until the FTP catalyst cold start tracking time, as defined in 13 CCR 1971.1 (h)(5.9.1)(B), is achieved. See 13 CCR 1971.1 (h)(5.9.3)(B) and (h)(5.9.2)(...";
CM_ SG_ 2566526206 AvrgEgrMssAtFtpEngnOtptEnrg "Average EGR Mass at FTP Engine Output Energy: Moving weighted average of (SPN 22233) EGR mass until the specified FTP engine output energy, as defined in 13 CCR 1971.1 (h)(5.9.1)(D), is achieved. See 13 CCR 1971.1 (h)(5.9.3)(B) and (h)(5.9.2)(G) EGR ...";
CM_ SG_ 2566526206 AvEMssUtFtpCdSttTCtstTpt "Average EGR Mass until FTP Cold Start Tracking Catalyst Temperature: Moving weighted average of (SPN 22234) EGR mass until the FTP catalyst cold start tracking temperature, as defined in 13 CCR 1971.1 (h)(5.9.1)(A), is achieved. See 13 CCR 1971.1 (h)...";
CM_ SG_ 2566526206 AvrgTmUntlFtpEngnOtptEnrg "Average Time Until FTP Engine Output Energy: Moving weighted average of (SPN 22235) Time until the specified FTP engine output energy, as defined in 13 CCR 1971.1 (h)(5.9.1)(D), is achieved. See 13 CCR 1971.1 (h)(5.9.3)(B) and (h)(5.9.2)(I) Timer #1 ...";
CM_ SG_ 2566526206 AvTUtCtstCdSttTTpt "Average Time Until Catalyst Cold Start Tracking Temperature: Moving weighted average of (SPN 22236) Time until the catalyst cold start tracking temperature threshold, as defined in 13 CCR 1971.1 (h)(5.9.1)(A), is achieved. See 13 CCR 1971.1 (h)(5.9.3...";
CM_ BO_ 2365200126 "High Voltage Energy Storage System Internal Status 1 ";
CM_ SG_ 2365200126 HvssHghVltgIntrnlVltgLvl1 "HVESS High-Voltage Internal Voltage Level 1: The voltage level of the High Voltage Energy Storage System Internal Circuit 1 (or Pack 1 in systems with only one pack). This parameter should be synchronized with SPN 22916 (HVESS High-Voltage Internal C...";
CM_ SG_ 2365200126 HvssHghVltgIntrnlCrrnt1 "HVESS High-Voltage Internal Current 1: The current in or out of the High Voltage Energy Storage System Internal Circuit 1 (or Pack 1 in systems with only one pack). This parameter should be synchronized with SPN 22915 (HVESS High-Voltage Internal Vol...";
CM_ SG_ 2365200126 HvssHghVltgIntrnlVltgLvl2 "HVESS High-Voltage Internal Voltage Level 2: The voltage level of the High Voltage Energy Storage System Internal circuit 2 (or Pack 1 in systems with only one pack). This parameter should be synchronized with SPN 22918 (HVESS High-Voltage Internal C...";
CM_ SG_ 2365200126 HvssHghVltgIntrnlCrrnt2 "HVESS High-Voltage Internal Current 2: The current in or out of the High Voltage Energy Storage System Internal Circuit 2 (or Pack 1 in systems with only one pack). This parameter should be synchronized with SPN 22917 (HVESS High-Voltage Internal Vol...";
CM_ BO_ 2365200382 "High Voltage Energy Storage System Internal Status 2";
CM_ SG_ 2365200382 HvssHghVltgIntrnlVltgLvl3 "HVESS High-Voltage Internal Voltage Level 3: The voltage level of the High Voltage Energy Storage System Internal circuit 3 (or Pack 1 in systems with only one pack). This parameter should be synchronized with SPN 22920 (HVESS High-Voltage Internal C...";
CM_ SG_ 2365200382 HvssHghVltgIntrnlCrrnt3 "HVESS High-Voltage Internal Current 3: The current in or out of the High Voltage Energy Storage System Internal Circuit 3 (or Pack 1 in systems with only one pack). This parameter should be synchronized with SPN 22919 (HVESS High-Voltage Internal Vol...";
CM_ SG_ 2365200382 HvssHghVltgIntrnlVltgLvl4 "HVESS High-Voltage Internal Voltage Level 4: The voltage level of the High Voltage Energy Storage System Internal circuit 4 (or Pack 1 in systems with only one pack). This parameter should be synchronized with SPN 22922 (HVESS High-Voltage Internal C...";
CM_ SG_ 2365200382 HvssHghVltgIntrnlCrrnt4 "HVESS High-Voltage Internal Current 4: The current in or out of the High Voltage Energy Storage System Internal Circuit 4 (or Pack 1 in systems with only one pack). This parameter should be synchronized with SPN 22921 (HVESS High-Voltage Internal Vol...";
CM_ BO_ 2365200638 "High Voltage Energy Storage System Internal Status 3";
CM_ SG_ 2365200638 HvssHghVltgIntrnlVltgLvl5 "HVESS High-Voltage Internal Voltage Level 5: The voltage level of the High Voltage Energy Storage System Internal circuit 5 (or Pack 1 in systems with only one pack). This parameter should be synchronized with SPN 22924 (HVESS High-Voltage Internal C...";
CM_ SG_ 2365200638 HvssHghVltgIntrnlCrrnt5 "HVESS High-Voltage Internal Current 5: The current in or out of the High Voltage Energy Storage System Internal Circuit 5 (or Pack 1 in systems with only one pack). This parameter should be synchronized with SPN 22923 (HVESS High-Voltage Internal Vol...";
CM_ SG_ 2365200638 HvssHghVltgIntrnlVltgLvl6 "HVESS High-Voltage Internal Voltage Level 6: The voltage level of the High Voltage Energy Storage System Internal circuit 6 (or Pack 1 in systems with only one pack). This parameter should be synchronized with SPN 22926 (HVESS High-Voltage Internal C...";
CM_ SG_ 2365200638 HvssHghVltgIntrnlCrrnt6 "HVESS High-Voltage Internal Current 6: The current in or out of the High Voltage Energy Storage System Internal Circuit 6 (or Pack 1 in systems with only one pack). This parameter should be synchronized with SPN 22925 (HVESS High-Voltage Internal Vol...";
CM_ BO_ 2365200894 "High Voltage Energy Storage System Internal Status 4";
CM_ SG_ 2365200894 HvssHghVltgIntrnlVltgLvl7 "HVESS High-Voltage Internal Voltage Level 7: The voltage level of the High Voltage Energy Storage System Internal circuit 7 (or Pack 1 in systems with only one pack). This parameter should be synchronized with SPN 22928 (HVESS High-Voltage Internal C...";
CM_ SG_ 2365200894 HvssHghVltgIntrnlCrrnt7 "HVESS High-Voltage Internal Current 7: The current in or out of the High Voltage Energy Storage System Internal Circuit 7 (or Pack 1 in systems with only one pack). This parameter should be synchronized with SPN 22927 (HVESS High-Voltage Internal Vol...";
CM_ SG_ 2365200894 HvssHghVltgIntrnlVltgLvl8 "HVESS High-Voltage Internal Voltage Level 8: The voltage level of the High Voltage Energy Storage System Internal circuit 8 (or Pack 1 in systems with only one pack). This parameter should be synchronized with SPN 22930 (HVESS High-Voltage Internal C...";
CM_ SG_ 2365200894 HvssHghVltgIntrnlCrrnt8 "HVESS High-Voltage Internal Current 8: The current in or out of the High Voltage Energy Storage System Internal Circuit 8 (or Pack 1 in systems with only one pack). This parameter should be synchronized with SPN 22929 (HVESS High-Voltage Internal Vol...";
CM_ BO_ 2432310014 "Electronic Engine Controller 23";
CM_ SG_ 2432310014 EngnCrnksPrssrCntrlAttr1Cmmnd "Engine Crankcase Pressure Control Actuator 1 Command: The command to a crankcase pressure control actuator 1 on an engine, normalized to percent, where 0% nominally represents fully closed and 100% represents fully open.";
CM_ SG_ 2432310014 EngnCrnksPrssrCntrlAttr2Cmmnd "Engine Crankcase Pressure Control Actuator 2 Command: The command to a crankcase pressure control actuator 2 on an engine, normalized to percent, where 0% nominally represents fully closed and 100% represents fully open.";
CM_ BO_ 2432310270 "Electronic Engine Controller 24";
CM_ SG_ 2432310270 EngnCrnksPrssrCntrlAttr1Tmprtr "Engine Crankcase Pressure Control Actuator 1 Temperature: Temperature of the engine crankcase pressure control actuator 1 drive circuitry.";
CM_ SG_ 2432310270 EngnCrnksPrssrCntrlAttr1Pstn "Engine Crankcase Pressure Control Actuator 1 Position: Measures the position of the engine crankcase pressure control actuator 1, where 0% represents actuator is fully closed and 100% represents actuator is fully open.";
CM_ SG_ 2432310270 ECsPssCtAtt1DsdPst "Engine Crankcase Pressure Control Actuator 1 Desired Position: The requested position of the Engine Crankcase Pressure Control Actuator 1 by the engine ECU, where 0% represents bypass fully closed and 100% represents bypass fully open. This is the po...";
CM_ SG_ 2432310270 ECsPssCtAtt1PF "Engine Crankcase Pressure Control Actuator 1 Preliminary FMI: Used to identify the applicable J1939-73 FMI detected in the crankcase pressure control actuator 1 by the manufacturers software. When there is multiple failures, the most severe is transm...";
CM_ SG_ 2432310270 ECsPssCtAtt1TptStts "Engine Crankcase Pressure Control Actuator 1 Temperature Status: Used to identify the status of the crankcase pressure control actuator 1 drive circuitry temperature.  Temperature excursions may affect the torque output.000b = High Most severe001b = ...";
CM_ SG_ 2432310270 ECsPssCtAtt1OptStts "Engine Crankcase Pressure Control Actuator 1 Operation Status: Used to identify the status of engine crankcase pressure control Actuator 1.0000b = Normal0001b = Alarm (fully operational but needs service)0010b = Alarm High Severity (functional but tr...";
CM_ BO_ 2432310526 "Electronic Engine Controller 25";
CM_ SG_ 2432310526 EngnCrnksPrssrCntrlAttr2Tmprtr "Engine Crankcase Pressure Control Actuator 2 Temperature: Temperature of the engine crankcase pressure control actuator 2 drive circuitry.";
CM_ SG_ 2432310526 EngnCrnksPrssrCntrlAttr2Pstn "Engine Crankcase Pressure Control Actuator 2 Position: Measures the position of the engine crankcase pressure control actuator 2, where 0% represents actuator is fully closed and 100% represents actuator is fully open.";
CM_ SG_ 2432310526 ECsPssCtAtt2DsdPst "Engine Crankcase Pressure Control Actuator 2 Desired Position: The requested position of the Engine Crankcase Pressure Control Actuator 2 by the engine ECU, where 0% represents bypass fully closed and 100% represents bypass fully open. This is the po...";
CM_ SG_ 2432310526 ECsPssCtAtt2PF "Engine Crankcase Pressure Control Actuator 2 Preliminary FMI: Used to identify the applicable J1939-73 FMI detected in the crankcase pressure control actuator 2 by the manufacturers software. When there is multiple failures, the most severe is transm...";
CM_ SG_ 2432310526 ECsPssCtAtt2TptStts "Engine Crankcase Pressure Control Actuator 2 Temperature Status: Used to identify the status of the crankcase pressure control actuator 2 drive circuitry temperature.  Temperature excursions may affect the torque output.000b = High Most severe001b = ...";
CM_ SG_ 2432310526 ECsPssCtAtt2OptStts "Engine Crankcase Pressure Control Actuator 2 Operation Status: Used to identify the status of engine crankcase pressure control Actuator 2.0000b = Normal0001b = Alarm (fully operational but needs service)0010b = Alarm High Severity (functional but tr...";
CM_ BO_ 2365201918 "High Voltage Bus Connection Command 1";
CM_ SG_ 2365201918 HghVltgBsIntrf1CnntCmmnd "High-Voltage Bus Interface 1 Connect Command: Command to connect the main high-voltage bus to this high-voltage bus interface instance.  00b = Open Contactor; Disconnect from high-voltage bus01b = Close Contactor; Connect to high-voltage bus10b = Res...";
CM_ SG_ 2365201918 HghVltgBsIntrf2CnntCmmnd "High-Voltage Bus Interface 2 Connect Command: Command to connect the main high-voltage bus to this high-voltage bus interface instance.  00b = Open Contactor; Disconnect from high-voltage bus01b = Close Contactor; Connect to high-voltage bus10b = Res...";
CM_ SG_ 2365201918 HghVltgBsIntrf3CnntCmmnd "High-Voltage Bus Interface 3 Connect Command: Command to connect the main high-voltage bus to this high-voltage bus interface instance.  00b = Open Contactor; Disconnect from high-voltage bus01b = Close Contactor; Connect to high-voltage bus10b = Res...";
CM_ SG_ 2365201918 HghVltgBsIntrf4CnntCmmnd "High-Voltage Bus Interface 4 Connect Command: Command to connect the main high-voltage bus to this high-voltage bus interface instance.  00b = Open Contactor; Disconnect from high-voltage bus01b = Close Contactor; Connect to high-voltage bus10b = Res...";
CM_ SG_ 2365201918 HghVltgBsIntrf5CnntCmmnd "High-Voltage Bus Interface 5 Connect Command: Command to connect the main high-voltage bus to this high-voltage bus interface instance.  00b = Open Contactor; Disconnect from high-voltage bus01b = Close Contactor; Connect to high-voltage bus10b = Res...";
CM_ SG_ 2365201918 HghVltgBsIntrf6CnntCmmnd "High-Voltage Bus Interface 6 Connect Command: Command to connect the main high-voltage bus to this high-voltage bus interface instance.  00b = Open Contactor; Disconnect from high-voltage bus01b = Close Contactor; Connect to high-voltage bus10b = Res...";
CM_ SG_ 2365201918 HghVltgBsIntrf7CnntCmmnd "High-Voltage Bus Interface 7 Connect Command: Command to connect the main high-voltage bus to this high-voltage bus interface instance.  00b = Open Contactor; Disconnect from high-voltage bus01b = Close Contactor; Connect to high-voltage bus10b = Res...";
CM_ SG_ 2365201918 HghVltgBsIntrf8CnntCmmnd "High-Voltage Bus Interface 8 Connect Command: Command to connect the main high-voltage bus to this high-voltage bus interface instance.  00b = Open Contactor; Disconnect from high-voltage bus01b = Close Contactor; Connect to high-voltage bus10b = Res...";
CM_ SG_ 2365201918 HghVltgBsIntrf9CnntCmmnd "High-Voltage Bus Interface 9 Connect Command: Command to connect the main high-voltage bus to this high-voltage bus interface instance.  00b = Open Contactor; Disconnect from high-voltage bus01b = Close Contactor; Connect to high-voltage bus10b = Res...";
CM_ SG_ 2365201918 HghVltgBsIntrf10CnntCmmnd "High-Voltage Bus Interface 10 Connect Command: Command to connect the main high-voltage bus to this high-voltage bus interface instance.  00b = Open Contactor; Disconnect from high-voltage bus01b = Close Contactor; Connect to high-voltage bus10b = Re...";
CM_ SG_ 2365201918 HghVltgBsIntrf11CnntCmmnd "High-Voltage Bus Interface 11 Connect Command: Command to connect the main high-voltage bus to this high-voltage bus interface instance.  00b = Open Contactor; Disconnect from high-voltage bus01b = Close Contactor; Connect to high-voltage bus10b = Re...";
CM_ SG_ 2365201918 HghVltgBsIntrf12CnntCmmnd "High-Voltage Bus Interface 12 Connect Command: Command to connect the main high-voltage bus to this high-voltage bus interface instance.  00b = Open Contactor; Disconnect from high-voltage bus01b = Close Contactor; Connect to high-voltage bus10b = Re...";
CM_ SG_ 2365201918 HghVltgBsIntrf13CnntCmmnd "High-Voltage Bus Interface 13 Connect Command: Command to connect the main high-voltage bus to this high-voltage bus interface instance.  00b = Open Contactor; Disconnect from high-voltage bus01b = Close Contactor; Connect to high-voltage bus10b = Re...";
CM_ SG_ 2365201918 HghVltgBsIntrf14CnntCmmnd "High-Voltage Bus Interface 14 Connect Command: Command to connect the main high-voltage bus to this high-voltage bus interface instance.  00b = Open Contactor; Disconnect from high-voltage bus01b = Close Contactor; Connect to high-voltage bus10b = Re...";
CM_ SG_ 2365201918 HghVltgBsIntrf15CnntCmmnd "High-Voltage Bus Interface 15 Connect Command: Command to connect the main high-voltage bus to this high-voltage bus interface instance.  00b = Open Contactor; Disconnect from high-voltage bus01b = Close Contactor; Connect to high-voltage bus10b = Re...";
CM_ SG_ 2365201918 HghVltgBsIntrf16CnntCmmnd "High-Voltage Bus Interface 16 Connect Command: Command to connect the main high-voltage bus to this high-voltage bus interface instance.  00b = Open Contactor; Disconnect from high-voltage bus01b = Close Contactor; Connect to high-voltage bus10b = Re...";
CM_ SG_ 2365201918 HghVltgBsIntrf17CnntCmmnd "High-Voltage Bus Interface 17 Connect Command: Command to connect the main high-voltage bus to this high-voltage bus interface instance.  00b = Open Contactor; Disconnect from high-voltage bus01b = Close Contactor; Connect to high-voltage bus10b = Re...";
CM_ SG_ 2365201918 HghVltgBsIntrf18CnntCmmnd "High-Voltage Bus Interface 18 Connect Command: Command to connect the main high-voltage bus to this high-voltage bus interface instance.  00b = Open Contactor; Disconnect from high-voltage bus01b = Close Contactor; Connect to high-voltage bus10b = Re...";
CM_ SG_ 2365201918 HghVltgBsIntrf19CnntCmmnd "High-Voltage Bus Interface 19 Connect Command: Command to connect the main high-voltage bus to this high-voltage bus interface instance.  00b = Open Contactor; Disconnect from high-voltage bus01b = Close Contactor; Connect to high-voltage bus10b = Re...";
CM_ SG_ 2365201918 HghVltgBsIntrf20CnntCmmnd "High-Voltage Bus Interface 20 Connect Command: Command to connect the main high-voltage bus to this high-voltage bus interface instance.  00b = Open Contactor; Disconnect from high-voltage bus01b = Close Contactor; Connect to high-voltage bus10b = Re...";
CM_ SG_ 2365201918 HghVltgBsIntrf21CnntCmmnd "High-Voltage Bus Interface 21 Connect Command: Command to connect the main high-voltage bus to this high-voltage bus interface instance.  00b = Open Contactor; Disconnect from high-voltage bus01b = Close Contactor; Connect to high-voltage bus10b = Re...";
CM_ SG_ 2365201918 HghVltgBsIntrf22CnntCmmnd "High-Voltage Bus Interface 22 Connect Command: Command to connect the main high-voltage bus to this high-voltage bus interface instance.  00b = Open Contactor; Disconnect from high-voltage bus01b = Close Contactor; Connect to high-voltage bus10b = Re...";
CM_ SG_ 2365201918 HghVltgBsIntrf23CnntCmmnd "High-Voltage Bus Interface 23 Connect Command: Command to connect the main high-voltage bus to this high-voltage bus interface instance.  00b = Open Contactor; Disconnect from high-voltage bus01b = Close Contactor; Connect to high-voltage bus10b = Re...";
CM_ SG_ 2365201918 HghVltgBsIntrf24CnntCmmnd "High-Voltage Bus Interface 24 Connect Command: Command to connect the main high-voltage bus to this high-voltage bus interface instance.  00b = Open Contactor; Disconnect from high-voltage bus01b = Close Contactor; Connect to high-voltage bus10b = Re...";
CM_ SG_ 2365201918 Hvbcc1EmbeddedIntegritySupport "HVBCC1 Embedded Integrity Support: Indicates SPN 22785 (HVBCC1 CRC) and SPN 22784 (HVBCC1 Counter) are supported by the sender.00b = HVBCC1 embedded CRC and Counter are supported by the sender01b = HVBCC1 protection is provided using an external (not...";
CM_ SG_ 2365201918 Hvbcc1Counter "HVBCC1 Counter: The message counter is used to detect situations where the transmitting ECU malfunction repeats the same frame all the time. The receiver of the information may use the counter parameter to detect this situation. The transmitting devi...";
CM_ SG_ 2365201918 Hvbcc1Crc "HVBCC1 CRC: The CRC is defined as follows:- Length: 8 bits- Polynomial: x^8+x^5+x^3+x^2+x+1- Initial Value: FFh- Input Data Reflection: Not reflected- Result Data Reflection: Not reflected- XOR value: FFhSAE makes no claim of the functional safety le...";
CM_ BO_ 2365202174 "High Voltage Bus Contactor Status 1";
CM_ SG_ 2365202174 HghVltgBsIntrf1PstvCnttrStt "High-Voltage Bus Interface 1 Positive Contactor State: Positive contactor state for this High Voltage Bus (HV Bus) Interface instance.00b = Contactor Open01b = Contactor Closed10b = Error11b = Not Available";
CM_ SG_ 2365202174 HghVltgBsIntrf1NgtvCnttrStt "High-Voltage Bus Interface 1 Negative Contactor State: Negative contactor state for this High Voltage Bus (HV Bus) Interface instance.00b = Contactor Open01b = Contactor Closed10b = Error11b = Not Available";
CM_ SG_ 2365202174 HghVltgBsIntrf2PstvCnttrStt "High-Voltage Bus Interface 2 Positive Contactor State: Positive contactor state for this High Voltage Bus (HV Bus) Interface instance.00b = Contactor Open01b = Contactor Closed10b = Error11b = Not Available";
CM_ SG_ 2365202174 HghVltgBsIntrf2NgtvCnttrStt "High-Voltage Bus Interface 2 Negative Contactor State: Negative contactor state for this High Voltage Bus (HV Bus) Interface instance.00b = Contactor Open01b = Contactor Closed10b = Error11b = Not Available";
CM_ SG_ 2365202174 HghVltgBsIntrf3PstvCnttrStt "High-Voltage Bus Interface 3 Positive Contactor State: Positive contactor state for this High Voltage Bus (HV Bus) Interface instance.00b = Contactor Open01b = Contactor Closed10b = Error11b = Not Available";
CM_ SG_ 2365202174 HghVltgBsIntrf3NgtvCnttrStt "High-Voltage Bus Interface 3 Negative Contactor State: Negative contactor state for this High Voltage Bus (HV Bus) Interface instance.00b = Contactor Open01b = Contactor Closed10b = Error11b = Not Available";
CM_ SG_ 2365202174 HghVltgBsIntrf4PstvCnttrStt "High-Voltage Bus Interface 4 Positive Contactor State: Positive contactor state for this High Voltage Bus (HV Bus) Interface instance.00b = Contactor Open01b = Contactor Closed10b = Error11b = Not Available";
CM_ SG_ 2365202174 HghVltgBsIntrf4NgtvCnttrStt "High-Voltage Bus Interface 4 Negative Contactor State: Negative contactor state for this High Voltage Bus (HV Bus) Interface instance.00b = Contactor Open01b = Contactor Closed10b = Error11b = Not Available";
CM_ SG_ 2365202174 HghVltgBsIntrf5PstvCnttrStt "High-Voltage Bus Interface 5 Positive Contactor State: Positive contactor state for this High Voltage Bus (HV Bus) Interface instance.00b = Contactor Open01b = Contactor Closed10b = Error11b = Not Available";
CM_ SG_ 2365202174 HghVltgBsIntrf5NgtvCnttrStt "High-Voltage Bus Interface 5 Negative Contactor State: Negative contactor state for this High Voltage Bus (HV Bus) Interface instance.00b = Contactor Open01b = Contactor Closed10b = Error11b = Not Available";
CM_ SG_ 2365202174 HghVltgBsIntrf6PstvCnttrStt "High-Voltage Bus Interface 6 Positive Contactor State: Positive contactor state for this High Voltage Bus (HV Bus) Interface instance.00b = Contactor Open01b = Contactor Closed10b = Error11b = Not Available";
CM_ SG_ 2365202174 HghVltgBsIntrf6NgtvCnttrStt "High-Voltage Bus Interface 6 Negative Contactor State: Negative contactor state for this High Voltage Bus (HV Bus) Interface instance.00b = Contactor Open01b = Contactor Closed10b = Error11b = Not Available";
CM_ SG_ 2365202174 HghVltgBsIntrf7PstvCnttrStt "High-Voltage Bus Interface 7 Positive Contactor State: Positive contactor state for this High Voltage Bus (HV Bus) Interface instance.00b = Contactor Open01b = Contactor Closed10b = Error11b = Not Available";
CM_ SG_ 2365202174 HghVltgBsIntrf7NgtvCnttrStt "High-Voltage Bus Interface 7 Negative Contactor State: Negative contactor state for this High Voltage Bus (HV Bus) Interface instance.00b = Contactor Open01b = Contactor Closed10b = Error11b = Not Available";
CM_ SG_ 2365202174 HghVltgBsIntrf8PstvCnttrStt "High-Voltage Bus Interface 8 Positive Contactor State: Positive contactor state for this High Voltage Bus (HV Bus) Interface instance.00b = Contactor Open01b = Contactor Closed10b = Error11b = Not Available";
CM_ SG_ 2365202174 HghVltgBsIntrf8NgtvCnttrStt "High-Voltage Bus Interface 8 Negative Contactor State: Negative contactor state for this High Voltage Bus (HV Bus) Interface instance.00b = Contactor Open01b = Contactor Closed10b = Error11b = Not Available";
CM_ SG_ 2365202174 Hvbcs1EmbeddedIntegritySupport "HVBCS1 Embedded Integrity Support: Indicates SPN 22788 (HVBCS1 CRC) and SPN 22787 (HVBCS1 Counter) are supported by the sender.00b = HVBCS1 embedded CRC and Counter are supported by the sender01b = HVBCS1 protection is provided using an external (not...";
CM_ SG_ 2365202174 Hvbcs1Counter "HVBCS1 Counter: The message counter is used to detect situations where the transmitting ECU malfunction repeats the same frame all the time. The receiver of the information may use the counter parameter to detect this situation. The transmitting devi...";
CM_ SG_ 2365202174 Hvbcs1Crc "HVBCS1 CRC: The CRC is defined as follows:- Length: 8 bits- Polynomial: x^8+x^5+x^3+x^2+x+1- Initial Value: FFh- Input Data Reflection: Not reflected- Result Data Reflection: Not reflected- XOR value: FFhSAE makes no claim of the functional safety le...";
CM_ BO_ 2365333758 "High Voltage Energy Storage System Module Status 2";
CM_ SG_ 2365333758 HvessModule33OperationalStatus "HVESS Module 33 Operational Status : Operational Status of Module 33 in the High Voltage Energy Storage System (or Pack 1 in systems with only one pack). Not Operational is used when the module is initializing or not able to function (e.g. internal m...";
CM_ SG_ 2365333758 HvessModule34OperationalStatus "HVESS Module 34 Operational Status : Operational Status of Module 34 in the High Voltage Energy Storage System (or Pack 1 in systems with only one pack). Not Operational is used when the module is initializing or not able to function (e.g. internal m...";
CM_ SG_ 2365333758 HvessModule35OperationalStatus "HVESS Module 35 Operational Status : Operational Status of Module 35 in the High Voltage Energy Storage System (or Pack 1 in systems with only one pack). Not Operational is used when the module is initializing or not able to function (e.g. internal m...";
CM_ SG_ 2365333758 HvessModule36OperationalStatus "HVESS Module 36 Operational Status : Operational Status of Module 36 in the High Voltage Energy Storage System (or Pack 1 in systems with only one pack). Not Operational is used when the module is initializing or not able to function (e.g. internal m...";
CM_ SG_ 2365333758 HvessModule37OperationalStatus "HVESS Module 37 Operational Status : Operational Status of Module 37 in the High Voltage Energy Storage System (or Pack 1 in systems with only one pack). Not Operational is used when the module is initializing or not able to function (e.g. internal m...";
CM_ SG_ 2365333758 HvessModule38OperationalStatus "HVESS Module 38 Operational Status : Operational Status of Module 38 in the High Voltage Energy Storage System (or Pack 1 in systems with only one pack). Not Operational is used when the module is initializing or not able to function (e.g. internal m...";
CM_ SG_ 2365333758 HvessModule39OperationalStatus "HVESS Module 39 Operational Status : Operational Status of Module 39 in the High Voltage Energy Storage System (or Pack 1 in systems with only one pack). Not Operational is used when the module is initializing or not able to function (e.g. internal m...";
CM_ SG_ 2365333758 HvessModule40OperationalStatus "HVESS Module 40 Operational Status : Operational Status of Module 40 in the High Voltage Energy Storage System (or Pack 1 in systems with only one pack). Not Operational is used when the module is initializing or not able to function (e.g. internal m...";
CM_ SG_ 2365333758 HvessModule41OperationalStatus "HVESS Module 41 Operational Status : Operational Status of Module 41 in the High Voltage Energy Storage System (or Pack 1 in systems with only one pack). Not Operational is used when the module is initializing or not able to function (e.g. internal m...";
CM_ SG_ 2365333758 HvessModule42OperationalStatus "HVESS Module 42 Operational Status : Operational Status of Module 42 in the High Voltage Energy Storage System (or Pack 1 in systems with only one pack). Not Operational is used when the module is initializing or not able to function (e.g. internal m...";
CM_ SG_ 2365333758 HvessModule43OperationalStatus "HVESS Module 43 Operational Status : Operational Status of Module 43 in the High Voltage Energy Storage System (or Pack 1 in systems with only one pack). Not Operational is used when the module is initializing or not able to function (e.g. internal m...";
CM_ SG_ 2365333758 HvessModule44OperationalStatus "HVESS Module 44 Operational Status : Operational Status of Module 44 in the High Voltage Energy Storage System (or Pack 1 in systems with only one pack). Not Operational is used when the module is initializing or not able to function (e.g. internal m...";
CM_ SG_ 2365333758 HvessModule45OperationalStatus "HVESS Module 45 Operational Status : Operational Status of Module 45 in the High Voltage Energy Storage System (or Pack 1 in systems with only one pack). Not Operational is used when the module is initializing or not able to function (e.g. internal m...";
CM_ SG_ 2365333758 HvessModule46OperationalStatus "HVESS Module 46 Operational Status : Operational Status of Module 46 in the High Voltage Energy Storage System (or Pack 1 in systems with only one pack). Not Operational is used when the module is initializing or not able to function (e.g. internal m...";
CM_ SG_ 2365333758 HvessModule47OperationalStatus "HVESS Module 47 Operational Status : Operational Status of Module 47 in the High Voltage Energy Storage System (or Pack 1 in systems with only one pack). Not Operational is used when the module is initializing or not able to function (e.g. internal m...";
CM_ SG_ 2365333758 HvessModule48OperationalStatus "HVESS Module 48 Operational Status : Operational Status of Module 48 in the High Voltage Energy Storage System (or Pack 1 in systems with only one pack). Not Operational is used when the module is initializing or not able to function (e.g. internal m...";
CM_ SG_ 2365333758 HvessModule49OperationalStatus "HVESS Module 49 Operational Status : Operational Status of Module 49 in the High Voltage Energy Storage System (or Pack 1 in systems with only one pack). Not Operational is used when the module is initializing or not able to function (e.g. internal m...";
CM_ SG_ 2365333758 HvessModule50OperationalStatus "HVESS Module 50 Operational Status : Operational Status of Module 50 in the High Voltage Energy Storage System (or Pack 1 in systems with only one pack). Not Operational is used when the module is initializing or not able to function (e.g. internal m...";
CM_ SG_ 2365333758 HvessModule51OperationalStatus "HVESS Module 51 Operational Status : Operational Status of Module 51 in the High Voltage Energy Storage System (or Pack 1 in systems with only one pack). Not Operational is used when the module is initializing or not able to function (e.g. internal m...";
CM_ SG_ 2365333758 HvessModule52OperationalStatus "HVESS Module 52 Operational Status : Operational Status of Module 52 in the High Voltage Energy Storage System (or Pack 1 in systems with only one pack). Not Operational is used when the module is initializing or not able to function (e.g. internal m...";
CM_ SG_ 2365333758 HvessModule53OperationalStatus "HVESS Module 53 Operational Status : Operational Status of Module 53 in the High Voltage Energy Storage System (or Pack 1 in systems with only one pack). Not Operational is used when the module is initializing or not able to function (e.g. internal m...";
CM_ SG_ 2365333758 HvessModule54OperationalStatus "HVESS Module 54 Operational Status : Operational Status of Module 54 in the High Voltage Energy Storage System (or Pack 1 in systems with only one pack). Not Operational is used when the module is initializing or not able to function (e.g. internal m...";
CM_ SG_ 2365333758 HvessModule55OperationalStatus "HVESS Module 55 Operational Status : Operational Status of Module 55 in the High Voltage Energy Storage System (or Pack 1 in systems with only one pack). Not Operational is used when the module is initializing or not able to function (e.g. internal m...";
CM_ SG_ 2365333758 HvessModule56OperationalStatus "HVESS Module 56 Operational Status : Operational Status of Module 56 in the High Voltage Energy Storage System (or Pack 1 in systems with only one pack). Not Operational is used when the module is initializing or not able to function (e.g. internal m...";
CM_ SG_ 2365333758 HvessModule57OperationalStatus "HVESS Module 57 Operational Status : Operational Status of Module 57 in the High Voltage Energy Storage System (or Pack 1 in systems with only one pack). Not Operational is used when the module is initializing or not able to function (e.g. internal m...";
CM_ SG_ 2365333758 HvessModule58OperationalStatus "HVESS Module 58 Operational Status : Operational Status of Module 58 in the High Voltage Energy Storage System (or Pack 1 in systems with only one pack). Not Operational is used when the module is initializing or not able to function (e.g. internal m...";
CM_ SG_ 2365333758 HvessModule59OperationalStatus "HVESS Module 59 Operational Status : Operational Status of Module 59 in the High Voltage Energy Storage System (or Pack 1 in systems with only one pack). Not Operational is used when the module is initializing or not able to function (e.g. internal m...";
CM_ SG_ 2365333758 HvessModule60OperationalStatus "HVESS Module 60 Operational Status : Operational Status of Module 60 in the High Voltage Energy Storage System (or Pack 1 in systems with only one pack). Not Operational is used when the module is initializing or not able to function (e.g. internal m...";
CM_ SG_ 2365333758 HvessModule61OperationalStatus "HVESS Module 61 Operational Status : Operational Status of Module 61 in the High Voltage Energy Storage System (or Pack 1 in systems with only one pack). Not Operational is used when the module is initializing or not able to function (e.g. internal m...";
CM_ SG_ 2365333758 HvessModule62OperationalStatus "HVESS Module 62 Operational Status : Operational Status of Module 62 in the High Voltage Energy Storage System (or Pack 1 in systems with only one pack). Not Operational is used when the module is initializing or not able to function (e.g. internal m...";
CM_ SG_ 2365333758 HvessModule63OperationalStatus "HVESS Module 63 Operational Status : Operational Status of Module 63 in the High Voltage Energy Storage System (or Pack 1 in systems with only one pack). Not Operational is used when the module is initializing or not able to function (e.g. internal m...";
CM_ SG_ 2365333758 HvessModule64OperationalStatus "HVESS Module 64 Operational Status : Operational Status of Module 64 in the High Voltage Energy Storage System (or Pack 1 in systems with only one pack). Not Operational is used when the module is initializing or not able to function (e.g. internal m...";
CM_ BO_ 2365334014 "High Voltage Energy Storage System Module Status 3";
CM_ SG_ 2365334014 HvessModule65OperationalStatus "HVESS Module 65 Operational Status : Operational Status of Module 65 in the High Voltage Energy Storage System (or Pack 1 in systems with only one pack). Not Operational is used when the module is initializing or not able to function (e.g. internal m...";
CM_ SG_ 2365334014 HvessModule66OperationalStatus "HVESS Module 66 Operational Status : Operational Status of Module 66 in the High Voltage Energy Storage System (or Pack 1 in systems with only one pack). Not Operational is used when the module is initializing or not able to function (e.g. internal m...";
CM_ SG_ 2365334014 HvessModule67OperationalStatus "HVESS Module 67 Operational Status : Operational Status of Module 67 in the High Voltage Energy Storage System (or Pack 1 in systems with only one pack). Not Operational is used when the module is initializing or not able to function (e.g. internal m...";
CM_ SG_ 2365334014 HvessModule68OperationalStatus "HVESS Module 68 Operational Status : Operational Status of Module 68 in the High Voltage Energy Storage System (or Pack 1 in systems with only one pack). Not Operational is used when the module is initializing or not able to function (e.g. internal m...";
CM_ SG_ 2365334014 HvessModule69OperationalStatus "HVESS Module 69 Operational Status : Operational Status of Module 69 in the High Voltage Energy Storage System (or Pack 1 in systems with only one pack). Not Operational is used when the module is initializing or not able to function (e.g. internal m...";
CM_ SG_ 2365334014 HvessModule70OperationalStatus "HVESS Module 70 Operational Status : Operational Status of Module 70 in the High Voltage Energy Storage System (or Pack 1 in systems with only one pack). Not Operational is used when the module is initializing or not able to function (e.g. internal m...";
CM_ SG_ 2365334014 HvessModule71OperationalStatus "HVESS Module 71 Operational Status : Operational Status of Module 71 in the High Voltage Energy Storage System (or Pack 1 in systems with only one pack). Not Operational is used when the module is initializing or not able to function (e.g. internal m...";
CM_ SG_ 2365334014 HvessModule72OperationalStatus "HVESS Module 72 Operational Status : Operational Status of Module 72 in the High Voltage Energy Storage System (or Pack 1 in systems with only one pack). Not Operational is used when the module is initializing or not able to function (e.g. internal m...";
CM_ SG_ 2365334014 HvessModule73OperationalStatus "HVESS Module 73 Operational Status : Operational Status of Module 73 in the High Voltage Energy Storage System (or Pack 1 in systems with only one pack). Not Operational is used when the module is initializing or not able to function (e.g. internal m...";
CM_ SG_ 2365334014 HvessModule74OperationalStatus "HVESS Module 74 Operational Status : Operational Status of Module 74 in the High Voltage Energy Storage System (or Pack 1 in systems with only one pack). Not Operational is used when the module is initializing or not able to function (e.g. internal m...";
CM_ SG_ 2365334014 HvessModule75OperationalStatus "HVESS Module 75 Operational Status : Operational Status of Module 75 in the High Voltage Energy Storage System (or Pack 1 in systems with only one pack). Not Operational is used when the module is initializing or not able to function (e.g. internal m...";
CM_ SG_ 2365334014 HvessModule76OperationalStatus "HVESS Module 76 Operational Status : Operational Status of Module 76 in the High Voltage Energy Storage System (or Pack 1 in systems with only one pack). Not Operational is used when the module is initializing or not able to function (e.g. internal m...";
CM_ SG_ 2365334014 HvessModule77OperationalStatus "HVESS Module 77 Operational Status : Operational Status of Module 77 in the High Voltage Energy Storage System (or Pack 1 in systems with only one pack). Not Operational is used when the module is initializing or not able to function (e.g. internal m...";
CM_ SG_ 2365334014 HvessModule78OperationalStatus "HVESS Module 78 Operational Status : Operational Status of Module 78 in the High Voltage Energy Storage System (or Pack 1 in systems with only one pack). Not Operational is used when the module is initializing or not able to function (e.g. internal m...";
CM_ SG_ 2365334014 HvessModule79OperationalStatus "HVESS Module 79 Operational Status : Operational Status of Module 79 in the High Voltage Energy Storage System (or Pack 1 in systems with only one pack). Not Operational is used when the module is initializing or not able to function (e.g. internal m...";
CM_ SG_ 2365334014 HvessModule80OperationalStatus "HVESS Module 80 Operational Status : Operational Status of Module 80 in the High Voltage Energy Storage System (or Pack 1 in systems with only one pack). Not Operational is used when the module is initializing or not able to function (e.g. internal m...";
CM_ SG_ 2365334014 HvessModule81OperationalStatus "HVESS Module 81 Operational Status : Operational Status of Module 81 in the High Voltage Energy Storage System (or Pack 1 in systems with only one pack). Not Operational is used when the module is initializing or not able to function (e.g. internal m...";
CM_ SG_ 2365334014 HvessModule82OperationalStatus "HVESS Module 82 Operational Status : Operational Status of Module 82 in the High Voltage Energy Storage System (or Pack 1 in systems with only one pack). Not Operational is used when the module is initializing or not able to function (e.g. internal m...";
CM_ SG_ 2365334014 HvessModule83OperationalStatus "HVESS Module 83 Operational Status : Operational Status of Module 83 in the High Voltage Energy Storage System (or Pack 1 in systems with only one pack). Not Operational is used when the module is initializing or not able to function (e.g. internal m...";
CM_ SG_ 2365334014 HvessModule84OperationalStatus "HVESS Module 84 Operational Status : Operational Status of Module 84 in the High Voltage Energy Storage System (or Pack 1 in systems with only one pack). Not Operational is used when the module is initializing or not able to function (e.g. internal m...";
CM_ SG_ 2365334014 HvessModule85OperationalStatus "HVESS Module 85 Operational Status : Operational Status of Module 85 in the High Voltage Energy Storage System (or Pack 1 in systems with only one pack). Not Operational is used when the module is initializing or not able to function (e.g. internal m...";
CM_ SG_ 2365334014 HvessModule86OperationalStatus "HVESS Module 86 Operational Status : Operational Status of Module 86 in the High Voltage Energy Storage System (or Pack 1 in systems with only one pack). Not Operational is used when the module is initializing or not able to function (e.g. internal m...";
CM_ SG_ 2365334014 HvessModule87OperationalStatus "HVESS Module 87 Operational Status : Operational Status of Module 87 in the High Voltage Energy Storage System (or Pack 1 in systems with only one pack). Not Operational is used when the module is initializing or not able to function (e.g. internal m...";
CM_ SG_ 2365334014 HvessModule88OperationalStatus "HVESS Module 88 Operational Status : Operational Status of Module 88 in the High Voltage Energy Storage System (or Pack 1 in systems with only one pack). Not Operational is used when the module is initializing or not able to function (e.g. internal m...";
CM_ SG_ 2365334014 HvessModule89OperationalStatus "HVESS Module 89 Operational Status : Operational Status of Module 89 in the High Voltage Energy Storage System (or Pack 1 in systems with only one pack). Not Operational is used when the module is initializing or not able to function (e.g. internal m...";
CM_ SG_ 2365334014 HvessModule90OperationalStatus "HVESS Module 90 Operational Status : Operational Status of Module 90 in the High Voltage Energy Storage System (or Pack 1 in systems with only one pack). Not Operational is used when the module is initializing or not able to function (e.g. internal m...";
CM_ SG_ 2365334014 HvessModule91OperationalStatus "HVESS Module 91 Operational Status : Operational Status of Module 91 in the High Voltage Energy Storage System (or Pack 1 in systems with only one pack). Not Operational is used when the module is initializing or not able to function (e.g. internal m...";
CM_ SG_ 2365334014 HvessModule92OperationalStatus "HVESS Module 92 Operational Status : Operational Status of Module 92 in the High Voltage Energy Storage System (or Pack 1 in systems with only one pack). Not Operational is used when the module is initializing or not able to function (e.g. internal m...";
CM_ SG_ 2365334014 HvessModule93OperationalStatus "HVESS Module 93 Operational Status : Operational Status of Module 93 in the High Voltage Energy Storage System (or Pack 1 in systems with only one pack). Not Operational is used when the module is initializing or not able to function (e.g. internal m...";
CM_ SG_ 2365334014 HvessModule94OperationalStatus "HVESS Module 94 Operational Status : Operational Status of Module 94 in the High Voltage Energy Storage System (or Pack 1 in systems with only one pack). Not Operational is used when the module is initializing or not able to function (e.g. internal m...";
CM_ SG_ 2365334014 HvessModule95OperationalStatus "HVESS Module 95 Operational Status : Operational Status of Module 95 in the High Voltage Energy Storage System (or Pack 1 in systems with only one pack). Not Operational is used when the module is initializing or not able to function (e.g. internal m...";
CM_ SG_ 2365334014 HvessModule96OperationalStatus "HVESS Module 96 Operational Status : Operational Status of Module 96 in the High Voltage Energy Storage System (or Pack 1 in systems with only one pack). Not Operational is used when the module is initializing or not able to function (e.g. internal m...";
CM_ BO_ 2566662398 "Cruise Control / Vehicle Speed 6";
CM_ SG_ 2566662398 CrrntRdwVhlSpdLmtMd "Current Roadway Vehicle Speed Limit Mode: This parameter indicates if the current roadway vehicle speed limit is actively applied.0000b = Disabled0001b = Inactive0010b = Active, Operator Override allowed0011b = Operator Override0100b = Active, Operat...";
CM_ SG_ 2566662398 SltdRdwVhlSpdLmt "Selected Roadway Vehicle Speed Limit: The value in this parameter defines a pending change in SPN 22772 (Current Roadway Vehicle Speed Limit) when SPN 22770 (Current Roadway Vehicle Speed Limit Mode) is 0010b (Active, Operator Override is allowed), 0...";
CM_ SG_ 2566662398 CurrentRoadwayVehicleSpeedLimit "Current Roadway Vehicle Speed Limit: The vehicle speed limit in effect will be provided in this parameter when the SPN 22770 (Current Roadway Vehicle Speed Limit Mode) is 0010b (Active, Operator Override is allowed) or 0100b (Active, Operator Overrid...";
CM_ SG_ 2566662398 MapBasedVehicleSpeedLimit "Map Based Vehicle Speed Limit: The vehicle speed limit provided by digital map data.Parameter Specific Indicator: A value of FB00h indicates there is not a speed limit provided by the map for the current location.Note:  See SPN 21793 (Traffic Sign Sp...";
CM_ SG_ 2566662398 CrrntRdwVhlSpdLmtDgrdtnStts "Current Roadway Vehicle Speed Limit Degradation Status: Indicates the status of the system's capability to limit the vehicle speed by SPN 22772 (Current Roadway Vehicle Speed Limit). 000b = No Degradation - The Roadway Vehicle Speed Limit algorithm i...";
CM_ BO_ 2365342974 "High Voltage Energy Storage System Data 15";
CM_ SG_ 2365342974 HvssNmnlDshrgCrrntLmt "HVESS Nominal Discharge Current Limit: The nominal current flow limit out of the High Voltage Energy Storage System (or Pack 1 in systems with only one pack). This limit is a preferred boundary for normal operation. Operating within this limit redu...";
CM_ SG_ 2365342974 HvessNominalChargeCurrentLimit "HVESS Nominal Charge Current Limit: The nominal current flow limit into the High Voltage Energy Storage System (or Pack 1 in systems with only one pack). This limit is a preferred boundary for normal operation. Operating within this limit reduces n...";
CM_ BO_ 2566522622 "Dash Display 3";
CM_ SG_ 2566522622 PrdtvVhlSpdAdjstmntIndtrStt "Predictive Vehicle Speed Adjustment Indicator State: Indicates how the desired set speed will be adjusted as a result of an algorithm that attempts to improve powertrain efficiency using information about the upcoming roadway.000b = Inactive001b = De...";
CM_ SG_ 2566522622 PrdtvVhlSpdAdjstmntSpd "Predictive Vehicle Speed Adjustment Speed: This parameter is vehicle speed that the vehicle may deviate from current speed for powertrain efficiency purposes when SPN 23121 (Predictive Vehicle Speed Adjustment Indicator State) is 001b (Decrease) or 0...";
CM_ BO_ 2566523134 "Reference Time";
CM_ SG_ 2566523134 ReferenceTime "Reference Time: Reference time in seconds.If reference time is not supported but the CA still wants to use SPN 23072 (Time Tx Reason) to report unexpected device restarts then set this SPN to FFFFFFFFh and set SPN 23071 (Time Epoch) to 1111b.";
CM_ SG_ 2566523134 ReferenceTimeFractional "Reference Time (Fractional): A time value indicating fractional time in mus.This parameter is used in combination with SPN 23069 (Reference Time). The resulting value for reference time will be calculated by adding these two parameters.Note: When time...";
CM_ SG_ 2566523134 TimeEpoch "Time Epoch: Indicates the reference point for the time.0000b - Device Runtime. Time is relative to when the device hardware last started.0001b - Device Lifetime. Time is operational life of the device. Value persists across restarts0010b - Modified U...";
CM_ SG_ 2566523134 TimeTxReason "Time Tx Reason: Transmission Reason. 0000b - Normal. System has not restarted.0001b - Power-on. 0010b - External Reset. 0011b - Software Reset.0100b - Software Exception. (e.g. watchdog, division by zero, etc).0101b - Brown out. Supply voltage to the...";
CM_ BO_ 2566523390 "Software History";
CM_ SG_ 2566523390 TotalSoftwareDistance "Total Software Distance: Total distance accumulated over the life of the software in the ECU. This value is reset to 0 km when the ECU is reflashed or the ECU is replaced.";
CM_ BO_ 2352938750 "Fuel Cell System Control Command";
CM_ SG_ 2352938750 FuelCellSystemControlCommandCrc "Fuel Cell System Control Command CRC: The CRC is defined as follows: - Length: 8 bits- Polynomial: x^8+x^5+x^3+x^2+x+1- Initial Value: FFh- Input Data Reflection: Not reflected- Result Data Reflection: Not reflected- XOR value: FFh SAE makes no claim...";
CM_ SG_ 2352938750 FlCllSstmCntrlCmmndCntr "Fuel Cell System Control Command Counter: The message counter is used to detect situations where the transmitting ECU malfunction repeats the same frame all the time. The receiver of the information may use the counter parameter to detect this situat...";
CM_ SG_ 2352938750 FuelCellSystemStateCommand "Fuel Cell System State Command: Command to the fuel cell system to start the fuel cell or shut down the fuel cell system (FCS).0 = No command.1 = FCS perform system self-check command (e.g., Could be performed after FCS medium priority shutdown).  No...";
CM_ SG_ 2352938750 FlCllSstmCntrlMdCmmnd "Fuel Cell System Control Mode Command: Commanded control mode for the fuel cell system.  See SPN  23151 (Fuel Cell System Net Output Command) for the commanded value and how it is associated with this parameter.0 = No control mode requested1 = Power ...";
CM_ SG_ 2352938750 FuelCellSystemNetOutputCommand "Fuel Cell System Net Output Command: The net output command to the fuel cell system.  If SPN 23150 (Fuel Cell System Control Mode Command) is 1 (Power control mode), then this parameter is a power value expressed as a percent of SPN 23144 (Fuel Cell ...";
CM_ SG_ 2352938750 FuelCellSystemPurgeWaterCommand "Fuel Cell System Purge Water Command: 0 = Water is not commanded to be purged from the fuel cell stacks1 = Water is commanded to be purged from the fuel cell stacks at the next shutdown2 = Water is commanded to be purged from the fuel cell stacks imm...";
CM_ BO_ 2353004286 "Fuel Cell System Power Limit Command";
CM_ SG_ 2353004286 FlCllSstmPwrLmtCmmndCr "Fuel Cell System Power Limit Command CRC: The CRC is defined as follows: - Length: 8 bits- Polynomial: x^8+x^5+x^3+x^2+x+1- Initial Value: FFh- Input Data Reflection: Not reflected- Result Data Reflection: Not reflected- XOR value: FFh SAE makes no c...";
CM_ SG_ 2353004286 FlCllSstmPwrLmtCmmndCntr "Fuel Cell System Power Limit Command Counter: The message counter is used to detect situations where the transmitting ECU malfunction repeats the same frame all the time. The receiver of the information may use the counter parameter to detect this si...";
CM_ SG_ 2353004286 FlCllSstmNtPwrMxmmLmtCmmnd "Fuel Cell System Net Power Maximum Limit Command: The commanded maximum available net power that can be provided by the fuel cell system to high voltage output loads.  It is expressed as a percent of SPN 23144 (Fuel Cell System Reference Power).If mu...";
CM_ SG_ 2353004286 FlCllSstmNtPwrMnmmLmtCmmnd "Fuel Cell System Net Power Minimum Limit Command: The commanded minimum available net power that can be provided by the fuel cell system to high voltage output loads.  It is expressed as a percent of SPN 23144 (Fuel Cell System Reference Power).If mu...";
CM_ BO_ 2353069822 "Fuel Cell System Current Limit Command";
CM_ SG_ 2353069822 FlCllSstmCrrntLmtCmmndCr "Fuel Cell System Current Limit Command CRC: The CRC is defined as follows: - Length: 8 bits- Polynomial: x^8+x^5+x^3+x^2+x+1- Initial Value: FFh- Input Data Reflection: Not reflected- Result Data Reflection: Not reflected- XOR value: FFh SAE makes no...";
CM_ SG_ 2353069822 FlCllSstmCrrntLmtCmmndCntr "Fuel Cell System Current Limit Command Counter: The message counter is used to detect situations where the transmitting ECU malfunction repeats the same frame all the time. The receiver of the information may use the counter parameter to detect this ...";
CM_ SG_ 2353069822 FlCllSstmNtCrrntMxmmLmtCmmnd "Fuel Cell System Net Current Maximum Limit Command: The commanded maximum available net current sent to the fuel cell system.  It is expressed as a percent of SPN 23145 (Fuel Cell System Reference Current).If multiple devices provide this parameter, ...";
CM_ SG_ 2353069822 FlCllSstmNtCrrntMnmmLmtCmmnd "Fuel Cell System Net Current Minimum Limit Command: The commanded minimum available net current sent to the fuel cell system.  It is expressed as a percent of SPN 23145 (Fuel Cell System Reference Current).If multiple devices provide this parameter, ...";
CM_ BO_ 2554461950 "Hydrogen Storage System Control Command";
CM_ SG_ 2554461950 HdrgnStrgSstmCntrlCmmndCr "Hydrogen Storage System Control Command CRC: The CRC is defined as follows: - Length: 8 bits- Polynomial: x^8+x^5+x^3+x^2+x+1- Initial Value: FFh- Input Data Reflection: Not reflected- Result Data Reflection: Not reflected- XOR value: FFh SAE makes n...";
CM_ SG_ 2554461950 HdrgnStrgSstmCntrlCmmndCntr "Hydrogen Storage System Control Command Counter: The message counter is used to detect situations where the transmitting ECU malfunction repeats the same frame all the time. The receiver of the information may use the counter parameter to detect this...";
CM_ SG_ 2554461950 HydrogenSupplyRequest "Hydrogen Supply Request: Request to the hydrogen storage system to supply hydrogen to the fuel cell system.  The hydrogen storage system may determine that it cannot honor the request.00b = Hydrogen is not requested01b = Hydrogen is requested10b = Re...";
CM_ BO_ 2353200894 "Transmission Control 4";
CM_ SG_ 2353200894 TransmissionOverrideControlMode "Transmission Override Control Mode: The override control mode defines the type of control mode used to control transmission operation.00b = Override disabled - Disable any existing control commanded by the source of this command.01b = Speed control -...";
CM_ SG_ 2353200894 TrnsmssnOvrrdCntrlMdPrrt "Transmission Override Control Mode Priority: This field is used as an input to the transmission to determine the priority of the Override Control Mode received in the Torque/Speed Control message.  The default is 11b (Low priority).  It is not requir...";
CM_ SG_ 2353200894 TrnsmssnRqstdOtptShftSpd "Transmission Requested Output Shaft Speed: Used to request output shaft speed of the transmission which has a output through a driveline to the wheels of a machine/vehicle.";
CM_ SG_ 2353200894 TrnsmssnRqstdTrqTrqLmt "Transmission Requested Torque / Torque Limit: Requested transmission output torque measured as a percentage of Transmission Reference Torque (SPN 7778). This is the output torque at which the transmission is expected to operate if the torque control ...";
CM_ SG_ 2353200894 TrnsmssnAtNtrlAtRtrnEnlSwth "Transmission Auto-Neutral (Auto-Return) Enable Switch: This enable switch is required for use with interfaces using SPN 23374 (Transmission Auto-Neutral (Auto-Return) Request).  It allows the operator to prohibit the transmission from responding to t...";
CM_ SG_ 2353200894 TrnsmssnAtNtrlAtRtrnRqst "Transmission Auto-Neutral (Auto-Return) Request: This parameter conveys a vehicle system desire to (a) override the operator's current shift selector request (e.g. Drive, Reverse) and shift the transmission into Neutral, and then (b) exit the Neutral...";
CM_ SG_ 2353200894 TransmissionControl4Counter "Transmission Control 4 Counter: The message counter is used to detect situations where the transmitting ECU malfunction repeats the same frame all the time. The receiver of the information may use the counter parameter to detect this situation. The t...";
CM_ SG_ 2353200894 TransmissionControl4Crc "Transmission Control 4 CRC: The CRC is defined as follows: - Length: 8 bits- Polynomial: x^8+x^5+x^3+x^2+x+1- Initial Value: FFh- Input Data Reflection: Not reflected- Result Data Reflection: Not reflected- XOR value: FFh SAE makes no claim of the fu...";
CM_ BO_ 2554789630 "API Select";
CM_ SG_ 2554789630 SelectedEvApiId "Selected EV API ID: Used with SPN 23224 (Selected EV API Manufacturer ID) to select one of the target device's supported APIs.";
CM_ SG_ 2554789630 SelectedEvApiManufacturerId "Selected EV API Manufacturer ID: Used with SPN 23223 (Selected EV API ID) to select one of the target device's supported APIs.";
CM_ SG_ 2554789630 SelectedEvApiDeviceRole "Selected EV API Device Role: The role that the sender of this PG will be using. This will be API specific, but for example if the target device only supports a 'server' role then this SP will specifiy a 'client' role.See SPN 23216 (EV API Supported R...";
CM_ SG_ 2554789630 SelectedEvApiMajorVersion "Selected EV API Major Version: Used with SPN 23227 (Selected EV API Minor Version) to state which version of the API the sender of this PG wants to use.";
CM_ SG_ 2554789630 SelectedEvApiMinorVersion "Selected EV API Minor Version: Used with SPN 23226 (Selected EV API Major Version) to state which version of the API the sender of this PG wants to use.This SP shall be within the supported range of the target's minor interfaces. See SPN 23218 (EV AP...";
CM_ BO_ 2364574206 "Motor/Generator 1 Inverter Control Status 3";
CM_ SG_ 2364574206 MtrGnrtr1InvrtrCntrlStts3Cr "Motor/Generator 1 Inverter Control Status 3 CRC: The CRC is defined as follows:- Length: 8 bits- Polynomial: x^8+x^5+x^3+x^2+x+1- Initial Value: FFh- Input Data Reflection: Not reflected- Result Data Reflection: Not reflected- XOR value: FFhSAE makes...";
CM_ SG_ 2364574206 MtrGnrtr1InvrtrCntrlStts3Cntr "Motor/Generator 1 Inverter Control Status 3 Counter: The message counter is used to detect situations where the transmitting ECU malfunction repeats the same frame all the time. The receiver of the information may use the counter parameter to detect ...";
CM_ SG_ 2364574206 MotorGenerator1MotorAngle "Motor/Generator 1 Motor Angle: The measured value of the motor shaft angle.  A Parameter Specific Indicator value of FB00h indicates that this parameter is supported, but signal aliasing due to high motor speed, such as rotation greater than 180° sin...";
CM_ BO_ 2364574462 "Motor/Generator 2 Inverter Control Status 3";
CM_ SG_ 2364574462 MtrGnrtr2InvrtrCntrlStts3Cr "Motor/Generator 2 Inverter Control Status 3 CRC: The CRC is defined as follows:- Length: 8 bits- Polynomial: x^8+x^5+x^3+x^2+x+1- Initial Value: FFh- Input Data Reflection: Not reflected- Result Data Reflection: Not reflected- XOR value: FFhSAE makes...";
CM_ SG_ 2364574462 MtrGnrtr2InvrtrCntrlStts3Cntr "Motor/Generator 2 Inverter Control Status 3 Counter: The message counter is used to detect situations where the transmitting ECU malfunction repeats the same frame all the time. The receiver of the information may use the counter parameter to detect ...";
CM_ SG_ 2364574462 MotorGenerator2MotorAngle "Motor/Generator 2 Motor Angle: The measured value of the motor shaft angle.  A Parameter Specific Indicator value of FB00h indicates that this parameter is supported, but signal aliasing due to high motor speed, such as rotation greater than 180° sin...";
CM_ BO_ 2364574718 "Motor/Generator 3 Inverter Control Status 3";
CM_ SG_ 2364574718 MtrGnrtr3InvrtrCntrlStts3Cr "Motor/Generator 3 Inverter Control Status 3 CRC: The CRC is defined as follows:- Length: 8 bits- Polynomial: x^8+x^5+x^3+x^2+x+1- Initial Value: FFh- Input Data Reflection: Not reflected- Result Data Reflection: Not reflected- XOR value: FFhSAE makes...";
CM_ SG_ 2364574718 MtrGnrtr3InvrtrCntrlStts3Cntr "Motor/Generator 3 Inverter Control Status 3 Counter: The message counter is used to detect situations where the transmitting ECU malfunction repeats the same frame all the time. The receiver of the information may use the counter parameter to detect ...";
CM_ SG_ 2364574718 MotorGenerator3MotorAngle "Motor/Generator 3 Motor Angle: The measured value of the motor shaft angle.  A Parameter Specific Indicator value of FB00h indicates that this parameter is supported, but signal aliasing due to high motor speed, such as rotation greater than 180° sin...";
CM_ BO_ 2364574974 "Motor/Generator 4 Inverter Control Status 3";
CM_ SG_ 2364574974 MtrGnrtr4InvrtrCntrlStts3Cr "Motor/Generator 4 Inverter Control Status 3 CRC: The CRC is defined as follows:- Length: 8 bits- Polynomial: x^8+x^5+x^3+x^2+x+1- Initial Value: FFh- Input Data Reflection: Not reflected- Result Data Reflection: Not reflected- XOR value: FFhSAE makes...";
CM_ SG_ 2364574974 MtrGnrtr4InvrtrCntrlStts3Cntr "Motor/Generator 4 Inverter Control Status 3 Counter: The message counter is used to detect situations where the transmitting ECU malfunction repeats the same frame all the time. The receiver of the information may use the counter parameter to detect ...";
CM_ SG_ 2364574974 MotorGenerator4MotorAngle "Motor/Generator 4 Motor Angle: The measured value of the motor shaft angle.  A Parameter Specific Indicator value of FB00h indicates that this parameter is supported, but signal aliasing due to high motor speed, such as rotation greater than 180° sin...";
CM_ BO_ 2364575230 "Motor/Generator 5 Inverter Control Status 3";
CM_ SG_ 2364575230 MtrGnrtr5InvrtrCntrlStts3Cr "Motor/Generator 5 Inverter Control Status 3 CRC: The CRC is defined as follows:- Length: 8 bits- Polynomial: x^8+x^5+x^3+x^2+x+1- Initial Value: FFh- Input Data Reflection: Not reflected- Result Data Reflection: Not reflected- XOR value: FFhSAE makes...";
CM_ SG_ 2364575230 MtrGnrtr5InvrtrCntrlStts3Cntr "Motor/Generator 5 Inverter Control Status 3 Counter: The message counter is used to detect situations where the transmitting ECU malfunction repeats the same frame all the time. The receiver of the information may use the counter parameter to detect ...";
CM_ SG_ 2364575230 MotorGenerator5MotorAngle "Motor/Generator 5 Motor Angle: The measured value of the motor shaft angle.  A Parameter Specific Indicator value of FB00h indicates that this parameter is supported, but signal aliasing due to high motor speed, such as rotation greater than 180° sin...";
CM_ BO_ 2364575486 "Motor/Generator 6 Inverter Control Status 3";
CM_ SG_ 2364575486 MtrGnrtr6InvrtrCntrlStts3Cr "Motor/Generator 6 Inverter Control Status 3 CRC: The CRC is defined as follows:- Length: 8 bits- Polynomial: x^8+x^5+x^3+x^2+x+1- Initial Value: FFh- Input Data Reflection: Not reflected- Result Data Reflection: Not reflected- XOR value: FFhSAE makes...";
CM_ SG_ 2364575486 MtrGnrtr6InvrtrCntrlStts3Cntr "Motor/Generator 6 Inverter Control Status 3 Counter: The message counter is used to detect situations where the transmitting ECU malfunction repeats the same frame all the time. The receiver of the information may use the counter parameter to detect ...";
CM_ SG_ 2364575486 MotorGenerator6MotorAngle "Motor/Generator 6 Motor Angle: The measured value of the motor shaft angle.  A Parameter Specific Indicator value of FB00h indicates that this parameter is supported, but signal aliasing due to high motor speed, such as rotation greater than 180° sin...";
CM_ BO_ 2364764670 "Fuel Cell System Controller Information";
CM_ SG_ 2364764670 FlCllSstmOprtngInfrmtnCr "Fuel Cell System Operating Information CRC: The CRC is defined as follows: - Length: 8 bits- Polynomial: x^8+x^5+x^3+x^2+x+1- Initial Value: FFh- Input Data Reflection: Not reflected- Result Data Reflection: Not reflected- XOR value: FFh SAE makes no...";
CM_ SG_ 2364764670 FlCllSstmOprtngInfrmtnCntr "Fuel Cell System Operating Information Counter: The message counter is used to detect situations where the transmitting ECU malfunction repeats the same frame all the time. The receiver of the information may use the counter parameter to detect this ...";
CM_ SG_ 2364764670 FuelCellSystemNetPower "Fuel Cell System Net Power: The power at the output of the fuel cell system.  It is expressed as a percent of SPN 23144 (Fuel Cell System Reference Power).A negative net power indicates the fuel cell system is draining power from the high-voltage bus...";
CM_ SG_ 2364764670 FuelCellSystemNetCurrent "Fuel Cell System Net Current: The fuel cell system net current.  It is expressed as a percent of SPN 23145 (Fuel Cell System Reference Current).A negative net current indicates the fuel cell system is draining power from the high-voltage bus to provi...";
CM_ SG_ 2364764670 FuelCellSystemVoltage "Fuel Cell System Voltage: The voltage at the output of the fuel cell system that would be measured by any high voltage loads.  It is expressed as a percent of SPN 23146 (Fuel Cell System Reference Voltage).";
CM_ BO_ 2364764926 "Fuel Cell System Minimum Power Information";
CM_ SG_ 2364764926 FlCllSstmMnmmPwrInfrmtnCr "Fuel Cell System Minimum Power Information CRC: The CRC is defined as follows: - Length: 8 bits- Polynomial: x^8+x^5+x^3+x^2+x+1- Initial Value: FFh- Input Data Reflection: Not reflected- Result Data Reflection: Not reflected- XOR value: FFh SAE make...";
CM_ SG_ 2364764926 FlCllSstmMnmmPwrInfrmtnCntr "Fuel Cell System Minimum Power Information Counter: The message counter is used to detect situations where the transmitting ECU malfunction repeats the same frame all the time. The receiver of the information may use the counter parameter to detect t...";
CM_ SG_ 2364764926 FlCllSstmAtlMnmmAvllNtPwr "Fuel Cell System Actual Minimum Available Net Power: The minimum available net power of the fuel cell system. It is expressed as a percent of SPN 23144 (Fuel Cell System Reference Power).  This will reflect the limit received in SPN 23161 (Fuel Cell ...";
CM_ SG_ 2364764926 FlCllSstmIntrnlMnmmAvllNtPwr "Fuel Cell System Internal Minimum Available Net Power: The minimum net power calculated within the fuel cell system controller application. It is expressed as a percent of SPN 23144 (Fuel Cell System Reference Power).";
CM_ SG_ 2364764926 FCSstAtMAvNtPwSAddss "Fuel Cell System Actual Minimum Available Net Power Source Address: This parameter indicates the source address of the device that is currently providing the value in SPN 23164 (Fuel Cell System Actual Minimum Available Net Power).  If the value of S...";
CM_ BO_ 2364765182 "Fuel Cell System Maximum Power Information";
CM_ SG_ 2364765182 FlCllSstmMxmmPwrInfrmtnCr "Fuel Cell System Maximum Power Information CRC: The CRC is defined as follows: - Length: 8 bits- Polynomial: x^8+x^5+x^3+x^2+x+1- Initial Value: FFh- Input Data Reflection: Not reflected- Result Data Reflection: Not reflected- XOR value: FFh SAE make...";
CM_ SG_ 2364765182 FlCllSstmMxmmPwrInfrmtnCntr "Fuel Cell System Maximum Power Information Counter: The message counter is used to detect situations where the transmitting ECU malfunction repeats the same frame all the time. The receiver of the information may use the counter parameter to detect t...";
CM_ SG_ 2364765182 FlCllSstmAtlMxmmAvllNtPwr "Fuel Cell System Actual Maximum Available Net Power: The maximum available net power of the fuel cell system. It is expressed as a percent of SPN 23144 (Fuel Cell System Reference Power).  This will reflect the limit received in SPN 23160 (Fuel Cell ...";
CM_ SG_ 2364765182 FlCllSstmIntrnlMxmmAvllNtPwr "Fuel Cell System Internal Maximum Available Net Power: The maximum net power calculated within the fuel cell system controller application. It is expressed as a percent of SPN 23144 (Fuel Cell System Reference Power).";
CM_ SG_ 2364765182 FCSstAtMxAvNtPwSAddss "Fuel Cell System Actual Maximum Available Net Power Source Address: This parameter indicates the source address of the device that is currently providing the value in SPN 23169 (Fuel Cell System Actual Maximum Available Net Power).  If the value of S...";
CM_ BO_ 2364765438 "Fuel Cell System Minimum Current Information";
CM_ SG_ 2364765438 FlCllSstmMnmmCrrntInfrmtnCr "Fuel Cell System Minimum Current Information CRC: The CRC is defined as follows: - Length: 8 bits- Polynomial: x^8+x^5+x^3+x^2+x+1- Initial Value: FFh- Input Data Reflection: Not reflected- Result Data Reflection: Not reflected- XOR value: FFh SAE ma...";
CM_ SG_ 2364765438 FlCllSstmMnmmCrrntInfrmtnCntr "Fuel Cell System Minimum Current Information Counter: The message counter is used to detect situations where the transmitting ECU malfunction repeats the same frame all the time. The receiver of the information may use the counter parameter to detect...";
CM_ SG_ 2364765438 FlCllSstmAtlMnmmAvllNtCrrnt "Fuel Cell System Actual Minimum Available Net Current: The minimum available net current of the fuel cell system. It is expressed as a percent of SPN 23145 (Fuel Cell System Reference Current).  This will reflect the limit received in SPN 23175 (Fuel...";
CM_ SG_ 2364765438 FlCllSstmIntrnlMnmmAvllNtCrrnt "Fuel Cell System Internal Minimum Available Net Current: The minimum net current calculated within the fuel cell system controller application. It is expressed as a percent of SPN 23145 (Fuel Cell System Reference Current).";
CM_ SG_ 2364765438 FCSstAtMAvNtCtSAddss "Fuel Cell System Actual Minimum Available Net Current Source Address: This parameter indicates the source address of the device that is currently providing the value in SPN 23178 (Fuel Cell System Actual Minimum Available Net Current).  If the value ...";
CM_ BO_ 2364765694 "Fuel Cell System Maximum Current Information";
CM_ SG_ 2364765694 FlCllSstmMxmmCrrntInfrmtnCr "Fuel Cell System Maximum Current Information CRC: The CRC is defined as follows: - Length: 8 bits- Polynomial: x^8+x^5+x^3+x^2+x+1- Initial Value: FFh- Input Data Reflection: Not reflected- Result Data Reflection: Not reflected- XOR value: FFh SAE ma...";
CM_ SG_ 2364765694 FlCllSstmMxmmCrrntInfrmtnCntr "Fuel Cell System Maximum Current Information Counter: The message counter is used to detect situations where the transmitting ECU malfunction repeats the same frame all the time. The receiver of the information may use the counter parameter to detect...";
CM_ SG_ 2364765694 FlCllSstmAtlMxmmAvllNtCrrnt "Fuel Cell System Actual Maximum Available Net Current: The maximum available net current of the fuel cell system. It is expressed as a percent of SPN 23145 (Fuel Cell System Reference Current).  This will reflect the limit received in SPN 23174 (Fuel...";
CM_ SG_ 2364765694 FlCllSstmIntrnlMxmmAvllNtCrrnt "Fuel Cell System Internal Maximum Available Net Current: The maximum net current calculated within the fuel cell system controller application. It is expressed as a percent of SPN 23145 (Fuel Cell System Reference Current).";
CM_ SG_ 2364765694 FCSstAtMxAvNtCtSAddss "Fuel Cell System Actual Maximum Available Net Current Source Address: This parameter indicates the source address of the device that is currently providing the value in SPN 23183 (Fuel Cell System Actual Maximum Available Net Current).  If the value ...";
CM_ BO_ 2566092542 "Hydrogen Storage System Information";
CM_ SG_ 2566092542 HdrgnStrgSstmInfrmtnCr "Hydrogen Storage System Information CRC: The CRC is defined as follows: - Length: 8 bits- Polynomial: x^8+x^5+x^3+x^2+x+1- Initial Value: FFh- Input Data Reflection: Not reflected- Result Data Reflection: Not reflected- XOR value: FFh SAE makes no cl...";
CM_ SG_ 2566092542 HdrgnStrgSstmInfrmtnCntr "Hydrogen Storage System Information Counter: The message counter is used to detect situations where the transmitting ECU malfunction repeats the same frame all the time. The receiver of the information may use the counter parameter to detect this sit...";
CM_ SG_ 2566092542 HydrogenSupplyActiveStatus "Hydrogen Supply Active Status: Indicates if the hydrogen storage system is providing hydrogen to the fuel cell system.  This can be in response to SPN 23188 (Hydrogen Supply Request) or determined that it is needed by the fuel cell system controller....";
CM_ BO_ 2566092798 "Fuel Cell System Operating State";
CM_ SG_ 2566092798 FuelCellSystemOperatingStateCrc "Fuel Cell System Operating State CRC: The CRC is defined as follows: - Length: 8 bits- Polynomial: x^8+x^5+x^3+x^2+x+1- Initial Value: FFh- Input Data Reflection: Not reflected- Result Data Reflection: Not reflected- XOR value: FFh SAE makes no claim...";
CM_ SG_ 2566092798 FlCllSstmOprtngSttCntr "Fuel Cell System Operating State Counter: The message counter is used to detect situations where the transmitting ECU malfunction repeats the same frame all the time. The receiver of the information may use the counter parameter to detect this situat...";
CM_ SG_ 2566092798 FlCllSstmCldStrtAtvStts "Fuel Cell System Cold Start Active Status: Indicates if the fuel cell system is in a cold start state or not.00b = Cold start not active01b = Cold start active10b = Reserved11b = Not available";
CM_ SG_ 2566092798 FuelCellSystemControlMode "Fuel Cell System Control Mode: Indicates the mode in which the fuel cell system is presently controlled.0 = No control mode requested1 = Power control mode2 = Current control mode3 = Reserved4 = Reserved5 = Reserved6 = Reserved7 = Reserved8 = Reserve...";
CM_ SG_ 2566092798 FuelCellSystemOperationState "Fuel Cell System Operation State: Indicates the present operation state of the fuel cell system (FCS).0 = System self-check (e.g., checking configuration, external accessory evaluation, etc.).   The FCS will enter this state on its own during the ove...";
CM_ SG_ 2566092798 FuelCellSystemFaultLevel "Fuel Cell System Fault Level: Present active fault level of the fuel cell system.0 = No active fault1 = Warning fault2 = Derate fault3 = Shutdown fault4 = Emergency shutdown fault5 = Reserved6 = Reserved7 = Not Available";
CM_ SG_ 2566092798 FuelCellSystemHvilStatus "Fuel Cell System HVIL status: Reports the High Voltage Interlock Loop (HVIL) state.00b = HVIL Closed01b = HVIL Open10b = Error11b = Not Available";
CM_ SG_ 2566092798 FlCllSstmFltdShtdwnTp "Fuel Cell System Faulted Shutdown Type: Indicates the type of shutdown due to an internal fault condition that is in process (SPN 23196 is equal to 12) or has completed (SPN 23196 is equal to 13).  000b - Faulted shutdown is not occurring and has not...";
CM_ BO_ 2566093054 "Fuel Cell System Operations Request";
CM_ SG_ 2566093054 FlCllSstmOprtnsRqstCr "Fuel Cell System Operations Request CRC: The CRC is defined as follows: - Length: 8 bits- Polynomial: x^8+x^5+x^3+x^2+x+1- Initial Value: FFh- Input Data Reflection: Not reflected- Result Data Reflection: Not reflected- XOR value: FFh SAE makes no cl...";
CM_ SG_ 2566093054 FlCllSstmOprtnsRqstCntr "Fuel Cell System Operations Request Counter: The message counter is used to detect situations where the transmitting ECU malfunction repeats the same frame all the time. The receiver of the information may use the counter parameter to detect this sit...";
CM_ SG_ 2566093054 FCSstHVtPwSppItCd "Fuel Cell System High Voltage Power Supply Interlock Command: Indicates if the fuel cell system (FCS) indicates the high voltage power supply can be connected or commands that it not be disconnected if it is connected.00b = Fuel cell system is not re...";
CM_ BO_ 2566093310 "Fuel Cell Stack Information ";
CM_ SG_ 2566093310 FuelCellStackCurrent "Fuel Cell Stack Current: Fuel cell stack current. This is measured at the input side of the DCDC converter if one is present.  It is expressed as a percent of SPN 23145 (Fuel Cell System Reference Current).";
CM_ SG_ 2566093310 FuelCellStackVoltage "Fuel Cell Stack Voltage: Fuel cell stack voltage. This is measured at the input side of the DCDC converter if one is present.";
CM_ BO_ 2566093566 "Fuel Cell System Coolant Fan 1 Status 2";
CM_ SG_ 2566093566 FlCllSstmClntFn1Vltg "Fuel Cell System Coolant Fan 1 Voltage: The voltage level of the electrical bus that is utilized by this device as the power source/sink for generating motor torque, as measured at the input of this device.  Note that one design alternative for this ...";
CM_ SG_ 2566093566 FlCllSstmClntFn1Crrnt "Fuel Cell System Coolant Fan 1 Current: The current in or out of this device with respect to the electrical bus that is utilized by this device as the power source/sink for generating motor torque.  This parameter should be synchronized with SPN 2324...";
CM_ SG_ 2566093566 FlCllSstmClntFn1HvlStts "Fuel Cell System Coolant Fan 1 HVIL Status: High Voltage Interlock Loop (HVIL) state, as measured by this device.00b = HVIL Closed01b = HVIL Open10b = Error11b = Not Available";
CM_ SG_ 2566093566 FlCllSstmClntFn1PrntSpdStts "Fuel Cell System Coolant Fan 1 Percent Speed Status: Enable and direction status of the Fuel Cell System Coolant Fan 1 system or component.  This parameter is used with SPN 23244 (Fuel Cell System Coolant Fan 1 Percent Speed).00b = Accessory Motor Of...";
CM_ SG_ 2566093566 FlCllSstmClntFn1PrntSpd "Fuel Cell System Coolant Fan 1 Percent Speed: Speed of the Fuel Cell System Coolant Fan 1 in percentage of maximum speed.  This parameter is used with SPN 23243 (Fuel Cell System Coolant Fan 1 Percent Speed Status).";
CM_ BO_ 2566093822 "Fuel Cell System Coolant Fan 2 Status 2";
CM_ SG_ 2566093822 FlCllSstmClntFn2Vltg "Fuel Cell System Coolant Fan 2 Voltage: The voltage level of the electrical bus that is utilized by this device as the power source/sink for generating motor torque, as measured at the input of this device.  Note that one design alternative for this ...";
CM_ SG_ 2566093822 FlCllSstmClntFn2Crrnt "Fuel Cell System Coolant Fan 2 Current: The current in or out of this device with respect to the electrical bus that is utilized by this device as the power source/sink for generating motor torque.  This parameter should be synchronized with SPN 2325...";
CM_ SG_ 2566093822 FlCllSstmClntFn2HvlStts "Fuel Cell System Coolant Fan 2 HVIL Status: High Voltage Interlock Loop (HVIL) state, as measured by this device.00b = HVIL Closed01b = HVIL Open10b = Error11b = Not Available";
CM_ SG_ 2566093822 FlCllSstmClntFn2PrntSpdStts "Fuel Cell System Coolant Fan 2 Percent Speed Status: Enable and direction status of the Fuel Cell System Coolant Fan 2 system or component.  This parameter is used with SPN 23261 (Fuel Cell System Coolant Fan 2 Percent Speed).00b = Accessory Motor Of...";
CM_ SG_ 2566093822 FlCllSstmClntFn2PrntSpd "Fuel Cell System Coolant Fan 2 Percent Speed: Speed of the Fuel Cell System Coolant Fan 2 in percentage of maximum speed.  This parameter is used with SPN 23260 (Fuel Cell System Coolant Fan 2 Percent Speed Status).";
CM_ BO_ 2566094078 "Fuel Cell System Coolant Fan 3 Status 2";
CM_ SG_ 2566094078 FlCllSstmClntFn3Vltg "Fuel Cell System Coolant Fan 3 Voltage: The voltage level of the electrical bus that is utilized by this device as the power source/sink for generating motor torque, as measured at the input of this device.  Note that one design alternative for this ...";
CM_ SG_ 2566094078 FlCllSstmClntFn3Crrnt "Fuel Cell System Coolant Fan 3 Current: The current in or out of this device with respect to the electrical bus that is utilized by this device as the power source/sink for generating motor torque.  This parameter should be synchronized with SPN 2327...";
CM_ SG_ 2566094078 FlCllSstmClntFn3HvlStts "Fuel Cell System Coolant Fan 3 HVIL Status: High Voltage Interlock Loop (HVIL) state, as measured by this device.00b = HVIL Closed01b = HVIL Open10b = Error11b = Not Available";
CM_ SG_ 2566094078 FlCllSstmClntFn3PrntSpdStts "Fuel Cell System Coolant Fan 3 Percent Speed Status: Enable and direction status of the Fuel Cell System Coolant Fan 3 system or component.  This parameter is used with SPN 23278 (Fuel Cell System Coolant Fan 3 Percent Speed).00b = Accessory Motor Of...";
CM_ SG_ 2566094078 FlCllSstmClntFn3PrntSpd "Fuel Cell System Coolant Fan 3 Percent Speed: Speed of the Fuel Cell System Coolant Fan 3 in percentage of maximum speed.  This parameter is used with SPN 23277 (Fuel Cell System Coolant Fan 3 Percent Speed Status).";
CM_ BO_ 2566094334 "Fuel Cell System Coolant Fan 4 Status 2";
CM_ SG_ 2566094334 FlCllSstmClntFn4Vltg "Fuel Cell System Coolant Fan 4 Voltage: The voltage level of the electrical bus that is utilized by this device as the power source/sink for generating motor torque, as measured at the input of this device.  Note that one design alternative for this ...";
CM_ SG_ 2566094334 FlCllSstmClntFn4Crrnt "Fuel Cell System Coolant Fan 4 Current: The current in or out of this device with respect to the electrical bus that is utilized by this device as the power source/sink for generating motor torque.  This parameter should be synchronized with SPN 2329...";
CM_ SG_ 2566094334 FlCllSstmClntFn4HvlStts "Fuel Cell System Coolant Fan 4 HVIL Status: High Voltage Interlock Loop (HVIL) state, as measured by this device.00b = HVIL Closed01b = HVIL Open10b = Error11b = Not Available";
CM_ SG_ 2566094334 FlCllSstmClntFn4PrntSpdStts "Fuel Cell System Coolant Fan 4 Percent Speed Status: Enable and direction status of the Fuel Cell System Coolant Fan 4 system or component.  This parameter is used with SPN 23295 (Fuel Cell System Coolant Fan 4 Percent Speed).00b = Accessory Motor Of...";
CM_ SG_ 2566094334 FlCllSstmClntFn4PrntSpd "Fuel Cell System Coolant Fan 4 Percent Speed: Speed of the Fuel Cell System Coolant Fan 4 in percentage of maximum speed.  This parameter is used with SPN 23294 (Fuel Cell System Coolant Fan 4 Percent Speed Status).";
CM_ BO_ 2566094590 "HVESS Coolant Pump 1 Status 2";
CM_ SG_ 2566094590 HvessCoolantPump1Voltage "HVESS Coolant Pump 1 Voltage: The voltage level of the electrical bus that is utilized by this device as the power source/sink for generating motor torque, as measured at the input of this device. Note that one design alternative for this device util...";
CM_ SG_ 2566094590 HvessCoolantPump1Current "HVESS Coolant Pump 1 Current: The current in or out of this device with respect to the electrical bus that is utilized by this device as the power source/sink for generating motor torque.  This parameter should be synchronized with SPN 23421 (HVESS C...";
CM_ SG_ 2566094590 HvessCoolantPump1HvilStatus "HVESS Coolant Pump 1 HVIL Status: High Voltage Interlock Loop (HVIL) state, as measured by this device.00b = HVIL Closed01b = HVIL Open10b = Error11b = Not Available";
CM_ SG_ 2566094590 HvssClntPmp1PrntSpdStts "HVESS Coolant Pump 1 Percent Speed Status: Enable and direction status of the HVESS Coolant Pump 1 system or component. This parameter is used with SPN 23425 (HVESS Coolant Pump 1 Percent Speed).00b = Accessory Motor Off01b = Accessory Motor On - Nor...";
CM_ SG_ 2566094590 HvessCoolantPump1PercentSpeed "HVESS Coolant Pump 1 Percent Speed: Speed of the HVESS Coolant Pump 1 system or component in percentage of maximum speed.  This parameter is used with SPN 23424 (HVESS Coolant Pump 1 Percent Speed Status).";
CM_ BO_ 2566094846 "HVESS Coolant Pump 2 Status 2";
CM_ SG_ 2566094846 HvessCoolantPump2Voltage "HVESS Coolant Pump 2 Voltage: The voltage level of the electrical bus that is utilized by this device as the power source/sink for generating motor torque, as measured at the input of this device. Note that one design alternative for this device util...";
CM_ SG_ 2566094846 HvessCoolantPump2Current "HVESS Coolant Pump 2 Current: The current in or out of this device with respect to the electrical bus that is utilized by this device as the power source/sink for generating motor torque.  This parameter should be synchronized with SPN 23438 (HVESS C...";
CM_ SG_ 2566094846 HvessCoolantPump2HvilStatus "HVESS Coolant Pump 2 HVIL Status: High Voltage Interlock Loop (HVIL) state, as measured by this device.00b = HVIL Closed01b = HVIL Open10b = Error11b = Not Available";
CM_ SG_ 2566094846 HvssClntPmp2PrntSpdStts "HVESS Coolant Pump 2 Percent Speed Status: Enable and direction status of the HVESS Coolant Pump 2 system or component. This parameter is used with SPN 23442 (HVESS Coolant Pump 2 Percent Speed).00b = Accessory Motor Off01b = Accessory Motor On - Nor...";
CM_ SG_ 2566094846 HvessCoolantPump2PercentSpeed "HVESS Coolant Pump 2 Percent Speed: Speed of the HVESS Coolant Pump 2 system or component in percentage of maximum speed.  This parameter is used with SPN 23441 (HVESS Coolant Pump 2 Percent Speed Status).";
CM_ BO_ 2566511870 "High Voltage Energy Storage System Thermal Management System Chiller 1";
CM_ SG_ 2566511870 HvssTMtSstC1CpssDsAstPss "HVESS Thermal Management System Chiller 1 Compressor Discharge Absolute Pressure: Absolute Pressure of the refrigerant at exiting the compressor of chiller 1.This parameter is for one of multiple packs in an HVESS.  If there is only one pack in the s...";
CM_ SG_ 2566511870 HvssTMtSstC1CpssStAstPss "HVESS Thermal Management System Chiller 1 Compressor Suction Absolute Pressure: Absolute Pressure of the refrigerant at entering the compressor of chiller 1.This parameter is for one of multiple packs in an HVESS.  If there is only one pack in the sy...";
CM_ SG_ 2566511870 HvssTMtSstC1OttCtTpt "HVESS Thermal Management System Chiller 1 Outlet Coolant Temperature: Temperature of the coolant found at the outlet of chiller 1.This parameter is for one of multiple packs in an HVESS.  If there is only one pack in the system, the HVESS parameters ...";
CM_ SG_ 2566511870 HvssTMtSstC1CVvPst "HVESS Thermal Management System Chiller 1 Cooling Valve Position : Relative position of the cooling bypass valve of chiller 1.This parameter is for one of multiple packs in an HVESS.  If there is only one pack in the system, the HVESS parameters shou...";
CM_ BO_ 2566512126 "High Voltage Energy Storage System Thermal Management System Chiller 2";
CM_ SG_ 2566512126 HvssTMtSstC2CpssDsAstPss "HVESS Thermal Management System Chiller 2 Compressor Discharge Absolute Pressure: Absolute Pressure of the refrigerant at exiting the compressor of chiller 2.This parameter is for one of multiple packs in an HVESS.  If there is only one pack in the s...";
CM_ SG_ 2566512126 HvssTMtSstC2CpssStAstPss "HVESS Thermal Management System Chiller 2 Compressor Suction Absolute Pressure: Absolute Pressure of the refrigerant at entering the compressor of chiller 2.This parameter is for one of multiple packs in an HVESS.  If there is only one pack in the sy...";
CM_ SG_ 2566512126 HvssTMtSstC2OttCtTpt "HVESS Thermal Management System Chiller 2 Outlet Coolant Temperature: Temperature of the coolant found at the outlet of chiller 2.This parameter is for one of multiple packs in an HVESS.  If there is only one pack in the system, the HVESS parameters ...";
CM_ SG_ 2566512126 HvssTMtSstC2CVvPst "HVESS Thermal Management System Chiller 2 Cooling Valve Position: Relative position of the cooling bypass valve of chiller 2.This parameter is for one of multiple packs in an HVESS.  If there is only one pack in the system, the HVESS parameters shoul...";
CM_ BO_ 2566512382 "High Voltage Energy Storage System Thermal Management System Chiller 3";
CM_ SG_ 2566512382 HvssTMtSstC3CpssDsAstPss "HVESS Thermal Management System Chiller 3 Compressor Discharge Absolute Pressure: Absolute Pressure of the refrigerant at exiting the compressor of chiller 3.This parameter is for one of multiple packs in an HVESS.  If there is only one pack in the s...";
CM_ SG_ 2566512382 HvssTMtSstC3CpssStAstPss "HVESS Thermal Management System Chiller 3 Compressor Suction Absolute Pressure: Absolute Pressure of the refrigerant at entering the compressor of chiller 3.This parameter is for one of multiple packs in an HVESS.  If there is only one pack in the sy...";
CM_ SG_ 2566512382 HvssTMtSstC3OttCtTpt "HVESS Thermal Management System Chiller 3 Outlet Coolant Temperature: Temperature of the coolant found at the outlet of chiller 3.This parameter is for one of multiple packs in an HVESS.  If there is only one pack in the system, the HVESS parameters ...";
CM_ SG_ 2566512382 HvssTMtSstC3CVvPst "HVESS Thermal Management System Chiller 3 Cooling Valve Position: Relative position of the cooling bypass valve of chiller 3.This parameter is for one of multiple packs in an HVESS.  If there is only one pack in the system, the HVESS parameters shoul...";
CM_ BO_ 2566512638 "HVESS Coolant Pump 1 Status 1";
CM_ SG_ 2566512638 HvssClntPmp1MtrSpdStts "HVESS Coolant Pump 1 Motor Speed Status: Enable and direction status of the HVESS Coolant Pump 1 system or component. This parameter is used with SPN 23416 (HVESS Coolant Pump 1 Motor Speed).00b = Accessory Motor Off01b = Accessory Motor On - Normal,...";
CM_ SG_ 2566512638 HvssClntPmp1CntrllrSttsRsnCd "HVESS Coolant Pump 1 Controller Status Reason Code: Provides the reason code describing the unique failure of the HVESS Coolant Pump 1 system or component.If a detailed reason code is not used by the supporting application, or this reason code is Not...";
CM_ SG_ 2566512638 HvssClntPmp1CntrllrCmmndStts "HVESS Coolant Pump 1 Controller Command Status: Indicates the source of the speed command to the HVESS Coolant Pump 1 system or component.00b is communicated when the controller is self-controlled (e.g. based on a temperature sensor).01b is communica...";
CM_ SG_ 2566512638 HvessCoolantPump1MotorSpeed "HVESS Coolant Pump 1 Motor Speed: Motor Speed of the HVESS Coolant Pump 1.  This parameter is used with SPN 23413 (HVESS Coolant Pump 1 Motor Speed Status).";
CM_ SG_ 2566512638 HvssClntPmp1CntrlTmprtr "HVESS Coolant Pump 1 Control Temperature: A temperature measured and reported by the device.  It may be used for direct or remote (e.g. by another controller) control of the HVESS Coolant Pump 1.  For example, this may be the temperature of the fluid...";
CM_ SG_ 2566512638 HvessCoolantPump1Power "HVESS Coolant Pump 1 Power: Calculated electrical power consumed by the HVESS Coolant Pump 1.";
CM_ SG_ 2566512638 HvssClntPmp1SrvIndtr "HVESS Coolant Pump 1 Service Indicator: Indicates that service is required for the HVESS Coolant Pump 1 system or component.  An active indication may convey a need for component replacement or periodic service.  The SPN 23414 (HVESS Coolant Pump 1 C...";
CM_ SG_ 2566512638 HvssClntPmp1OprtngStts "HVESS Coolant Pump 1 Operating Status: Indicates the operating status of the HVESS Coolant Pump 1 system or component.  This parameter is used to inform other devices that this system or component is no longer performing to its operational capacity a...";
CM_ BO_ 2566512894 "HVESS Coolant Pump 1 Command";
CM_ SG_ 2566512894 HvessCoolantPump1EnableCommand "HVESS Coolant Pump 1 Enable Command: Enable and direction command to the HVESS Coolant Pump 1.00b = Accessory Motor Off01b = Accessory Motor On Normal/Default Direction10b = Accessory Motor On Reverse Direction11b = Don't Care/Take no action";
CM_ SG_ 2566512894 HvessCoolantPump1PowerHold "HVESS Coolant Pump 1 Power Hold: Command to allow the HVESS Coolant Pump 1 to remain alive independently of the electrical enable input to the Accessory Motor.  For example, this could allow continued device operation after the keyswitch has turned o...";
CM_ SG_ 2566512894 HvessCoolantPump1SpeedCommand "HVESS Coolant Pump 1 Speed Command: Speed command to the HVESS Coolant Pump 1.Note: Both Speed Command and Percent Speed Command cannot be used at the same time.  Always set the unused speed command to Not Available.  If both commands are set to Not ...";
CM_ SG_ 2566512894 HvssClntPmp1PrntSpdCmmnd "HVESS Coolant Pump 1 Percent Speed Command: Speed command to the HVESS Coolant Pump 1 in percentage of maximum speed.Note: Both Speed Command and Percent Speed Command cannot be used at the same time.  Always set the unused speed command to Not Avail...";
CM_ SG_ 2566512894 HvssCtPp1CdEdddIttSppt "HVESS Coolant Pump 1 Command Embedded Integrity Support: Indicates that SPN 23561 (HVESS Coolant Pump 1 Command CRC) and SPN 23560 (HVESS Coolant Pump 1 Command Counter) are supported by the sender.00b = HVESS Coolant Pump 1 Command embedded CRC and ...";
CM_ SG_ 2566512894 HvessCoolantPump1CommandCounter "HVESS Coolant Pump 1 Command Counter: The message counter is used to detect situations where the transmitting ECU malfunction repeats the same frame all the time. The receiver of the information may use the counter parameter to detect this situation....";
CM_ SG_ 2566512894 HvessCoolantPump1CommandCrc "HVESS Coolant Pump 1 Command CRC: The CRC is defined as follows:  - Length: 8 bits  - Polynomial: x^8+x^5+x^3+x^2+x+1  - Initial Value: FFh  - Input Data Reflection: Not reflected  - Result Data Reflection: Not reflected  - XOR value: FFhSAE makes no...";
CM_ BO_ 2566513150 "HVESS Coolant Pump 2 Status 1";
CM_ SG_ 2566513150 HvssClntPmp2MtrSpdStts "HVESS Coolant Pump 2 Motor Speed Status: Enable and direction status of the HVESS Coolant Pump 2 system or component. This parameter is used with SPN 23433 (HVESS Coolant Pump 2 Motor Speed).00b = Accessory Motor Off01b = Accessory Motor On - Normal,...";
CM_ SG_ 2566513150 HvssClntPmp2CntrllrSttsRsnCd "HVESS Coolant Pump 2 Controller Status Reason Code: Provides the reason code describing the unique failure of the HVESS Coolant Pump 2 system or component.If a detailed reason code is not used by the supporting application, or this reason code is Not...";
CM_ SG_ 2566513150 HvssClntPmp2CntrllrCmmndStts "HVESS Coolant Pump 2 Controller Command Status: Indicates the source of the speed command to the HVESS Coolant Pump 2 system or component.00b is communicated when the controller is self-controlled (e.g. based on a temperature sensor).01b is communica...";
CM_ SG_ 2566513150 HvessCoolantPump2MotorSpeed "HVESS Coolant Pump 2 Motor Speed: Motor Speed of the HVESS Coolant Pump 2.  This parameter is used with SPN 23430 (HVESS Coolant Pump 2 Motor Speed Status).";
CM_ SG_ 2566513150 HvssClntPmp2CntrlTmprtr "HVESS Coolant Pump 2 Control Temperature: A temperature measured and reported by the device.  It may be used for direct or remote (e.g. by another controller) control of the HVESS Coolant Pump 2.  For example, this may be the temperature of the fluid...";
CM_ SG_ 2566513150 HvessCoolantPump2Power "HVESS Coolant Pump 2 Power: Calculated electrical power consumed by the HVESS Coolant Pump 2.";
CM_ SG_ 2566513150 HvssClntPmp2SrvIndtr "HVESS Coolant Pump 2 Service Indicator: Indicates that service is required for the HVESS Coolant Pump 2 system or component.  An active indication may convey a need for component replacement or periodic service.  The SPN 23431 (HVESS Coolant Pump 2 C...";
CM_ SG_ 2566513150 HvssClntPmp2OprtngStts "HVESS Coolant Pump 2 Operating Status: Indicates the operating status of the HVESS Coolant Pump 2 system or component.  This parameter is used to inform other devices that this system or component is no longer performing to its operational capacity a...";
CM_ BO_ 2566513406 "HVESS Coolant Pump 2 Command";
CM_ SG_ 2566513406 HvessCoolantPump2EnableCommand "HVESS Coolant Pump 2 Enable Command: Enable and direction command to the HVESS Coolant Pump 2.00b = Accessory Motor Off01b = Accessory Motor On Normal/Default Direction10b = Accessory Motor On Reverse Direction11b = Don't Care/Take no action";
CM_ SG_ 2566513406 HvessCoolantPump2PowerHold "HVESS Coolant Pump 2 Power Hold: Command to allow the HVESS Coolant Pump 2 to remain alive independently of the electrical enable input to the Accessory Motor.  For example, this could allow continued device operation after the keyswitch has turned o...";
CM_ SG_ 2566513406 HvessCoolantPump2SpeedCommand "HVESS Coolant Pump 2 Speed Command: Speed command to the HVESS Coolant Pump 2.Note: Both Speed Command and Percent Speed Command cannot be used at the same time.  Always set the unused speed command to Not Available.  If both commands are set to Not ...";
CM_ SG_ 2566513406 HvssClntPmp2PrntSpdCmmnd "HVESS Coolant Pump 2 Percent Speed Command: Speed command to the HVESS Coolant Pump 2 in percentage of maximum speed.Note: Both Speed Command and Percent Speed Command cannot be used at the same time.  Always set the unused speed command to Not Avail...";
CM_ SG_ 2566513406 HvssCtPp2CdEdddIttSppt "HVESS Coolant Pump 2 Command Embedded Integrity Support: Indicates that SPN 23564 (HVESS Coolant Pump 2 Command CRC) and SPN 23563 (HVESS Coolant Pump 2 Command Counter) are supported by the sender.00b = HVESS Coolant Pump 2 Command embedded CRC and ...";
CM_ SG_ 2566513406 HvessCoolantPump2CommandCounter "HVESS Coolant Pump 2 Command Counter: The message counter is used to detect situations where the transmitting ECU malfunction repeats the same frame all the time. The receiver of the information may use the counter parameter to detect this situation....";
CM_ SG_ 2566513406 HvessCoolantPump2CommandCrc "HVESS Coolant Pump 2 Command CRC: The CRC is defined as follows:  - Length: 8 bits  - Polynomial: x^8+x^5+x^3+x^2+x+1  - Initial Value: FFh  - Input Data Reflection: Not reflected  - Result Data Reflection: Not reflected  - XOR value: FFhSAE makes no...";
CM_ BO_ 2365187070 "Hydrogen Sensor Information";
CM_ SG_ 2365187070 HydrogenInformationCrc "Hydrogen Information CRC: The CRC is defined as follows: - Length: 8 bits- Polynomial: x^8+x^5+x^3+x^2+x+1- Initial Value: FFh- Input Data Reflection: Not reflected- Result Data Reflection: Not reflected- XOR value: FFh SAE makes no claim of the func...";
CM_ SG_ 2365187070 HydrogenInformationCounter "Hydrogen Information Counter: The message counter is used to detect situations where the transmitting ECU malfunction repeats the same frame all the time. The receiver of the information may use the counter parameter to detect this situation. The tra...";
CM_ SG_ 2365187070 HydrogenConcentration "Hydrogen Concentration: This parameter indicates the hydrogen concentration measured by the sensor.Parameter Specific Indicator:  A value of FBh indicates conditions are not acceptable for a valid measurement.";
CM_ SG_ 2365187070 HdrgnCnntrtnPrlmnrFm "Hydrogen Concentration Preliminary FMI: Used to identify the applicable J1939-73 FMI detected in the hydrogen sensor by the manufacturers software. When there is multiple failures, the most severe is transmitted.A value of 31 is sent to indicate that...";
CM_ BO_ 2566514174 "Operator Inducement Vehicle Speed Information 1";
CM_ SG_ 2566514174 OprtrIndmntVhlSpdDrt "Operator Inducement Vehicle Speed Derate: This is the active vehicle speed derate that is currently applied to the engine operation due to operator inducement.  When this form of operator inducement is not active, this parameter will be set to FBh. F...";
CM_ SG_ 2566514174 OprtrIndmntNxtVhlSpdDrt "Operator Inducement Next Vehicle Speed Derate: This is the vehicle speed derate that will be applied to the engine operation due to operator inducement when the value in SPN 23382 (Operator Inducement Time to Next Vehicle Speed Derate) has decremente...";
CM_ SG_ 2566514174 OprtrIndmntTmTNxtVhlSpdDrt "Operator Inducement Time to Next Vehicle Speed Derate: This parameter provides the duration until SPN 23381 (Operator Inducement Next Vehicle Speed Derate) becomes the active vehicle speed derate and will be reflected in SPN 23380 (Operator Inducemen...";
CM_ BO_ 2566514942 "Engine Protection Torque Derate Information";
CM_ SG_ 2566514942 EngineProtectionTorqueReduction "Engine Protection Torque Reduction: This parameter is a percentage of how much the engine's capabilities are reduced below the Advertised Engine Torque Curve. 0% represents no torque reduction and 100% represents a full torque reduction.  For example...";
CM_ BO_ 2566515198 "Aftertreatment System Information 7";
CM_ SG_ 2566515198 AttttDsExstFdCtCsptRt "Aftertreatment Diesel Exhaust Fluid Current Consumption Rate: Current rate of DEF consumption since last reset via SPN 23394 (Aftertreatment Diesel Exhaust Fluid Consumption Rate Reset).Note: This will display current DEF consumption rate for the ent...";
CM_ SG_ 2566515198 AttttDsExstFdPvsCsptRt "Aftertreatment Diesel Exhaust Fluid Previous Consumption Rate: Contains the Aftertreatment Diesel Exhaust Fluid consumption rate value when SPN 23392 (Aftertreatment Diesel Exhaust Fluid Current Consumption Rate) was reset via SPN 23394 (Aftertreatme...";
CM_ BO_ 2633624318 "SAE J2012 3-Byte DTC Display";
CM_ SG_ 2633624318 NumberOfJ20123ByteDtcs "Number of J2012 3-Byte DTCs: The number of J2012 3-byte DTCs being conveyed in PGN 63978 (SAE J2012 3-Byte DTC Display).  If the value of this parameter is zero, the device broadcasting PGN 63978 (SAE J2012 3-Byte DTC Display) has no J2012 3-byte DTC...";
CM_ SG_ 2633624318 J20123ByteDtcOccurrenceCount "J2012 3-byte DTC Occurrence Count: Number of occurrences of the respective SAE J2012 3-byte DTC being conveyed.If more than 126 occurrences happen the value shall be set to 126.If the occurrence count is not available to be sent then this value shall...";
CM_ SG_ 2633624318 J20123ByteDtcStatus "J2012 3-byte DTC Status: Indicates if the respective SAE J2012 3-byte DTC is active or previously active.0b = DTC is previously active1b = DTC is active";
CM_ SG_ 2633624318 J20123ByteDtcBaseCode "J2012 3-byte DTC Base Code: Five character ASCII representation of the SAE J2012 3-byte DTC Base Code (e.g. P2793).  Sent most significant byte first.";
CM_ SG_ 2633624318 J20123ByteDtcDelimiter "J2012 3-byte DTC Delimiter: One character ASCII delimiter to seperate the J2012 Base Code and FTB.  Set this parameter to ASCII 45 (-). ";
CM_ SG_ 2633624318 J20123ByteDtcFailureType "J2012 3-byte DTC Failure Type: Two character ASCII representation of the SAE J2012 3-byte DTC Failure Type Byte (FTB).  The first character conveys the J2012 DTC Failure Category and the second character conveys the J2012 DTC Failure Sub Type.  If an...";
BA_DEF_ SG_  "SPN" INT 0 524287;
BA_DEF_ BO_  "VFrameFormat" ENUM  "StandardCAN","ExtendedCAN","reserved","J1939PG";
BA_DEF_DEF_  "SPN" 0;
BA_DEF_DEF_  "VFrameFormat" "J1939PG";
BA_ "SPN" SG_ 2566529790 EngnCrnksPrssrSnsrMdlSpplVltg 22634;
BA_ "SPN" SG_ 2566529790 EngnFlDlvrPrssrSnsrMdlSpplVltg 22635;
BA_ "SPN" SG_ 2566529790 EExstGsRtItPssSsMdSppVt 22636;
BA_ "SPN" SG_ 2566529790 EngnFltrdFlSnsrMdlSpplVltg 22637;
BA_ "SPN" SG_ 2566529790 EngnOlSnsrMdlSpplVltg 22638;
BA_ "SPN" SG_ 2566529790 DsPttFtPssSsMdSppVt 22639;
BA_ "SPN" SG_ 2566529790 EngnIntkArSnsrMdlSpplVltg 22640;
BA_ "SPN" SG_ 2365207550 MltClrIndtrLmpSqnCntr 22318;
BA_ "SPN" SG_ 2365207550 MltClrIndtrLmpTmSlt1 22320;
BA_ "SPN" SG_ 2365207550 MltClrIndtrLmpTmSlt2 22319;
BA_ "SPN" SG_ 2365207550 MltClrIndtrLmpTmSlt3 22322;
BA_ "SPN" SG_ 2365207550 MltClrIndtrLmpTmSlt4 22321;
BA_ "SPN" SG_ 2365207550 MltClrIndtrLmpTmSlt5 22324;
BA_ "SPN" SG_ 2365207550 MltClrIndtrLmpTmSlt6 22323;
BA_ "SPN" SG_ 2365207550 MltClrIndtrLmpTmSlt7 22326;
BA_ "SPN" SG_ 2365207550 MltClrIndtrLmpTmSlt8 22325;
BA_ "SPN" SG_ 2365207550 MltClrIndtrLmpTmSlt9 22328;
BA_ "SPN" SG_ 2365207550 MltClrIndtrLmpTmSlt10 22327;
BA_ "SPN" SG_ 2365207550 MltClrIndtrLmpBrghtnss 22329;
BA_ "SPN" SG_ 2365207550 MltClrIndtrLmpSnhrnztn 22330;
BA_ "SPN" SG_ 2365207550 MltClrIndtrLmpFrqn 22331;
BA_ "SPN" SG_ 2365207806 MltClrIndtrLmpFdkSqnCntr 22332;
BA_ "SPN" SG_ 2365207806 MltClrIndtrLmpClr1Stts 22333;
BA_ "SPN" SG_ 2365207806 MltClrIndtrLmpClr2Stts 22334;
BA_ "SPN" SG_ 2365207806 MltClrIndtrLmpClr3Stts 22335;
BA_ "SPN" SG_ 2365207806 MltClrIndtrLmpClr4Stts 22336;
BA_ "SPN" SG_ 2365207806 MltClrIndtrLmpClr5Stts 22337;
BA_ "SPN" SG_ 2365207806 MltClrIndtrLmpClr6Stts 22338;
BA_ "SPN" SG_ 2365207806 MltClrIndtrLmpClr7Stts 22339;
BA_ "SPN" SG_ 2365207806 MltClrIndtrLmpClr8Stts 22340;
BA_ "SPN" SG_ 2365207806 MltClrIndtrLmpClr9Stts 22341;
BA_ "SPN" SG_ 2365207806 MltClrIndtrLmpClr10Stts 22342;
BA_ "SPN" SG_ 2365207806 MltClrIndtrLmpClr11Stts 22343;
BA_ "SPN" SG_ 2365207806 MltClrIndtrLmpClr12Stts 22344;
BA_ "SPN" SG_ 2365207806 MltClrIndtrLmpClr13Stts 22345;
BA_ "SPN" SG_ 2365207806 MltClrIndtrLmpClr14Stts 22346;
BA_ "SPN" SG_ 2365207806 MltClrIndtrLmpGnrlFlt 22347;
BA_ "SPN" SG_ 2566648574 EngnFlFltrDffrntlPrssrHghRsltn 22744;
BA_ "SPN" SG_ 2566648574 EFFtStSdDtPssHRst 22745;
BA_ "SPN" SG_ 2633761022 BrkWrLfRmnngTrlrAxl1LftWhl 22754;
BA_ "SPN" SG_ 2633761022 BrkWrLfRmnngTrlrAxl1RghtWhl 22755;
BA_ "SPN" SG_ 2633761022 BrkWrLfRmnngTrlrAxl2LftWhl 22756;
BA_ "SPN" SG_ 2633761022 BrkWrLfRmnngTrlrAxl2RghtWhl 22757;
BA_ "SPN" SG_ 2633761022 BrkWrLfRmnngTrlrAxl3LftWhl 22758;
BA_ "SPN" SG_ 2633761022 BrkWrLfRmnngTrlrAxl3RghtWhl 22759;
BA_ "SPN" SG_ 2633761022 BrkWrLfRmnngTrlrAxl4LftWhl 22760;
BA_ "SPN" SG_ 2633761022 BrkWrLfRmnngTrlrAxl4RghtWhl 22761;
BA_ "SPN" SG_ 2633761022 BrkWrLfRmnngTrlrAxl5LftWhl 22762;
BA_ "SPN" SG_ 2633761022 BrkWrLfRmnngTrlrAxl5RghtWhl 22763;
BA_ "SPN" SG_ 2633761022 BrkWrLfRmnngTrlrAxl6LftWhl 22764;
BA_ "SPN" SG_ 2633761022 BrkWrLfRmnngTrlrAxl6RghtWhl 22765;
BA_ "SPN" SG_ 2633761022 BrkWrLfRmnngTrlrAxl7LftWhl 22766;
BA_ "SPN" SG_ 2633761022 BrkWrLfRmnngTrlrAxl7RghtWhl 22767;
BA_ "SPN" SG_ 2633761022 BrkWrLfRmnngTrlrAxl8LftWhl 22768;
BA_ "SPN" SG_ 2633761022 BrkWrLfRmnngTrlrAxl8RghtWhl 22769;
BA_ "SPN" SG_ 2566659838 SlBttrPk1Bttr1ChrgCrrntLmt 22746;
BA_ "SPN" SG_ 2566659838 SlBttrPk1Bttr2ChrgCrrntLmt 22747;
BA_ "SPN" SG_ 2566659838 SlBttrPk1Bttr3ChrgCrrntLmt 22748;
BA_ "SPN" SG_ 2566659838 SlBttrPk1Bttr4ChrgCrrntLmt 22749;
BA_ "SPN" SG_ 2566660094 SlBttrPk1Bttr1DshrgCrrntLmt 22750;
BA_ "SPN" SG_ 2566660094 SlBttrPk1Bttr2DshrgCrrntLmt 22751;
BA_ "SPN" SG_ 2566660094 SlBttrPk1Bttr3DshrgCrrntLmt 22752;
BA_ "SPN" SG_ 2566660094 SlBttrPk1Bttr4DshrgCrrntLmt 22753;
BA_ "SPN" SG_ 2565904382 MtrGnrtr1InvrtrThrmlCpltUsd 22945;
BA_ "SPN" SG_ 2565904382 MtrGnrtr1InvrtrThrmlCpltLmt 22946;
BA_ "SPN" SG_ 2565904638 MtrGnrtr2InvrtrThrmlCpltUsd 22949;
BA_ "SPN" SG_ 2565904638 MtrGnrtr2InvrtrThrmlCpltLmt 22950;
BA_ "SPN" SG_ 2565904894 MtrGnrtr3InvrtrThrmlCpltUsd 22953;
BA_ "SPN" SG_ 2565904894 MtrGnrtr3InvrtrThrmlCpltLmt 22954;
BA_ "SPN" SG_ 2565905150 MtrGnrtr4InvrtrThrmlCpltUsd 22957;
BA_ "SPN" SG_ 2565905150 MtrGnrtr4InvrtrThrmlCpltLmt 22958;
BA_ "SPN" SG_ 2565905406 MtrGnrtr5InvrtrThrmlCpltUsd 22961;
BA_ "SPN" SG_ 2565905406 MtrGnrtr5InvrtrThrmlCpltLmt 22962;
BA_ "SPN" SG_ 2565905662 MtrGnrtr6InvrtrThrmlCpltUsd 22965;
BA_ "SPN" SG_ 2565905662 MtrGnrtr6InvrtrThrmlCpltLmt 22966;
BA_ "SPN" SG_ 2565918462 EngnTrhrgrWstgtAttr3Cmmnd 22967;
BA_ "SPN" SG_ 2565918462 EngnTrhrgrWstgtAttr4Cmmnd 22968;
BA_ "SPN" SG_ 2565918718 EngnTrhrgrWstgtAttr3OprtnStts 22969;
BA_ "SPN" SG_ 2565918718 EngnTrhrgrWstgtAttr4OprtnStts 22970;
BA_ "SPN" SG_ 2566523646 MtrGnrtr1ThrmlCpltUsd 22943;
BA_ "SPN" SG_ 2566523646 MtrGnrtr1ThrmlCpltLmt 22944;
BA_ "SPN" SG_ 2566523902 MtrGnrtr2ThrmlCpltUsd 22947;
BA_ "SPN" SG_ 2566523902 MtrGnrtr2ThrmlCpltLmt 22948;
BA_ "SPN" SG_ 2566524158 MtrGnrtr3ThrmlCpltUsd 22951;
BA_ "SPN" SG_ 2566524158 MtrGnrtr3ThrmlCpltLmt 22952;
BA_ "SPN" SG_ 2566524414 MtrGnrtr4ThrmlCpltUsd 22955;
BA_ "SPN" SG_ 2566524414 MtrGnrtr4ThrmlCpltLmt 22956;
BA_ "SPN" SG_ 2566524670 MtrGnrtr5ThrmlCpltUsd 22959;
BA_ "SPN" SG_ 2566524670 MtrGnrtr5ThrmlCpltLmt 22960;
BA_ "SPN" SG_ 2566524926 MtrGnrtr6ThrmlCpltUsd 22963;
BA_ "SPN" SG_ 2566524926 MtrGnrtr6ThrmlCpltLmt 22964;
BA_ "SPN" SG_ 2566525182 ObpEventSeconds 22935;
BA_ "SPN" SG_ 2566525182 ObpEventMinutes 22936;
BA_ "SPN" SG_ 2566525182 ObpEventHours 22937;
BA_ "SPN" SG_ 2566525182 ObpEventMonth 22938;
BA_ "SPN" SG_ 2566525182 ObpEventDay 22939;
BA_ "SPN" SG_ 2566525182 ObpEventYear 22940;
BA_ "SPN" SG_ 2566525182 ObpEventLocalMinuteOffset 22941;
BA_ "SPN" SG_ 2566525182 ObpEventLocalHourOffset 22942;
BA_ "SPN" SG_ 2566525438 Atttt1TtLtOSDsExstFdUsd 22268;
BA_ "SPN" SG_ 2566525438 Atttt1TpLtOSDsExstFd 22269;
BA_ "SPN" SG_ 2566525950 CtCCtstHtEUtFtpCdSttTT 22227;
BA_ "SPN" SG_ 2566525950 CtCCtstHtEUtFtpEOtptE 22228;
BA_ "SPN" SG_ 2566525950 CtCCtstHtEUtCtstCdSttTTptTsd 22229;
BA_ "SPN" SG_ 2566525950 CtCEOtptEUtFtpCdSttTT 22230;
BA_ "SPN" SG_ 2566525950 CtCEOtptEUtCtstCdSttTTptTsd 22231;
BA_ "SPN" SG_ 2566525950 CtCEMssUtFtpCdSttTT 22232;
BA_ "SPN" SG_ 2566525950 CtCEMssUtFtpEOtptE 22233;
BA_ "SPN" SG_ 2566525950 CtCEMssUtCdSttTCtstTptTsd 22234;
BA_ "SPN" SG_ 2566525950 CrrntClTmUntlFtpEngnOtptEnrg 22235;
BA_ "SPN" SG_ 2566525950 CtCTUtCtstCdSttTTptTsd 22236;
BA_ "SPN" SG_ 2566526206 AvCtstHtEUtFtpCdSttTT 22237;
BA_ "SPN" SG_ 2566526206 AvCtstHtEUtFtpEOtptE 22238;
BA_ "SPN" SG_ 2566526206 AvCtstHtEUtCtstCdSttTTptTsd 22239;
BA_ "SPN" SG_ 2566526206 AvEOtptEUtFtpCdSttTT 22240;
BA_ "SPN" SG_ 2566526206 AvEOtptEUtCdSttTCtstTptTsd 22241;
BA_ "SPN" SG_ 2566526206 AvrgEgrMssAtFtpCldStrtTrkngTm 22242;
BA_ "SPN" SG_ 2566526206 AvrgEgrMssAtFtpEngnOtptEnrg 22243;
BA_ "SPN" SG_ 2566526206 AvEMssUtFtpCdSttTCtstTpt 22244;
BA_ "SPN" SG_ 2566526206 AvrgTmUntlFtpEngnOtptEnrg 22245;
BA_ "SPN" SG_ 2566526206 AvTUtCtstCdSttTTpt 22246;
BA_ "SPN" SG_ 2365200126 HvssHghVltgIntrnlVltgLvl1 22915;
BA_ "SPN" SG_ 2365200126 HvssHghVltgIntrnlCrrnt1 22916;
BA_ "SPN" SG_ 2365200126 HvssHghVltgIntrnlVltgLvl2 22917;
BA_ "SPN" SG_ 2365200126 HvssHghVltgIntrnlCrrnt2 22918;
BA_ "SPN" SG_ 2365200382 HvssHghVltgIntrnlVltgLvl3 22919;
BA_ "SPN" SG_ 2365200382 HvssHghVltgIntrnlCrrnt3 22920;
BA_ "SPN" SG_ 2365200382 HvssHghVltgIntrnlVltgLvl4 22921;
BA_ "SPN" SG_ 2365200382 HvssHghVltgIntrnlCrrnt4 22922;
BA_ "SPN" SG_ 2365200638 HvssHghVltgIntrnlVltgLvl5 22923;
BA_ "SPN" SG_ 2365200638 HvssHghVltgIntrnlCrrnt5 22924;
BA_ "SPN" SG_ 2365200638 HvssHghVltgIntrnlVltgLvl6 22925;
BA_ "SPN" SG_ 2365200638 HvssHghVltgIntrnlCrrnt6 22926;
BA_ "SPN" SG_ 2365200894 HvssHghVltgIntrnlVltgLvl7 22927;
BA_ "SPN" SG_ 2365200894 HvssHghVltgIntrnlCrrnt7 22928;
BA_ "SPN" SG_ 2365200894 HvssHghVltgIntrnlVltgLvl8 22929;
BA_ "SPN" SG_ 2365200894 HvssHghVltgIntrnlCrrnt8 22930;
BA_ "SPN" SG_ 2432310014 EngnCrnksPrssrCntrlAttr1Cmmnd 22789;
BA_ "SPN" SG_ 2432310014 EngnCrnksPrssrCntrlAttr2Cmmnd 22790;
BA_ "SPN" SG_ 2432310270 EngnCrnksPrssrCntrlAttr1Tmprtr 22791;
BA_ "SPN" SG_ 2432310270 EngnCrnksPrssrCntrlAttr1Pstn 22792;
BA_ "SPN" SG_ 2432310270 ECsPssCtAtt1DsdPst 22793;
BA_ "SPN" SG_ 2432310270 ECsPssCtAtt1PF 22794;
BA_ "SPN" SG_ 2432310270 ECsPssCtAtt1TptStts 22795;
BA_ "SPN" SG_ 2432310270 ECsPssCtAtt1OptStts 22796;
BA_ "SPN" SG_ 2432310526 EngnCrnksPrssrCntrlAttr2Tmprtr 22798;
BA_ "SPN" SG_ 2432310526 EngnCrnksPrssrCntrlAttr2Pstn 22799;
BA_ "SPN" SG_ 2432310526 ECsPssCtAtt2DsdPst 22800;
BA_ "SPN" SG_ 2432310526 ECsPssCtAtt2PF 22801;
BA_ "SPN" SG_ 2432310526 ECsPssCtAtt2TptStts 22802;
BA_ "SPN" SG_ 2432310526 ECsPssCtAtt2OptStts 22803;
BA_ "SPN" SG_ 2365201918 HghVltgBsIntrf1CnntCmmnd 22775;
BA_ "SPN" SG_ 2365201918 HghVltgBsIntrf2CnntCmmnd 22776;
BA_ "SPN" SG_ 2365201918 HghVltgBsIntrf3CnntCmmnd 22777;
BA_ "SPN" SG_ 2365201918 HghVltgBsIntrf4CnntCmmnd 22778;
BA_ "SPN" SG_ 2365201918 HghVltgBsIntrf5CnntCmmnd 22779;
BA_ "SPN" SG_ 2365201918 HghVltgBsIntrf6CnntCmmnd 22780;
BA_ "SPN" SG_ 2365201918 HghVltgBsIntrf7CnntCmmnd 22781;
BA_ "SPN" SG_ 2365201918 HghVltgBsIntrf8CnntCmmnd 22782;
BA_ "SPN" SG_ 2365201918 HghVltgBsIntrf9CnntCmmnd 23612;
BA_ "SPN" SG_ 2365201918 HghVltgBsIntrf10CnntCmmnd 23613;
BA_ "SPN" SG_ 2365201918 HghVltgBsIntrf11CnntCmmnd 23614;
BA_ "SPN" SG_ 2365201918 HghVltgBsIntrf12CnntCmmnd 23615;
BA_ "SPN" SG_ 2365201918 HghVltgBsIntrf13CnntCmmnd 23616;
BA_ "SPN" SG_ 2365201918 HghVltgBsIntrf14CnntCmmnd 23617;
BA_ "SPN" SG_ 2365201918 HghVltgBsIntrf15CnntCmmnd 23618;
BA_ "SPN" SG_ 2365201918 HghVltgBsIntrf16CnntCmmnd 23619;
BA_ "SPN" SG_ 2365201918 HghVltgBsIntrf17CnntCmmnd 23620;
BA_ "SPN" SG_ 2365201918 HghVltgBsIntrf18CnntCmmnd 23621;
BA_ "SPN" SG_ 2365201918 HghVltgBsIntrf19CnntCmmnd 23622;
BA_ "SPN" SG_ 2365201918 HghVltgBsIntrf20CnntCmmnd 23623;
BA_ "SPN" SG_ 2365201918 HghVltgBsIntrf21CnntCmmnd 23624;
BA_ "SPN" SG_ 2365201918 HghVltgBsIntrf22CnntCmmnd 23625;
BA_ "SPN" SG_ 2365201918 HghVltgBsIntrf23CnntCmmnd 23626;
BA_ "SPN" SG_ 2365201918 HghVltgBsIntrf24CnntCmmnd 23627;
BA_ "SPN" SG_ 2365201918 Hvbcc1EmbeddedIntegritySupport 22783;
BA_ "SPN" SG_ 2365201918 Hvbcc1Counter 22784;
BA_ "SPN" SG_ 2365201918 Hvbcc1Crc 22785;
BA_ "SPN" SG_ 2365202174 HghVltgBsIntrf1PstvCnttrStt 21531;
BA_ "SPN" SG_ 2365202174 HghVltgBsIntrf1NgtvCnttrStt 21532;
BA_ "SPN" SG_ 2365202174 HghVltgBsIntrf2PstvCnttrStt 21538;
BA_ "SPN" SG_ 2365202174 HghVltgBsIntrf2NgtvCnttrStt 21539;
BA_ "SPN" SG_ 2365202174 HghVltgBsIntrf3PstvCnttrStt 21545;
BA_ "SPN" SG_ 2365202174 HghVltgBsIntrf3NgtvCnttrStt 21546;
BA_ "SPN" SG_ 2365202174 HghVltgBsIntrf4PstvCnttrStt 21552;
BA_ "SPN" SG_ 2365202174 HghVltgBsIntrf4NgtvCnttrStt 21553;
BA_ "SPN" SG_ 2365202174 HghVltgBsIntrf5PstvCnttrStt 21559;
BA_ "SPN" SG_ 2365202174 HghVltgBsIntrf5NgtvCnttrStt 21560;
BA_ "SPN" SG_ 2365202174 HghVltgBsIntrf6PstvCnttrStt 21566;
BA_ "SPN" SG_ 2365202174 HghVltgBsIntrf6NgtvCnttrStt 21567;
BA_ "SPN" SG_ 2365202174 HghVltgBsIntrf7PstvCnttrStt 21573;
BA_ "SPN" SG_ 2365202174 HghVltgBsIntrf7NgtvCnttrStt 21574;
BA_ "SPN" SG_ 2365202174 HghVltgBsIntrf8PstvCnttrStt 21580;
BA_ "SPN" SG_ 2365202174 HghVltgBsIntrf8NgtvCnttrStt 21581;
BA_ "SPN" SG_ 2365202174 Hvbcs1EmbeddedIntegritySupport 22786;
BA_ "SPN" SG_ 2365202174 Hvbcs1Counter 22787;
BA_ "SPN" SG_ 2365202174 Hvbcs1Crc 22788;
BA_ "SPN" SG_ 2365333758 HvessModule33OperationalStatus 22851;
BA_ "SPN" SG_ 2365333758 HvessModule34OperationalStatus 22852;
BA_ "SPN" SG_ 2365333758 HvessModule35OperationalStatus 22853;
BA_ "SPN" SG_ 2365333758 HvessModule36OperationalStatus 22854;
BA_ "SPN" SG_ 2365333758 HvessModule37OperationalStatus 22855;
BA_ "SPN" SG_ 2365333758 HvessModule38OperationalStatus 22856;
BA_ "SPN" SG_ 2365333758 HvessModule39OperationalStatus 22857;
BA_ "SPN" SG_ 2365333758 HvessModule40OperationalStatus 22858;
BA_ "SPN" SG_ 2365333758 HvessModule41OperationalStatus 22859;
BA_ "SPN" SG_ 2365333758 HvessModule42OperationalStatus 22860;
BA_ "SPN" SG_ 2365333758 HvessModule43OperationalStatus 22861;
BA_ "SPN" SG_ 2365333758 HvessModule44OperationalStatus 22862;
BA_ "SPN" SG_ 2365333758 HvessModule45OperationalStatus 22863;
BA_ "SPN" SG_ 2365333758 HvessModule46OperationalStatus 22864;
BA_ "SPN" SG_ 2365333758 HvessModule47OperationalStatus 22865;
BA_ "SPN" SG_ 2365333758 HvessModule48OperationalStatus 22866;
BA_ "SPN" SG_ 2365333758 HvessModule49OperationalStatus 22867;
BA_ "SPN" SG_ 2365333758 HvessModule50OperationalStatus 22868;
BA_ "SPN" SG_ 2365333758 HvessModule51OperationalStatus 22869;
BA_ "SPN" SG_ 2365333758 HvessModule52OperationalStatus 22870;
BA_ "SPN" SG_ 2365333758 HvessModule53OperationalStatus 22871;
BA_ "SPN" SG_ 2365333758 HvessModule54OperationalStatus 22872;
BA_ "SPN" SG_ 2365333758 HvessModule55OperationalStatus 22873;
BA_ "SPN" SG_ 2365333758 HvessModule56OperationalStatus 22874;
BA_ "SPN" SG_ 2365333758 HvessModule57OperationalStatus 22875;
BA_ "SPN" SG_ 2365333758 HvessModule58OperationalStatus 22876;
BA_ "SPN" SG_ 2365333758 HvessModule59OperationalStatus 22877;
BA_ "SPN" SG_ 2365333758 HvessModule60OperationalStatus 22878;
BA_ "SPN" SG_ 2365333758 HvessModule61OperationalStatus 22879;
BA_ "SPN" SG_ 2365333758 HvessModule62OperationalStatus 22880;
BA_ "SPN" SG_ 2365333758 HvessModule63OperationalStatus 22881;
BA_ "SPN" SG_ 2365333758 HvessModule64OperationalStatus 22882;
BA_ "SPN" SG_ 2365334014 HvessModule65OperationalStatus 22883;
BA_ "SPN" SG_ 2365334014 HvessModule66OperationalStatus 22884;
BA_ "SPN" SG_ 2365334014 HvessModule67OperationalStatus 22885;
BA_ "SPN" SG_ 2365334014 HvessModule68OperationalStatus 22886;
BA_ "SPN" SG_ 2365334014 HvessModule69OperationalStatus 22887;
BA_ "SPN" SG_ 2365334014 HvessModule70OperationalStatus 22888;
BA_ "SPN" SG_ 2365334014 HvessModule71OperationalStatus 22889;
BA_ "SPN" SG_ 2365334014 HvessModule72OperationalStatus 22890;
BA_ "SPN" SG_ 2365334014 HvessModule73OperationalStatus 22891;
BA_ "SPN" SG_ 2365334014 HvessModule74OperationalStatus 22892;
BA_ "SPN" SG_ 2365334014 HvessModule75OperationalStatus 22893;
BA_ "SPN" SG_ 2365334014 HvessModule76OperationalStatus 22894;
BA_ "SPN" SG_ 2365334014 HvessModule77OperationalStatus 22895;
BA_ "SPN" SG_ 2365334014 HvessModule78OperationalStatus 22896;
BA_ "SPN" SG_ 2365334014 HvessModule79OperationalStatus 22897;
BA_ "SPN" SG_ 2365334014 HvessModule80OperationalStatus 22898;
BA_ "SPN" SG_ 2365334014 HvessModule81OperationalStatus 22899;
BA_ "SPN" SG_ 2365334014 HvessModule82OperationalStatus 22900;
BA_ "SPN" SG_ 2365334014 HvessModule83OperationalStatus 22901;
BA_ "SPN" SG_ 2365334014 HvessModule84OperationalStatus 22902;
BA_ "SPN" SG_ 2365334014 HvessModule85OperationalStatus 22903;
BA_ "SPN" SG_ 2365334014 HvessModule86OperationalStatus 22904;
BA_ "SPN" SG_ 2365334014 HvessModule87OperationalStatus 22905;
BA_ "SPN" SG_ 2365334014 HvessModule88OperationalStatus 22906;
BA_ "SPN" SG_ 2365334014 HvessModule89OperationalStatus 22907;
BA_ "SPN" SG_ 2365334014 HvessModule90OperationalStatus 22908;
BA_ "SPN" SG_ 2365334014 HvessModule91OperationalStatus 22909;
BA_ "SPN" SG_ 2365334014 HvessModule92OperationalStatus 22910;
BA_ "SPN" SG_ 2365334014 HvessModule93OperationalStatus 22911;
BA_ "SPN" SG_ 2365334014 HvessModule94OperationalStatus 22912;
BA_ "SPN" SG_ 2365334014 HvessModule95OperationalStatus 22913;
BA_ "SPN" SG_ 2365334014 HvessModule96OperationalStatus 22914;
BA_ "SPN" SG_ 2566662398 CrrntRdwVhlSpdLmtMd 22770;
BA_ "SPN" SG_ 2566662398 SltdRdwVhlSpdLmt 22771;
BA_ "SPN" SG_ 2566662398 CurrentRoadwayVehicleSpeedLimit 22772;
BA_ "SPN" SG_ 2566662398 MapBasedVehicleSpeedLimit 22773;
BA_ "SPN" SG_ 2566662398 CrrntRdwVhlSpdLmtDgrdtnStts 23728;
BA_ "SPN" SG_ 2365342974 HvssNmnlDshrgCrrntLmt 22849;
BA_ "SPN" SG_ 2365342974 HvessNominalChargeCurrentLimit 22850;
BA_ "SPN" SG_ 2566522622 PrdtvVhlSpdAdjstmntIndtrStt 23121;
BA_ "SPN" SG_ 2566522622 PrdtvVhlSpdAdjstmntSpd 23122;
BA_ "SPN" SG_ 2566523134 ReferenceTime 23069;
BA_ "SPN" SG_ 2566523134 ReferenceTimeFractional 23070;
BA_ "SPN" SG_ 2566523134 TimeEpoch 23071;
BA_ "SPN" SG_ 2566523134 TimeTxReason 23072;
BA_ "SPN" SG_ 2566523390 TotalSoftwareDistance 23060;
BA_ "SPN" SG_ 2352938750 FuelCellSystemControlCommandCrc 23147;
BA_ "SPN" SG_ 2352938750 FlCllSstmCntrlCmmndCntr 23148;
BA_ "SPN" SG_ 2352938750 FuelCellSystemStateCommand 23149;
BA_ "SPN" SG_ 2352938750 FlCllSstmCntrlMdCmmnd 23150;
BA_ "SPN" SG_ 2352938750 FuelCellSystemNetOutputCommand 23151;
BA_ "SPN" SG_ 2352938750 FuelCellSystemPurgeWaterCommand 23152;
BA_ "SPN" SG_ 2353004286 FlCllSstmPwrLmtCmmndCr 23158;
BA_ "SPN" SG_ 2353004286 FlCllSstmPwrLmtCmmndCntr 23159;
BA_ "SPN" SG_ 2353004286 FlCllSstmNtPwrMxmmLmtCmmnd 23160;
BA_ "SPN" SG_ 2353004286 FlCllSstmNtPwrMnmmLmtCmmnd 23161;
BA_ "SPN" SG_ 2353069822 FlCllSstmCrrntLmtCmmndCr 23172;
BA_ "SPN" SG_ 2353069822 FlCllSstmCrrntLmtCmmndCntr 23173;
BA_ "SPN" SG_ 2353069822 FlCllSstmNtCrrntMxmmLmtCmmnd 23174;
BA_ "SPN" SG_ 2353069822 FlCllSstmNtCrrntMnmmLmtCmmnd 23175;
BA_ "SPN" SG_ 2554461950 HdrgnStrgSstmCntrlCmmndCr 23186;
BA_ "SPN" SG_ 2554461950 HdrgnStrgSstmCntrlCmmndCntr 23187;
BA_ "SPN" SG_ 2554461950 HydrogenSupplyRequest 23188;
BA_ "SPN" SG_ 2353200894 TransmissionOverrideControlMode 23369;
BA_ "SPN" SG_ 2353200894 TrnsmssnOvrrdCntrlMdPrrt 23370;
BA_ "SPN" SG_ 2353200894 TrnsmssnRqstdOtptShftSpd 23371;
BA_ "SPN" SG_ 2353200894 TrnsmssnRqstdTrqTrqLmt 23372;
BA_ "SPN" SG_ 2353200894 TrnsmssnAtNtrlAtRtrnEnlSwth 23373;
BA_ "SPN" SG_ 2353200894 TrnsmssnAtNtrlAtRtrnRqst 23374;
BA_ "SPN" SG_ 2353200894 TransmissionControl4Counter 23375;
BA_ "SPN" SG_ 2353200894 TransmissionControl4Crc 23376;
BA_ "SPN" SG_ 2554789630 SelectedEvApiId 23223;
BA_ "SPN" SG_ 2554789630 SelectedEvApiManufacturerId 23224;
BA_ "SPN" SG_ 2554789630 SelectedEvApiDeviceRole 23225;
BA_ "SPN" SG_ 2554789630 SelectedEvApiMajorVersion 23226;
BA_ "SPN" SG_ 2554789630 SelectedEvApiMinorVersion 23227;
BA_ "SPN" SG_ 2364574206 MtrGnrtr1InvrtrCntrlStts3Cr 23447;
BA_ "SPN" SG_ 2364574206 MtrGnrtr1InvrtrCntrlStts3Cntr 23448;
BA_ "SPN" SG_ 2364574206 MotorGenerator1MotorAngle 23449;
BA_ "SPN" SG_ 2364574462 MtrGnrtr2InvrtrCntrlStts3Cr 23450;
BA_ "SPN" SG_ 2364574462 MtrGnrtr2InvrtrCntrlStts3Cntr 23451;
BA_ "SPN" SG_ 2364574462 MotorGenerator2MotorAngle 23452;
BA_ "SPN" SG_ 2364574718 MtrGnrtr3InvrtrCntrlStts3Cr 23453;
BA_ "SPN" SG_ 2364574718 MtrGnrtr3InvrtrCntrlStts3Cntr 23454;
BA_ "SPN" SG_ 2364574718 MotorGenerator3MotorAngle 23455;
BA_ "SPN" SG_ 2364574974 MtrGnrtr4InvrtrCntrlStts3Cr 23456;
BA_ "SPN" SG_ 2364574974 MtrGnrtr4InvrtrCntrlStts3Cntr 23457;
BA_ "SPN" SG_ 2364574974 MotorGenerator4MotorAngle 23458;
BA_ "SPN" SG_ 2364575230 MtrGnrtr5InvrtrCntrlStts3Cr 23459;
BA_ "SPN" SG_ 2364575230 MtrGnrtr5InvrtrCntrlStts3Cntr 23460;
BA_ "SPN" SG_ 2364575230 MotorGenerator5MotorAngle 23461;
BA_ "SPN" SG_ 2364575486 MtrGnrtr6InvrtrCntrlStts3Cr 23462;
BA_ "SPN" SG_ 2364575486 MtrGnrtr6InvrtrCntrlStts3Cntr 23463;
BA_ "SPN" SG_ 2364575486 MotorGenerator6MotorAngle 23464;
BA_ "SPN" SG_ 2364764670 FlCllSstmOprtngInfrmtnCr 23153;
BA_ "SPN" SG_ 2364764670 FlCllSstmOprtngInfrmtnCntr 23154;
BA_ "SPN" SG_ 2364764670 FuelCellSystemNetPower 23155;
BA_ "SPN" SG_ 2364764670 FuelCellSystemNetCurrent 23156;
BA_ "SPN" SG_ 2364764670 FuelCellSystemVoltage 23157;
BA_ "SPN" SG_ 2364764926 FlCllSstmMnmmPwrInfrmtnCr 23162;
BA_ "SPN" SG_ 2364764926 FlCllSstmMnmmPwrInfrmtnCntr 23163;
BA_ "SPN" SG_ 2364764926 FlCllSstmAtlMnmmAvllNtPwr 23164;
BA_ "SPN" SG_ 2364764926 FlCllSstmIntrnlMnmmAvllNtPwr 23165;
BA_ "SPN" SG_ 2364764926 FCSstAtMAvNtPwSAddss 23166;
BA_ "SPN" SG_ 2364765182 FlCllSstmMxmmPwrInfrmtnCr 23167;
BA_ "SPN" SG_ 2364765182 FlCllSstmMxmmPwrInfrmtnCntr 23168;
BA_ "SPN" SG_ 2364765182 FlCllSstmAtlMxmmAvllNtPwr 23169;
BA_ "SPN" SG_ 2364765182 FlCllSstmIntrnlMxmmAvllNtPwr 23170;
BA_ "SPN" SG_ 2364765182 FCSstAtMxAvNtPwSAddss 23171;
BA_ "SPN" SG_ 2364765438 FlCllSstmMnmmCrrntInfrmtnCr 23176;
BA_ "SPN" SG_ 2364765438 FlCllSstmMnmmCrrntInfrmtnCntr 23177;
BA_ "SPN" SG_ 2364765438 FlCllSstmAtlMnmmAvllNtCrrnt 23178;
BA_ "SPN" SG_ 2364765438 FlCllSstmIntrnlMnmmAvllNtCrrnt 23179;
BA_ "SPN" SG_ 2364765438 FCSstAtMAvNtCtSAddss 23180;
BA_ "SPN" SG_ 2364765694 FlCllSstmMxmmCrrntInfrmtnCr 23181;
BA_ "SPN" SG_ 2364765694 FlCllSstmMxmmCrrntInfrmtnCntr 23182;
BA_ "SPN" SG_ 2364765694 FlCllSstmAtlMxmmAvllNtCrrnt 23183;
BA_ "SPN" SG_ 2364765694 FlCllSstmIntrnlMxmmAvllNtCrrnt 23184;
BA_ "SPN" SG_ 2364765694 FCSstAtMxAvNtCtSAddss 23185;
BA_ "SPN" SG_ 2566092542 HdrgnStrgSstmInfrmtnCr 23189;
BA_ "SPN" SG_ 2566092542 HdrgnStrgSstmInfrmtnCntr 23190;
BA_ "SPN" SG_ 2566092542 HydrogenSupplyActiveStatus 23191;
BA_ "SPN" SG_ 2566092798 FuelCellSystemOperatingStateCrc 23192;
BA_ "SPN" SG_ 2566092798 FlCllSstmOprtngSttCntr 23193;
BA_ "SPN" SG_ 2566092798 FlCllSstmCldStrtAtvStts 23194;
BA_ "SPN" SG_ 2566092798 FuelCellSystemControlMode 23195;
BA_ "SPN" SG_ 2566092798 FuelCellSystemOperationState 23196;
BA_ "SPN" SG_ 2566092798 FuelCellSystemFaultLevel 23197;
BA_ "SPN" SG_ 2566092798 FuelCellSystemHvilStatus 23734;
BA_ "SPN" SG_ 2566092798 FlCllSstmFltdShtdwnTp 23889;
BA_ "SPN" SG_ 2566093054 FlCllSstmOprtnsRqstCr 23198;
BA_ "SPN" SG_ 2566093054 FlCllSstmOprtnsRqstCntr 23199;
BA_ "SPN" SG_ 2566093054 FCSstHVtPwSppItCd 23200;
BA_ "SPN" SG_ 2566093310 FuelCellStackCurrent 23210;
BA_ "SPN" SG_ 2566093310 FuelCellStackVoltage 23211;
BA_ "SPN" SG_ 2566093566 FlCllSstmClntFn1Vltg 23240;
BA_ "SPN" SG_ 2566093566 FlCllSstmClntFn1Crrnt 23241;
BA_ "SPN" SG_ 2566093566 FlCllSstmClntFn1HvlStts 23242;
BA_ "SPN" SG_ 2566093566 FlCllSstmClntFn1PrntSpdStts 23243;
BA_ "SPN" SG_ 2566093566 FlCllSstmClntFn1PrntSpd 23244;
BA_ "SPN" SG_ 2566093822 FlCllSstmClntFn2Vltg 23257;
BA_ "SPN" SG_ 2566093822 FlCllSstmClntFn2Crrnt 23258;
BA_ "SPN" SG_ 2566093822 FlCllSstmClntFn2HvlStts 23259;
BA_ "SPN" SG_ 2566093822 FlCllSstmClntFn2PrntSpdStts 23260;
BA_ "SPN" SG_ 2566093822 FlCllSstmClntFn2PrntSpd 23261;
BA_ "SPN" SG_ 2566094078 FlCllSstmClntFn3Vltg 23274;
BA_ "SPN" SG_ 2566094078 FlCllSstmClntFn3Crrnt 23275;
BA_ "SPN" SG_ 2566094078 FlCllSstmClntFn3HvlStts 23276;
BA_ "SPN" SG_ 2566094078 FlCllSstmClntFn3PrntSpdStts 23277;
BA_ "SPN" SG_ 2566094078 FlCllSstmClntFn3PrntSpd 23278;
BA_ "SPN" SG_ 2566094334 FlCllSstmClntFn4Vltg 23291;
BA_ "SPN" SG_ 2566094334 FlCllSstmClntFn4Crrnt 23292;
BA_ "SPN" SG_ 2566094334 FlCllSstmClntFn4HvlStts 23293;
BA_ "SPN" SG_ 2566094334 FlCllSstmClntFn4PrntSpdStts 23294;
BA_ "SPN" SG_ 2566094334 FlCllSstmClntFn4PrntSpd 23295;
BA_ "SPN" SG_ 2566094590 HvessCoolantPump1Voltage 23421;
BA_ "SPN" SG_ 2566094590 HvessCoolantPump1Current 23422;
BA_ "SPN" SG_ 2566094590 HvessCoolantPump1HvilStatus 23423;
BA_ "SPN" SG_ 2566094590 HvssClntPmp1PrntSpdStts 23424;
BA_ "SPN" SG_ 2566094590 HvessCoolantPump1PercentSpeed 23425;
BA_ "SPN" SG_ 2566094846 HvessCoolantPump2Voltage 23438;
BA_ "SPN" SG_ 2566094846 HvessCoolantPump2Current 23439;
BA_ "SPN" SG_ 2566094846 HvessCoolantPump2HvilStatus 23440;
BA_ "SPN" SG_ 2566094846 HvssClntPmp2PrntSpdStts 23441;
BA_ "SPN" SG_ 2566094846 HvessCoolantPump2PercentSpeed 23442;
BA_ "SPN" SG_ 2566511870 HvssTMtSstC1CpssDsAstPss 23401;
BA_ "SPN" SG_ 2566511870 HvssTMtSstC1CpssStAstPss 23402;
BA_ "SPN" SG_ 2566511870 HvssTMtSstC1OttCtTpt 23403;
BA_ "SPN" SG_ 2566511870 HvssTMtSstC1CVvPst 23404;
BA_ "SPN" SG_ 2566512126 HvssTMtSstC2CpssDsAstPss 23405;
BA_ "SPN" SG_ 2566512126 HvssTMtSstC2CpssStAstPss 23406;
BA_ "SPN" SG_ 2566512126 HvssTMtSstC2OttCtTpt 23407;
BA_ "SPN" SG_ 2566512126 HvssTMtSstC2CVvPst 23408;
BA_ "SPN" SG_ 2566512382 HvssTMtSstC3CpssDsAstPss 23409;
BA_ "SPN" SG_ 2566512382 HvssTMtSstC3CpssStAstPss 23410;
BA_ "SPN" SG_ 2566512382 HvssTMtSstC3OttCtTpt 23411;
BA_ "SPN" SG_ 2566512382 HvssTMtSstC3CVvPst 23412;
BA_ "SPN" SG_ 2566512638 HvssClntPmp1MtrSpdStts 23413;
BA_ "SPN" SG_ 2566512638 HvssClntPmp1CntrllrSttsRsnCd 23414;
BA_ "SPN" SG_ 2566512638 HvssClntPmp1CntrllrCmmndStts 23415;
BA_ "SPN" SG_ 2566512638 HvessCoolantPump1MotorSpeed 23416;
BA_ "SPN" SG_ 2566512638 HvssClntPmp1CntrlTmprtr 23417;
BA_ "SPN" SG_ 2566512638 HvessCoolantPump1Power 23418;
BA_ "SPN" SG_ 2566512638 HvssClntPmp1SrvIndtr 23419;
BA_ "SPN" SG_ 2566512638 HvssClntPmp1OprtngStts 23420;
BA_ "SPN" SG_ 2566512894 HvessCoolantPump1EnableCommand 23426;
BA_ "SPN" SG_ 2566512894 HvessCoolantPump1PowerHold 23427;
BA_ "SPN" SG_ 2566512894 HvessCoolantPump1SpeedCommand 23428;
BA_ "SPN" SG_ 2566512894 HvssClntPmp1PrntSpdCmmnd 23429;
BA_ "SPN" SG_ 2566512894 HvssCtPp1CdEdddIttSppt 23559;
BA_ "SPN" SG_ 2566512894 HvessCoolantPump1CommandCounter 23560;
BA_ "SPN" SG_ 2566512894 HvessCoolantPump1CommandCrc 23561;
BA_ "SPN" SG_ 2566513150 HvssClntPmp2MtrSpdStts 23430;
BA_ "SPN" SG_ 2566513150 HvssClntPmp2CntrllrSttsRsnCd 23431;
BA_ "SPN" SG_ 2566513150 HvssClntPmp2CntrllrCmmndStts 23432;
BA_ "SPN" SG_ 2566513150 HvessCoolantPump2MotorSpeed 23433;
BA_ "SPN" SG_ 2566513150 HvssClntPmp2CntrlTmprtr 23434;
BA_ "SPN" SG_ 2566513150 HvessCoolantPump2Power 23435;
BA_ "SPN" SG_ 2566513150 HvssClntPmp2SrvIndtr 23436;
BA_ "SPN" SG_ 2566513150 HvssClntPmp2OprtngStts 23437;
BA_ "SPN" SG_ 2566513406 HvessCoolantPump2EnableCommand 23443;
BA_ "SPN" SG_ 2566513406 HvessCoolantPump2PowerHold 23444;
BA_ "SPN" SG_ 2566513406 HvessCoolantPump2SpeedCommand 23445;
BA_ "SPN" SG_ 2566513406 HvssClntPmp2PrntSpdCmmnd 23446;
BA_ "SPN" SG_ 2566513406 HvssCtPp2CdEdddIttSppt 23562;
BA_ "SPN" SG_ 2566513406 HvessCoolantPump2CommandCounter 23563;
BA_ "SPN" SG_ 2566513406 HvessCoolantPump2CommandCrc 23564;
BA_ "SPN" SG_ 2365187070 HydrogenInformationCrc 23395;
BA_ "SPN" SG_ 2365187070 HydrogenInformationCounter 23396;
BA_ "SPN" SG_ 2365187070 HydrogenConcentration 23397;
BA_ "SPN" SG_ 2365187070 HdrgnCnntrtnPrlmnrFm 23398;
BA_ "SPN" SG_ 2566514174 OprtrIndmntVhlSpdDrt 23380;
BA_ "SPN" SG_ 2566514174 OprtrIndmntNxtVhlSpdDrt 23381;
BA_ "SPN" SG_ 2566514174 OprtrIndmntTmTNxtVhlSpdDrt 23382;
BA_ "SPN" SG_ 2566514942 EngineProtectionTorqueReduction 23723;
BA_ "SPN" SG_ 2566515198 AttttDsExstFdCtCsptRt 23392;
BA_ "SPN" SG_ 2566515198 AttttDsExstFdPvsCsptRt 23393;
BA_ "SPN" SG_ 2633624318 NumberOfJ20123ByteDtcs 23363;
BA_ "SPN" SG_ 2633624318 J20123ByteDtcOccurrenceCount 23367;
BA_ "SPN" SG_ 2633624318 J20123ByteDtcStatus 23368;
BA_ "SPN" SG_ 2633624318 J20123ByteDtcBaseCode 23364;
BA_ "SPN" SG_ 2633624318 J20123ByteDtcDelimiter 23365;
BA_ "SPN" SG_ 2633624318 J20123ByteDtcFailureType 23366;
